VERSION "HNNBNNNYNNNNNNNNNNNNNNNNNNNNNNNNNNNNNNNNNN/4/%%%/4/'%**4NNN///"

NS_ :

BS_:

BU_: AAG BCM1 BCM2 ELV Gateway HDSG IEZS MFG MSBBR SAD SAD2 Schwerpanzer_Zusatz SitzMem_BFS SitzMem_FS SitzMem_HBFS SitzMem_HFS SitzMem_SR3 SpoilerSG TSG_BFS TSG_FS VSG VTS DK_Dummy

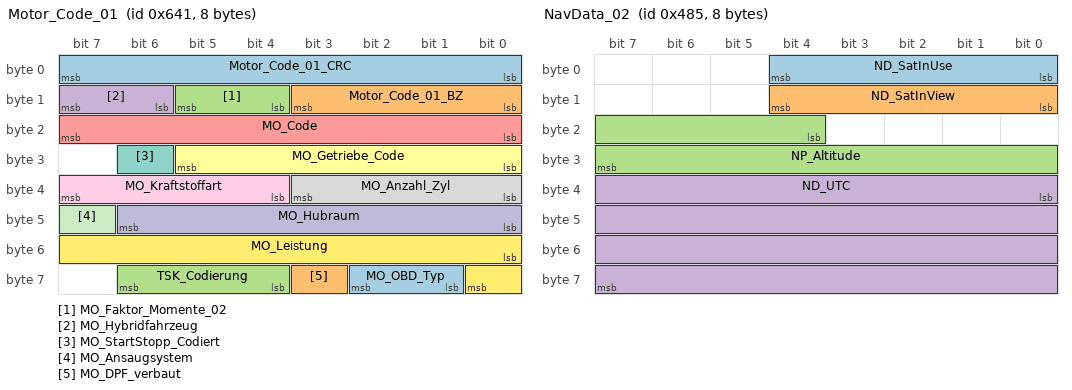
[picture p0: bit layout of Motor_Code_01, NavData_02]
BO_ 1601 Motor_Code_01: 8 Gateway
 SG_ Motor_Code_01_CRC : 0|8@1+ (1,0) [0|255] "" Vector__XXX
 SG_ Motor_Code_01_BZ : 8|4@1+ (1,0) [0|15] "" Vector__XXX
 SG_ MO_Faktor_Momente_02 : 12|2@1+ (1,0) [1|3] "Unit_NewtoMeter"  BCM1
 SG_ MO_Hybridfahrzeug : 14|2@1+ (1,0) [0|3] "" Vector__XXX
 SG_ MO_Code : 16|8@1+ (1,0) [0|255] "" Vector__XXX
 SG_ MO_Getriebe_Code : 24|6@1+ (1,0) [0|63] "" Vector__XXX
 SG_ MO_StartStopp_Codiert : 30|1@1+ (1,0) [0|1] "" Vector__XXX
 SG_ MO_Anzahl_Zyl : 32|4@1+ (1,0) [0|15] "" Vector__XXX
 SG_ MO_Kraftstoffart : 36|4@1+ (1,0) [0|15] ""  VTS
 SG_ MO_Hubraum : 40|7@1+ (0.1,0) [0|12.7] "Unit_Liter" Vector__XXX
 SG_ MO_Ansaugsystem : 47|1@1+ (1,0) [0|1] "" Vector__XXX
 SG_ MO_Leistung : 48|9@1+ (1,0) [0|511] "Unit_KiloWatt" Vector__XXX
 SG_ MO_OBD_Typ : 57|2@1+ (1,0) [0|3] "" Vector__XXX
 SG_ MO_DPF_verbaut : 59|1@1+ (1,0) [0|1] "" Vector__XXX
 SG_ TSK_Codierung : 60|3@1+ (1,0) [0|7] "" Vector__XXX

BO_ 394 Motor_Hybrid_11: 8 Gateway
 SG_ MO_Ablaufstatus : 12|4@1+ (1,0) [0|15] "" Vector__XXX
 SG_ MO_Ablaufstrg_Betriebszustand : 16|3@1+ (1,0) [0|7] "" Vector__XXX
 SG_ MO_Ablaufstrg_Zustand_VKM_Ist : 19|1@1+ (1,0) [0|1] "" Vector__XXX
 SG_ MO_Ablaufstrg_Kraftschluss_Ist : 20|1@1+ (1,0) [0|1] "" Vector__XXX
 SG_ MO_Ablaufstrg_Zustand_K0_Ist : 21|1@1+ (1,0) [0|1] "" Vector__XXX
 SG_ MO_Ablaufstrg_Kraftschluss2_Ist : 22|1@1+ (1,0) [0|1] "" Vector__XXX
 SG_ MO_Ablaufstrg_Zustand_VKM_Ziel : 24|1@1+ (1,0) [0|1] "" Vector__XXX
 SG_ MO_Ablaufstrg_Kraftschluss_Ziel : 25|1@1+ (1,0) [0|1] "" Vector__XXX
 SG_ MO_Ablaufstrg_Zustand_K0_Ziel : 26|1@1+ (1,0) [0|1] "" Vector__XXX
 SG_ MO_Ablaufstrg_Kraftschluss2_Ziel : 27|1@1+ (1,0) [0|1] "" Vector__XXX
 SG_ MO_Auth_Aufforderung_WFS : 29|1@1+ (1,0) [0|1] "" Vector__XXX
 SG_ MO_Start_Dynamik : 30|3@1+ (1,0) [0|7] "" Vector__XXX
 SG_ MO_Start_Art : 33|3@1+ (1,0) [0|7] ""  AAG,BCM1,BCM2
 SG_ MO_Abstellposition_02 : 36|8@1+ (2,0) [0|508] "Unit_DegreOfArc" Vector__XXX
 SG_ MO_Mom_Freiheit_Sekundaerachse : 44|1@1+ (1,0) [0|1] "" Vector__XXX
 SG_ MO_Nachlaufzeit_Kuehlerluefter : 45|6@1+ (15,0) [0|945] "Unit_Secon" Vector__XXX
 SG_ MO_Tankklappensteuerung : 51|2@1+ (1,0) [0|3] ""  BCM2
 SG_ MO_HYB_E_Faktor : 53|4@1+ (1,0) [0|15] "" Vector__XXX

BO_ 1157 NavData_02: 8 Gateway
 SG_ ND_SatInUse : 0|5@1+ (1,0) [0|29] "" Vector__XXX
 SG_ ND_SatInView : 8|5@1+ (1,0) [0|29] "" Vector__XXX
 SG_ NP_Altitude : 20|12@1+ (2,-500) [-500|7686] "Unit_Meter"  VTS
 SG_ ND_UTC : 32|32@1+ (1,0) [0|4294967293] "Unit_Secon" Vector__XXX

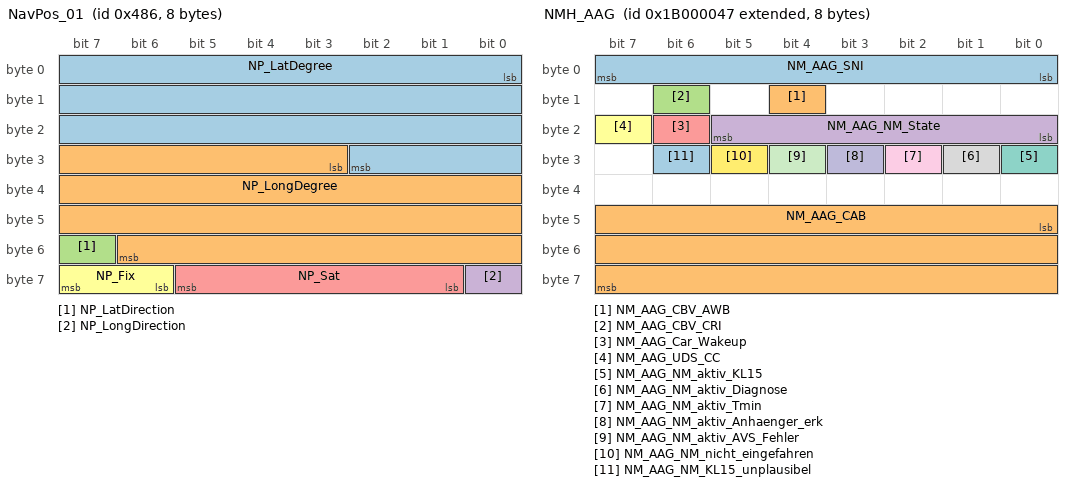
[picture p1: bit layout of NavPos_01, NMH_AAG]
BO_ 1158 NavPos_01: 8 Gateway
 SG_ NP_LatDegree : 0|27@1+ (1E-006,0) [0|90] "Unit_DegreOfArc"  VTS
 SG_ NP_LongDegree : 27|28@1+ (1E-006,0) [0|180] "Unit_DegreOfArc"  VTS
 SG_ NP_LatDirection : 55|1@1+ (1,0) [0|1] ""  VTS
 SG_ NP_LongDirection : 56|1@1+ (1,0) [0|1] ""  VTS
 SG_ NP_Sat : 57|5@1+ (1,0) [0|29] ""  VTS
 SG_ NP_Fix : 62|2@1+ (1,0) [0|3] ""  VTS

BO_ 2589283496 NavPos_02_Map_Matched: 8 Gateway
 SG_ POS_MUX M : 0|2@1+ (1,0) [0|3] ""  VTS
 SG_ POS_ODD_EVEN : 2|1@1+ (1,0) [0|1] ""  VTS
 SG_ POS_PosStati m0 : 3|4@1+ (1,0) [0|15] ""  VTS
 SG_ POS_Heading m1 : 4|12@1+ (0.1,0) [0|409.5] "Unit_DegreOfArc"  VTS
 SG_ POS_LatDirection m0 : 7|1@1+ (1,0) [0|1] ""  VTS
 SG_ POS_LatDegree m0 : 8|27@1+ (1E-006,0) [0|90] "Unit_DegreOfArc"  VTS
 SG_ POS_Last_GPS_Sync m1 : 16|14@1+ (1,0) [0|16383] "Unit_Secon"  VTS
 SG_ POS_Heading_Trust m1 : 30|2@1+ (1,0) [0|3] ""  VTS
 SG_ POS_UTC_REF m1 : 32|32@1+ (1,0) [0|4294967295] "Unit_Secon"  VTS
 SG_ POS_LongDirection m0 : 35|1@1+ (1,0) [0|1] ""  VTS
 SG_ POS_LongDegree m0 : 36|28@1+ (1E-006,0) [0|180] "Unit_DegreOfArc"  VTS

BO_ 2600468551 NMH_AAG: 8 AAG
 SG_ NM_AAG_SNI : 0|8@1+ (1,0) [0|255] ""  AAG,BCM1,BCM2,ELV,Gateway,HDSG,IEZS,MFG,MSBBR,SAD,SAD2,SitzMem_BFS,SitzMem_FS,SitzMem_HBFS,SitzMem_HFS,SitzMem_SR3,SpoilerSG,TSG_BFS,TSG_FS,VSG,VTS
 SG_ NM_AAG_CBV_AWB : 12|1@1+ (1,0) [0|1] ""  Gateway
 SG_ NM_AAG_CBV_CRI : 14|1@1+ (1,0) [0|1] ""  AAG,BCM1,BCM2,ELV,Gateway,HDSG,IEZS,MFG,MSBBR,SAD,SAD2,SitzMem_BFS,SitzMem_FS,SitzMem_HBFS,SitzMem_HFS,SitzMem_SR3,SpoilerSG,TSG_BFS,TSG_FS,VSG,VTS
 SG_ NM_AAG_NM_State : 16|6@1+ (1,0) [0|63] "" Vector__XXX
 SG_ NM_AAG_Car_Wakeup : 22|1@1+ (1,0) [0|1] ""  Gateway
 SG_ NM_AAG_UDS_CC : 23|1@1+ (1,0) [0|1] "" Vector__XXX
 SG_ NM_AAG_NM_aktiv_KL15 : 24|1@1+ (1,0) [0|1] "" Vector__XXX
 SG_ NM_AAG_NM_aktiv_Diagnose : 25|1@1+ (1,0) [0|1] "" Vector__XXX
 SG_ NM_AAG_NM_aktiv_Tmin : 26|1@1+ (1,0) [0|1] "" Vector__XXX
 SG_ NM_AAG_NM_aktiv_Anhaenger_erk : 27|1@1+ (1,0) [0|1] "" Vector__XXX
 SG_ NM_AAG_NM_aktiv_AVS_Fehler : 28|1@1+ (1,0) [0|1] "" Vector__XXX
 SG_ NM_AAG_NM_nicht_eingefahren : 29|1@1+ (1,0) [0|1] "" Vector__XXX
 SG_ NM_AAG_NM_KL15_unplausibel : 30|1@1+ (1,0) [0|1] "" Vector__XXX
 SG_ NM_AAG_CAB : 40|24@1+ (1,0) [0|16777215] ""  AAG,BCM1,BCM2,ELV,Gateway,HDSG,IEZS,MFG,MSBBR,SAD,SAD2,SitzMem_BFS,SitzMem_FS,SitzMem_HBFS,SitzMem_HFS,SitzMem_SR3,SpoilerSG,TSG_BFS,TSG_FS,VSG,VTS

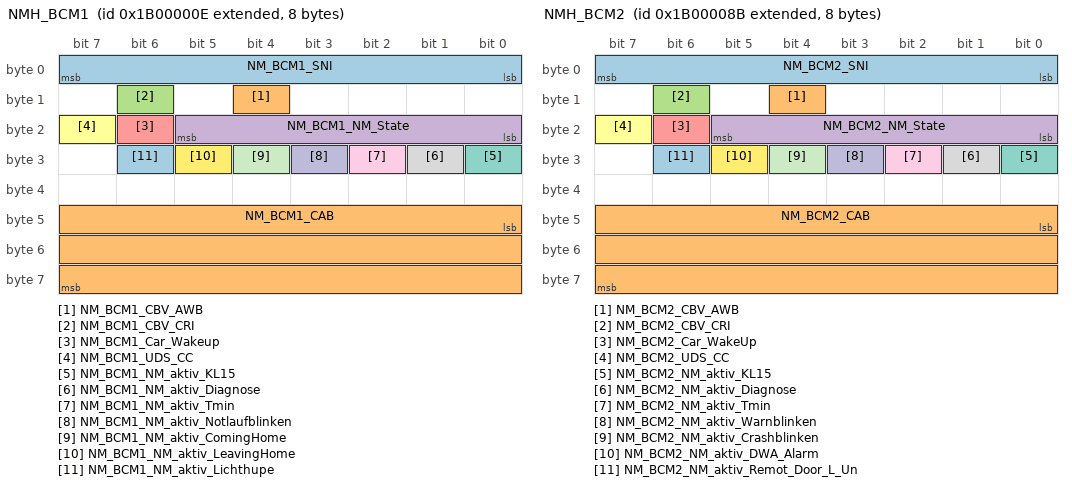
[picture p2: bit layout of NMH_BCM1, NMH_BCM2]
BO_ 2600468494 NMH_BCM1: 8 BCM1
 SG_ NM_BCM1_SNI : 0|8@1+ (1,0) [0|255] ""  AAG,BCM1,BCM2,ELV,Gateway,HDSG,IEZS,MFG,MSBBR,SAD,SAD2,SitzMem_BFS,SitzMem_FS,SitzMem_HBFS,SitzMem_HFS,SitzMem_SR3,SpoilerSG,TSG_BFS,TSG_FS,VSG,VTS
 SG_ NM_BCM1_CBV_AWB : 12|1@1+ (1,0) [0|1] ""  Gateway
 SG_ NM_BCM1_CBV_CRI : 14|1@1+ (1,0) [0|1] ""  AAG,BCM1,BCM2,ELV,Gateway,HDSG,IEZS,MFG,MSBBR,SAD,SAD2,SitzMem_BFS,SitzMem_FS,SitzMem_HBFS,SitzMem_HFS,SitzMem_SR3,SpoilerSG,TSG_BFS,TSG_FS,VSG,VTS
 SG_ NM_BCM1_NM_State : 16|6@1+ (1,0) [0|63] "" Vector__XXX
 SG_ NM_BCM1_Car_Wakeup : 22|1@1+ (1,0) [0|1] ""  Gateway
 SG_ NM_BCM1_UDS_CC : 23|1@1+ (1,0) [0|1] "" Vector__XXX
 SG_ NM_BCM1_NM_aktiv_KL15 : 24|1@1+ (1,0) [0|1] "" Vector__XXX
 SG_ NM_BCM1_NM_aktiv_Diagnose : 25|1@1+ (1,0) [0|1] "" Vector__XXX
 SG_ NM_BCM1_NM_aktiv_Tmin : 26|1@1+ (1,0) [0|1] "" Vector__XXX
 SG_ NM_BCM1_NM_aktiv_Notlaufblinken : 27|1@1+ (1,0) [0|1] "" Vector__XXX
 SG_ NM_BCM1_NM_aktiv_ComingHome : 28|1@1+ (1,0) [0|1] "" Vector__XXX
 SG_ NM_BCM1_NM_aktiv_LeavingHome : 29|1@1+ (1,0) [0|1] "" Vector__XXX
 SG_ NM_BCM1_NM_aktiv_Lichthupe : 30|1@1+ (1,0) [0|1] "" Vector__XXX
 SG_ NM_BCM1_CAB : 40|24@1+ (1,0) [0|16777215] ""  AAG,BCM1,BCM2,ELV,Gateway,HDSG,IEZS,MFG,MSBBR,SAD,SAD2,SitzMem_BFS,SitzMem_FS,SitzMem_HBFS,SitzMem_HFS,SitzMem_SR3,SpoilerSG,TSG_BFS,TSG_FS,VSG,VTS

BO_ 2600468619 NMH_BCM2: 8 BCM2
 SG_ NM_BCM2_SNI : 0|8@1+ (1,0) [0|255] ""  AAG,BCM1,BCM2,ELV,Gateway,HDSG,IEZS,MFG,MSBBR,SAD,SAD2,SitzMem_BFS,SitzMem_FS,SitzMem_HBFS,SitzMem_HFS,SitzMem_SR3,SpoilerSG,TSG_BFS,TSG_FS,VSG,VTS
 SG_ NM_BCM2_CBV_AWB : 12|1@1+ (1,0) [0|1] ""  Gateway
 SG_ NM_BCM2_CBV_CRI : 14|1@1+ (1,0) [0|1] ""  AAG,BCM1,BCM2,ELV,Gateway,HDSG,IEZS,MFG,MSBBR,SAD,SAD2,SitzMem_BFS,SitzMem_FS,SitzMem_HBFS,SitzMem_HFS,SitzMem_SR3,SpoilerSG,TSG_BFS,TSG_FS,VSG,VTS
 SG_ NM_BCM2_NM_State : 16|6@1+ (1,0) [0|63] "" Vector__XXX
 SG_ NM_BCM2_Car_WakeUp : 22|1@1+ (1,0) [0|1] ""  Gateway
 SG_ NM_BCM2_UDS_CC : 23|1@1+ (1,0) [0|1] "" Vector__XXX
 SG_ NM_BCM2_NM_aktiv_KL15 : 24|1@1+ (1,0) [0|1] "" Vector__XXX
 SG_ NM_BCM2_NM_aktiv_Diagnose : 25|1@1+ (1,0) [0|1] "" Vector__XXX
 SG_ NM_BCM2_NM_aktiv_Tmin : 26|1@1+ (1,0) [0|1] "" Vector__XXX
 SG_ NM_BCM2_NM_aktiv_Warnblinken : 27|1@1+ (1,0) [0|1] "" Vector__XXX
 SG_ NM_BCM2_NM_aktiv_Crashblinken : 28|1@1+ (1,0) [0|1] "" Vector__XXX
 SG_ NM_BCM2_NM_aktiv_DWA_Alarm : 29|1@1+ (1,0) [0|1] "" Vector__XXX
 SG_ NM_BCM2_NM_aktiv_Remot_Door_L_Un : 30|1@1+ (1,0) [0|1] "" Vector__XXX
 SG_ NM_BCM2_CAB : 40|24@1+ (1,0) [0|16777215] ""  AAG,BCM1,BCM2,ELV,Gateway,HDSG,IEZS,MFG,MSBBR,SAD,SAD2,SitzMem_BFS,SitzMem_FS,SitzMem_HBFS,SitzMem_HFS,SitzMem_SR3,SpoilerSG,TSG_BFS,TSG_FS,VSG,VTS

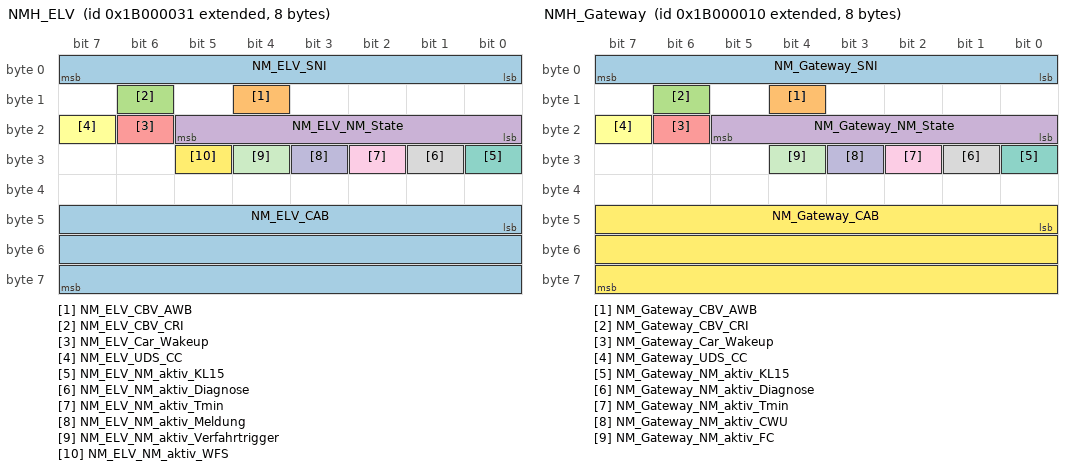
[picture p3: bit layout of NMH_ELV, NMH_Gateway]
BO_ 2600468529 NMH_ELV: 8 ELV
 SG_ NM_ELV_SNI : 0|8@1+ (1,0) [0|255] ""  AAG,BCM1,BCM2,ELV,Gateway,HDSG,IEZS,MFG,MSBBR,SAD,SAD2,SitzMem_BFS,SitzMem_FS,SitzMem_HBFS,SitzMem_HFS,SitzMem_SR3,SpoilerSG,TSG_BFS,TSG_FS,VSG,VTS
 SG_ NM_ELV_CBV_AWB : 12|1@1+ (1,0) [0|1] ""  Gateway
 SG_ NM_ELV_CBV_CRI : 14|1@1+ (1,0) [0|1] ""  AAG,BCM1,BCM2,ELV,Gateway,HDSG,IEZS,MFG,MSBBR,SAD,SAD2,SitzMem_BFS,SitzMem_FS,SitzMem_HBFS,SitzMem_HFS,SitzMem_SR3,SpoilerSG,TSG_BFS,TSG_FS,VSG,VTS
 SG_ NM_ELV_NM_State : 16|6@1+ (1,0) [0|63] "" Vector__XXX
 SG_ NM_ELV_Car_Wakeup : 22|1@1+ (1,0) [0|1] ""  Gateway
 SG_ NM_ELV_UDS_CC : 23|1@1+ (1,0) [0|1] "" Vector__XXX
 SG_ NM_ELV_NM_aktiv_KL15 : 24|1@1+ (1,0) [0|1] "" Vector__XXX
 SG_ NM_ELV_NM_aktiv_Diagnose : 25|1@1+ (1,0) [0|1] "" Vector__XXX
 SG_ NM_ELV_NM_aktiv_Tmin : 26|1@1+ (1,0) [0|1] "" Vector__XXX
 SG_ NM_ELV_NM_aktiv_Meldung : 27|1@1+ (1,0) [0|1] "" Vector__XXX
 SG_ NM_ELV_NM_aktiv_Verfahrtrigger : 28|1@1+ (1,0) [0|1] "" Vector__XXX
 SG_ NM_ELV_NM_aktiv_WFS : 29|1@1+ (1,0) [0|1] "" Vector__XXX
 SG_ NM_ELV_CAB : 40|24@1+ (1,0) [0|16777215] ""  AAG,BCM1,BCM2,ELV,Gateway,HDSG,IEZS,MFG,MSBBR,SAD,SAD2,SitzMem_BFS,SitzMem_FS,SitzMem_HBFS,SitzMem_HFS,SitzMem_SR3,SpoilerSG,TSG_BFS,TSG_FS,VSG,VTS

BO_ 2600468496 NMH_Gateway: 8 Gateway
 SG_ NM_Gateway_SNI : 0|8@1+ (1,0) [0|255] ""  AAG,BCM1,BCM2,ELV,Gateway,HDSG,IEZS,MFG,MSBBR,SAD,SAD2,SitzMem_BFS,SitzMem_FS,SitzMem_HBFS,SitzMem_HFS,SitzMem_SR3,SpoilerSG,TSG_BFS,TSG_FS,VSG,VTS
 SG_ NM_Gateway_CBV_AWB : 12|1@1+ (1,0) [0|1] "" Vector__XXX
 SG_ NM_Gateway_CBV_CRI : 14|1@1+ (1,0) [0|1] ""  AAG,BCM1,BCM2,ELV,Gateway,HDSG,IEZS,MFG,MSBBR,SAD,SAD2,SitzMem_BFS,SitzMem_FS,SitzMem_HBFS,SitzMem_HFS,SitzMem_SR3,SpoilerSG,TSG_BFS,TSG_FS,VSG,VTS
 SG_ NM_Gateway_NM_State : 16|6@1+ (1,0) [0|63] "" Vector__XXX
 SG_ NM_Gateway_Car_Wakeup : 22|1@1+ (1,0) [0|1] "" Vector__XXX
 SG_ NM_Gateway_UDS_CC : 23|1@1+ (1,0) [0|1] "" Vector__XXX
 SG_ NM_Gateway_NM_aktiv_KL15 : 24|1@1+ (1,0) [0|1] "" Vector__XXX
 SG_ NM_Gateway_NM_aktiv_Diagnose : 25|1@1+ (1,0) [0|1] "" Vector__XXX
 SG_ NM_Gateway_NM_aktiv_Tmin : 26|1@1+ (1,0) [0|1] "" Vector__XXX
 SG_ NM_Gateway_NM_aktiv_CWU : 27|1@1+ (1,0) [0|1] "" Vector__XXX
 SG_ NM_Gateway_NM_aktiv_FC : 28|1@1+ (1,0) [0|1] "" Vector__XXX
 SG_ NM_Gateway_CAB : 40|24@1+ (1,0) [0|16777215] ""  AAG,BCM1,BCM2,ELV,Gateway,HDSG,IEZS,MFG,MSBBR,SAD,SAD2,SitzMem_BFS,SitzMem_FS,SitzMem_HBFS,SitzMem_HFS,SitzMem_SR3,SpoilerSG,TSG_BFS,TSG_FS,VSG,VTS

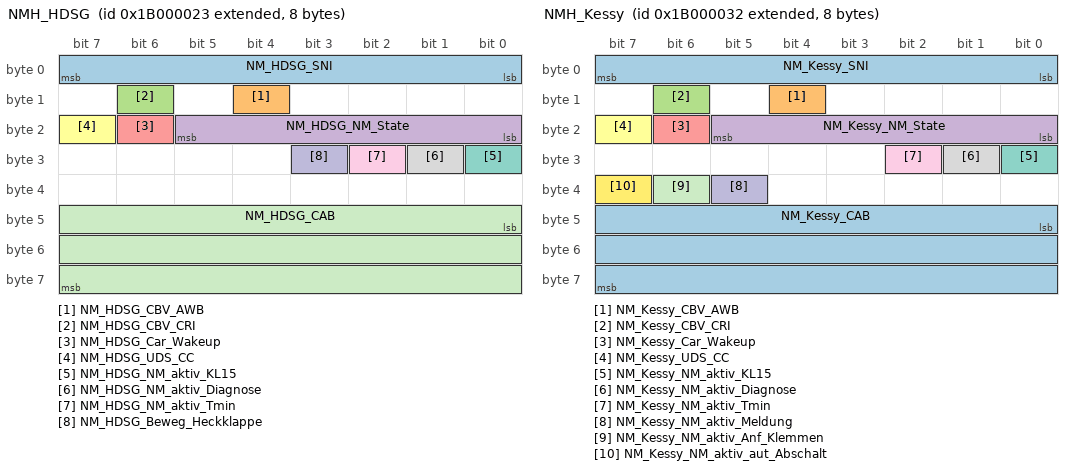
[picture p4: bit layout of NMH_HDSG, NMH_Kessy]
BO_ 2600468515 NMH_HDSG: 8 HDSG
 SG_ NM_HDSG_SNI : 0|8@1+ (1,0) [0|255] ""  AAG,BCM1,BCM2,ELV,Gateway,HDSG,IEZS,MFG,MSBBR,SAD,SAD2,SitzMem_BFS,SitzMem_FS,SitzMem_HBFS,SitzMem_HFS,SitzMem_SR3,SpoilerSG,TSG_BFS,TSG_FS,VSG,VTS
 SG_ NM_HDSG_CBV_AWB : 12|1@1+ (1,0) [0|1] ""  Gateway
 SG_ NM_HDSG_CBV_CRI : 14|1@1+ (1,0) [0|1] ""  AAG,BCM1,BCM2,ELV,Gateway,HDSG,IEZS,MFG,MSBBR,SAD,SAD2,SitzMem_BFS,SitzMem_FS,SitzMem_HBFS,SitzMem_HFS,SitzMem_SR3,SpoilerSG,TSG_BFS,TSG_FS,VSG,VTS
 SG_ NM_HDSG_NM_State : 16|6@1+ (1,0) [0|63] "" Vector__XXX
 SG_ NM_HDSG_Car_Wakeup : 22|1@1+ (1,0) [0|1] ""  Gateway
 SG_ NM_HDSG_UDS_CC : 23|1@1+ (1,0) [0|1] "" Vector__XXX
 SG_ NM_HDSG_NM_aktiv_KL15 : 24|1@1+ (1,0) [0|1] "" Vector__XXX
 SG_ NM_HDSG_NM_aktiv_Diagnose : 25|1@1+ (1,0) [0|1] "" Vector__XXX
 SG_ NM_HDSG_NM_aktiv_Tmin : 26|1@1+ (1,0) [0|1] "" Vector__XXX
 SG_ NM_HDSG_Beweg_Heckklappe : 27|1@1+ (1,0) [0|1] "" Vector__XXX
 SG_ NM_HDSG_CAB : 40|24@1+ (1,0) [0|16777215] ""  AAG,BCM1,BCM2,ELV,Gateway,HDSG,IEZS,MFG,MSBBR,SAD,SAD2,SitzMem_BFS,SitzMem_FS,SitzMem_HBFS,SitzMem_HFS,SitzMem_SR3,SpoilerSG,TSG_BFS,TSG_FS,VSG,VTS

BO_ 2600468530 NMH_Kessy: 8 IEZS
 SG_ NM_Kessy_SNI : 0|8@1+ (1,0) [0|255] ""  AAG,BCM1,BCM2,ELV,Gateway,HDSG,IEZS,MFG,MSBBR,SAD,SAD2,SitzMem_BFS,SitzMem_FS,SitzMem_HBFS,SitzMem_HFS,SitzMem_SR3,SpoilerSG,TSG_BFS,TSG_FS,VSG,VTS
 SG_ NM_Kessy_CBV_AWB : 12|1@1+ (1,0) [0|1] ""  Gateway
 SG_ NM_Kessy_CBV_CRI : 14|1@1+ (1,0) [0|1] ""  AAG,BCM1,BCM2,ELV,Gateway,HDSG,IEZS,MFG,MSBBR,SAD,SAD2,SitzMem_BFS,SitzMem_FS,SitzMem_HBFS,SitzMem_HFS,SitzMem_SR3,SpoilerSG,TSG_BFS,TSG_FS,VSG,VTS
 SG_ NM_Kessy_NM_State : 16|6@1+ (1,0) [0|63] "" Vector__XXX
 SG_ NM_Kessy_Car_Wakeup : 22|1@1+ (1,0) [0|1] ""  Gateway
 SG_ NM_Kessy_UDS_CC : 23|1@1+ (1,0) [0|1] "" Vector__XXX
 SG_ NM_Kessy_NM_aktiv_KL15 : 24|1@1+ (1,0) [0|1] "" Vector__XXX
 SG_ NM_Kessy_NM_aktiv_Diagnose : 25|1@1+ (1,0) [0|1] "" Vector__XXX
 SG_ NM_Kessy_NM_aktiv_Tmin : 26|1@1+ (1,0) [0|1] "" Vector__XXX
 SG_ NM_Kessy_NM_aktiv_Meldung : 37|1@1+ (1,0) [0|1] "" Vector__XXX
 SG_ NM_Kessy_NM_aktiv_Anf_Klemmen : 38|1@1+ (1,0) [0|1] "" Vector__XXX
 SG_ NM_Kessy_NM_aktiv_aut_Abschalt : 39|1@1+ (1,0) [0|1] "" Vector__XXX
 SG_ NM_Kessy_CAB : 40|24@1+ (1,0) [0|16777215] ""  AAG,BCM1,BCM2,ELV,Gateway,HDSG,IEZS,MFG,MSBBR,SAD,SAD2,SitzMem_BFS,SitzMem_FS,SitzMem_HBFS,SitzMem_HFS,SitzMem_SR3,SpoilerSG,TSG_BFS,TSG_FS,VSG,VTS

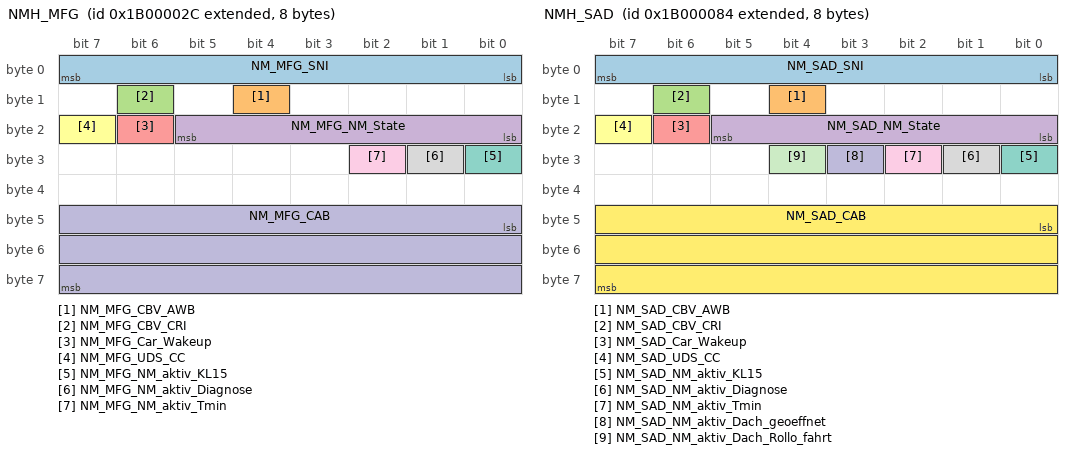
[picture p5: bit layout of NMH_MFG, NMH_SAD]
BO_ 2600468524 NMH_MFG: 8 MFG
 SG_ NM_MFG_SNI : 0|8@1+ (1,0) [0|255] ""  AAG,BCM1,BCM2,ELV,Gateway,HDSG,IEZS,MFG,MSBBR,SAD,SAD2,SitzMem_BFS,SitzMem_FS,SitzMem_HBFS,SitzMem_HFS,SitzMem_SR3,SpoilerSG,TSG_BFS,TSG_FS,VSG,VTS
 SG_ NM_MFG_CBV_AWB : 12|1@1+ (1,0) [0|1] ""  Gateway
 SG_ NM_MFG_CBV_CRI : 14|1@1+ (1,0) [0|1] ""  AAG,BCM1,BCM2,ELV,Gateway,HDSG,IEZS,MFG,MSBBR,SAD,SAD2,SitzMem_BFS,SitzMem_FS,SitzMem_HBFS,SitzMem_HFS,SitzMem_SR3,SpoilerSG,TSG_BFS,TSG_FS,VSG,VTS
 SG_ NM_MFG_NM_State : 16|6@1+ (1,0) [0|63] "" Vector__XXX
 SG_ NM_MFG_Car_Wakeup : 22|1@1+ (1,0) [0|1] ""  Gateway
 SG_ NM_MFG_UDS_CC : 23|1@1+ (1,0) [0|1] "" Vector__XXX
 SG_ NM_MFG_NM_aktiv_KL15 : 24|1@1+ (1,0) [0|1] "" Vector__XXX
 SG_ NM_MFG_NM_aktiv_Diagnose : 25|1@1+ (1,0) [0|1] "" Vector__XXX
 SG_ NM_MFG_NM_aktiv_Tmin : 26|1@1+ (1,0) [0|1] "" Vector__XXX
 SG_ NM_MFG_CAB : 40|24@1+ (1,0) [0|16777215] ""  AAG,BCM1,BCM2,ELV,Gateway,HDSG,IEZS,MFG,MSBBR,SAD,SAD2,SitzMem_BFS,SitzMem_FS,SitzMem_HBFS,SitzMem_HFS,SitzMem_SR3,SpoilerSG,TSG_BFS,TSG_FS,VSG,VTS

BO_ 2600468612 NMH_SAD: 8 SAD
 SG_ NM_SAD_SNI : 0|8@1+ (1,0) [0|255] ""  AAG,BCM1,BCM2,ELV,Gateway,HDSG,IEZS,MFG,MSBBR,SAD,SAD2,SitzMem_BFS,SitzMem_FS,SitzMem_HBFS,SitzMem_HFS,SitzMem_SR3,SpoilerSG,TSG_BFS,TSG_FS,VSG,VTS
 SG_ NM_SAD_CBV_AWB : 12|1@1+ (1,0) [0|1] ""  Gateway
 SG_ NM_SAD_CBV_CRI : 14|1@1+ (1,0) [0|1] ""  AAG,BCM1,BCM2,ELV,Gateway,HDSG,IEZS,MFG,MSBBR,SAD,SAD2,SitzMem_BFS,SitzMem_FS,SitzMem_HBFS,SitzMem_HFS,SitzMem_SR3,SpoilerSG,TSG_BFS,TSG_FS,VSG,VTS
 SG_ NM_SAD_NM_State : 16|6@1+ (1,0) [0|63] "" Vector__XXX
 SG_ NM_SAD_Car_Wakeup : 22|1@1+ (1,0) [0|1] ""  Gateway
 SG_ NM_SAD_UDS_CC : 23|1@1+ (1,0) [0|1] "" Vector__XXX
 SG_ NM_SAD_NM_aktiv_KL15 : 24|1@1+ (1,0) [0|1] "" Vector__XXX
 SG_ NM_SAD_NM_aktiv_Diagnose : 25|1@1+ (1,0) [0|1] "" Vector__XXX
 SG_ NM_SAD_NM_aktiv_Tmin : 26|1@1+ (1,0) [0|1] "" Vector__XXX
 SG_ NM_SAD_NM_aktiv_Dach_geoeffnet : 27|1@1+ (1,0) [0|1] "" Vector__XXX
 SG_ NM_SAD_NM_aktiv_Dach_Rollo_fahrt : 28|1@1+ (1,0) [0|1] "" Vector__XXX
 SG_ NM_SAD_CAB : 40|24@1+ (1,0) [0|16777215] ""  AAG,BCM1,BCM2,ELV,Gateway,HDSG,IEZS,MFG,MSBBR,SAD,SAD2,SitzMem_BFS,SitzMem_FS,SitzMem_HBFS,SitzMem_HFS,SitzMem_SR3,SpoilerSG,TSG_BFS,TSG_FS,VSG,VTS

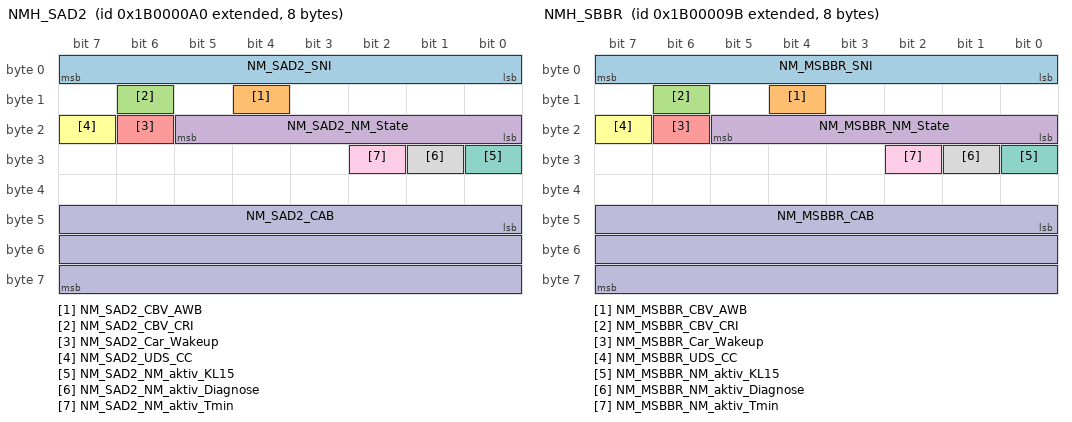
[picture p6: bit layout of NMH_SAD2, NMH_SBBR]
BO_ 2600468640 NMH_SAD2: 8 SAD2
 SG_ NM_SAD2_SNI : 0|8@1+ (1,0) [0|255] ""  AAG,BCM1,BCM2,ELV,Gateway,HDSG,IEZS,MFG,MSBBR,SAD,SAD2,SitzMem_BFS,SitzMem_FS,SitzMem_HBFS,SitzMem_HFS,SitzMem_SR3,SpoilerSG,TSG_BFS,TSG_FS,VSG,VTS
 SG_ NM_SAD2_CBV_AWB : 12|1@1+ (1,0) [0|1] "" Vector__XXX
 SG_ NM_SAD2_CBV_CRI : 14|1@1+ (1,0) [0|1] ""  AAG,BCM1,BCM2,ELV,Gateway,HDSG,IEZS,MFG,MSBBR,SAD,SAD2,SitzMem_BFS,SitzMem_FS,SitzMem_HBFS,SitzMem_HFS,SitzMem_SR3,SpoilerSG,TSG_BFS,TSG_FS,VSG,VTS
 SG_ NM_SAD2_NM_State : 16|6@1+ (1,0) [0|63] "" Vector__XXX
 SG_ NM_SAD2_Car_Wakeup : 22|1@1+ (1,0) [0|1] "" Vector__XXX
 SG_ NM_SAD2_UDS_CC : 23|1@1+ (1,0) [0|1] "" Vector__XXX
 SG_ NM_SAD2_NM_aktiv_KL15 : 24|1@1+ (1,0) [0|1] "" Vector__XXX
 SG_ NM_SAD2_NM_aktiv_Diagnose : 25|1@1+ (1,0) [0|1] "" Vector__XXX
 SG_ NM_SAD2_NM_aktiv_Tmin : 26|1@1+ (1,0) [0|1] "" Vector__XXX
 SG_ NM_SAD2_CAB : 40|24@1+ (1,0) [0|16777215] ""  AAG,BCM1,BCM2,ELV,Gateway,HDSG,IEZS,MFG,MSBBR,SAD,SAD2,SitzMem_BFS,SitzMem_FS,SitzMem_HBFS,SitzMem_HFS,SitzMem_SR3,SpoilerSG,TSG_BFS,TSG_FS,VSG,VTS

BO_ 2600468635 NMH_SBBR: 8 MSBBR
 SG_ NM_MSBBR_SNI : 0|8@1+ (1,0) [0|255] ""  AAG,BCM1,BCM2,ELV,Gateway,HDSG,IEZS,MFG,MSBBR,SAD,SAD2,SitzMem_BFS,SitzMem_FS,SitzMem_HBFS,SitzMem_HFS,SitzMem_SR3,SpoilerSG,TSG_BFS,TSG_FS,VSG,VTS
 SG_ NM_MSBBR_CBV_AWB : 12|1@1+ (1,0) [0|1] "" Vector__XXX
 SG_ NM_MSBBR_CBV_CRI : 14|1@1+ (1,0) [0|1] ""  AAG,BCM1,BCM2,ELV,Gateway,HDSG,IEZS,MFG,MSBBR,SAD,SAD2,SitzMem_BFS,SitzMem_FS,SitzMem_HBFS,SitzMem_HFS,SitzMem_SR3,SpoilerSG,TSG_BFS,TSG_FS,VSG,VTS
 SG_ NM_MSBBR_NM_State : 16|6@1+ (1,0) [0|63] "" Vector__XXX
 SG_ NM_MSBBR_Car_Wakeup : 22|1@1+ (1,0) [0|1] "" Vector__XXX
 SG_ NM_MSBBR_UDS_CC : 23|1@1+ (1,0) [0|1] "" Vector__XXX
 SG_ NM_MSBBR_NM_aktiv_KL15 : 24|1@1+ (1,0) [0|1] "" Vector__XXX
 SG_ NM_MSBBR_NM_aktiv_Diagnose : 25|1@1+ (1,0) [0|1] "" Vector__XXX
 SG_ NM_MSBBR_NM_aktiv_Tmin : 26|1@1+ (1,0) [0|1] "" Vector__XXX
 SG_ NM_MSBBR_CAB : 40|24@1+ (1,0) [0|16777215] ""  AAG,BCM1,BCM2,ELV,Gateway,HDSG,IEZS,MFG,MSBBR,SAD,SAD2,SitzMem_BFS,SitzMem_FS,SitzMem_HBFS,SitzMem_HFS,SitzMem_SR3,SpoilerSG,TSG_BFS,TSG_FS,VSG,VTS

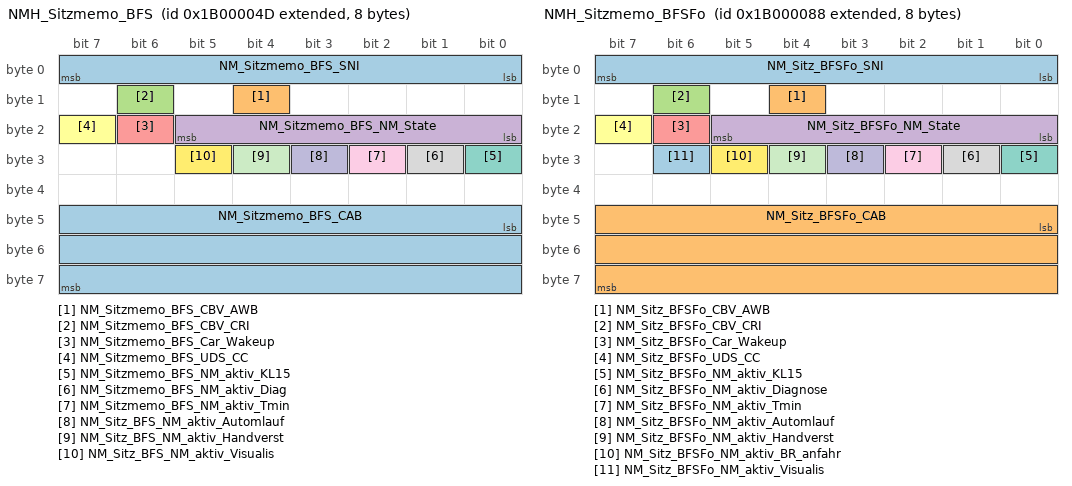
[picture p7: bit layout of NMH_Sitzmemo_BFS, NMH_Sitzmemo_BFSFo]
BO_ 2600468557 NMH_Sitzmemo_BFS: 8 SitzMem_BFS
 SG_ NM_Sitzmemo_BFS_SNI : 0|8@1+ (1,0) [0|255] ""  AAG,BCM1,BCM2,ELV,Gateway,HDSG,IEZS,MFG,MSBBR,SAD,SAD2,SitzMem_BFS,SitzMem_FS,SitzMem_HBFS,SitzMem_HFS,SitzMem_SR3,SpoilerSG,TSG_BFS,TSG_FS,VSG,VTS
 SG_ NM_Sitzmemo_BFS_CBV_AWB : 12|1@1+ (1,0) [0|1] ""  Gateway
 SG_ NM_Sitzmemo_BFS_CBV_CRI : 14|1@1+ (1,0) [0|1] ""  AAG,BCM1,BCM2,ELV,Gateway,HDSG,IEZS,MFG,MSBBR,SAD,SAD2,SitzMem_BFS,SitzMem_FS,SitzMem_HBFS,SitzMem_HFS,SitzMem_SR3,SpoilerSG,TSG_BFS,TSG_FS,VSG,VTS
 SG_ NM_Sitzmemo_BFS_NM_State : 16|6@1+ (1,0) [0|63] "" Vector__XXX
 SG_ NM_Sitzmemo_BFS_Car_Wakeup : 22|1@1+ (1,0) [0|1] ""  Gateway
 SG_ NM_Sitzmemo_BFS_UDS_CC : 23|1@1+ (1,0) [0|1] "" Vector__XXX
 SG_ NM_Sitzmemo_BFS_NM_aktiv_KL15 : 24|1@1+ (1,0) [0|1] "" Vector__XXX
 SG_ NM_Sitzmemo_BFS_NM_aktiv_Diag : 25|1@1+ (1,0) [0|1] "" Vector__XXX
 SG_ NM_Sitzmemo_BFS_NM_aktiv_Tmin : 26|1@1+ (1,0) [0|1] "" Vector__XXX
 SG_ NM_Sitz_BFS_NM_aktiv_Automlauf : 27|1@1+ (1,0) [0|1] "" Vector__XXX
 SG_ NM_Sitz_BFS_NM_aktiv_Handverst : 28|1@1+ (1,0) [0|1] "" Vector__XXX
 SG_ NM_Sitz_BFS_NM_aktiv_Visualis : 29|1@1+ (1,0) [0|1] "" Vector__XXX
 SG_ NM_Sitzmemo_BFS_CAB : 40|24@1+ (1,0) [0|16777215] ""  AAG,BCM1,BCM2,ELV,Gateway,HDSG,IEZS,MFG,MSBBR,SAD,SAD2,SitzMem_BFS,SitzMem_FS,SitzMem_HBFS,SitzMem_HFS,SitzMem_SR3,SpoilerSG,TSG_BFS,TSG_FS,VSG,VTS

BO_ 2600468616 NMH_Sitzmemo_BFSFo: 8 SitzMem_HBFS
 SG_ NM_Sitz_BFSFo_SNI : 0|8@1+ (1,0) [0|255] ""  AAG,BCM1,BCM2,ELV,Gateway,HDSG,IEZS,MFG,MSBBR,SAD,SAD2,SitzMem_BFS,SitzMem_FS,SitzMem_HBFS,SitzMem_HFS,SitzMem_SR3,SpoilerSG,TSG_BFS,TSG_FS,VSG,VTS
 SG_ NM_Sitz_BFSFo_CBV_AWB : 12|1@1+ (1,0) [0|1] ""  Gateway
 SG_ NM_Sitz_BFSFo_CBV_CRI : 14|1@1+ (1,0) [0|1] ""  AAG,BCM1,BCM2,ELV,Gateway,HDSG,IEZS,MFG,MSBBR,SAD,SAD2,SitzMem_BFS,SitzMem_FS,SitzMem_HBFS,SitzMem_HFS,SitzMem_SR3,SpoilerSG,TSG_BFS,TSG_FS,VSG,VTS
 SG_ NM_Sitz_BFSFo_NM_State : 16|6@1+ (1,0) [0|63] "" Vector__XXX
 SG_ NM_Sitz_BFSFo_Car_Wakeup : 22|1@1+ (1,0) [0|1] ""  Gateway
 SG_ NM_Sitz_BFSFo_UDS_CC : 23|1@1+ (1,0) [0|1] "" Vector__XXX
 SG_ NM_Sitz_BFSFo_NM_aktiv_KL15 : 24|1@1+ (1,0) [0|1] "" Vector__XXX
 SG_ NM_Sitz_BFSFo_NM_aktiv_Diagnose : 25|1@1+ (1,0) [0|1] "" Vector__XXX
 SG_ NM_Sitz_BFSFo_NM_aktiv_Tmin : 26|1@1+ (1,0) [0|1] "" Vector__XXX
 SG_ NM_Sitz_BFSFo_NM_aktiv_Automlauf : 27|1@1+ (1,0) [0|1] "" Vector__XXX
 SG_ NM_Sitz_BFSFo_NM_aktiv_Handverst : 28|1@1+ (1,0) [0|1] "" Vector__XXX
 SG_ NM_Sitz_BFSFo_NM_aktiv_BR_anfahr : 29|1@1+ (1,0) [0|1] "" Vector__XXX
 SG_ NM_Sitz_BFSFo_NM_aktiv_Visualis : 30|1@1+ (1,0) [0|1] "" Vector__XXX
 SG_ NM_Sitz_BFSFo_CAB : 40|24@1+ (1,0) [0|16777215] ""  AAG,BCM1,BCM2,ELV,Gateway,HDSG,IEZS,MFG,MSBBR,SAD,SAD2,SitzMem_BFS,SitzMem_FS,SitzMem_HBFS,SitzMem_HFS,SitzMem_SR3,SpoilerSG,TSG_BFS,TSG_FS,VSG,VTS

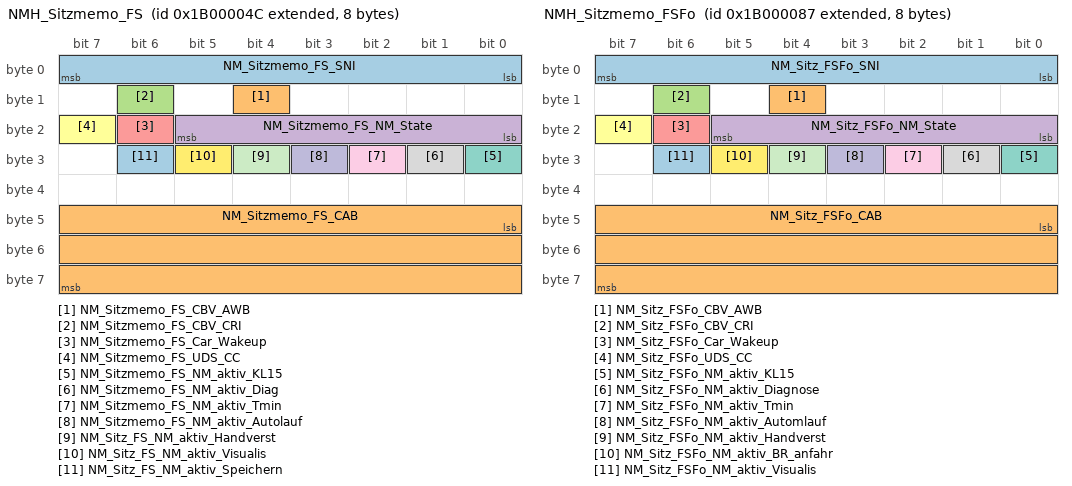
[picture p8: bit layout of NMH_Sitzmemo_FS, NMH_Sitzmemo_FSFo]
BO_ 2600468556 NMH_Sitzmemo_FS: 8 SitzMem_FS
 SG_ NM_Sitzmemo_FS_SNI : 0|8@1+ (1,0) [0|255] ""  AAG,BCM1,BCM2,ELV,Gateway,HDSG,IEZS,MFG,MSBBR,SAD,SAD2,SitzMem_BFS,SitzMem_FS,SitzMem_HBFS,SitzMem_HFS,SitzMem_SR3,SpoilerSG,TSG_BFS,TSG_FS,VSG,VTS
 SG_ NM_Sitzmemo_FS_CBV_AWB : 12|1@1+ (1,0) [0|1] ""  Gateway
 SG_ NM_Sitzmemo_FS_CBV_CRI : 14|1@1+ (1,0) [0|1] ""  AAG,BCM1,BCM2,ELV,Gateway,HDSG,IEZS,MFG,MSBBR,SAD,SAD2,SitzMem_BFS,SitzMem_FS,SitzMem_HBFS,SitzMem_HFS,SitzMem_SR3,SpoilerSG,TSG_BFS,TSG_FS,VSG,VTS
 SG_ NM_Sitzmemo_FS_NM_State : 16|6@1+ (1,0) [0|63] "" Vector__XXX
 SG_ NM_Sitzmemo_FS_Car_Wakeup : 22|1@1+ (1,0) [0|1] ""  Gateway
 SG_ NM_Sitzmemo_FS_UDS_CC : 23|1@1+ (1,0) [0|1] "" Vector__XXX
 SG_ NM_Sitzmemo_FS_NM_aktiv_KL15 : 24|1@1+ (1,0) [0|1] "" Vector__XXX
 SG_ NM_Sitzmemo_FS_NM_aktiv_Diag : 25|1@1+ (1,0) [0|1] "" Vector__XXX
 SG_ NM_Sitzmemo_FS_NM_aktiv_Tmin : 26|1@1+ (1,0) [0|1] "" Vector__XXX
 SG_ NM_Sitzmemo_FS_NM_aktiv_Autolauf : 27|1@1+ (1,0) [0|1] "" Vector__XXX
 SG_ NM_Sitz_FS_NM_aktiv_Handverst : 28|1@1+ (1,0) [0|1] "" Vector__XXX
 SG_ NM_Sitz_FS_NM_aktiv_Visualis : 29|1@1+ (1,0) [0|1] "" Vector__XXX
 SG_ NM_Sitz_FS_NM_aktiv_Speichern : 30|1@1+ (1,0) [0|1] "" Vector__XXX
 SG_ NM_Sitzmemo_FS_CAB : 40|24@1+ (1,0) [0|16777215] ""  AAG,BCM1,BCM2,ELV,Gateway,HDSG,IEZS,MFG,MSBBR,SAD,SAD2,SitzMem_BFS,SitzMem_FS,SitzMem_HBFS,SitzMem_HFS,SitzMem_SR3,SpoilerSG,TSG_BFS,TSG_FS,VSG,VTS

BO_ 2600468615 NMH_Sitzmemo_FSFo: 8 SitzMem_HFS
 SG_ NM_Sitz_FSFo_SNI : 0|8@1+ (1,0) [0|255] ""  AAG,BCM1,BCM2,ELV,Gateway,HDSG,IEZS,MFG,MSBBR,SAD,SAD2,SitzMem_BFS,SitzMem_FS,SitzMem_HBFS,SitzMem_HFS,SitzMem_SR3,SpoilerSG,TSG_BFS,TSG_FS,VSG,VTS
 SG_ NM_Sitz_FSFo_CBV_AWB : 12|1@1+ (1,0) [0|1] ""  Gateway
 SG_ NM_Sitz_FSFo_CBV_CRI : 14|1@1+ (1,0) [0|1] ""  AAG,BCM1,BCM2,ELV,Gateway,HDSG,IEZS,MFG,MSBBR,SAD,SAD2,SitzMem_BFS,SitzMem_FS,SitzMem_HBFS,SitzMem_HFS,SitzMem_SR3,SpoilerSG,TSG_BFS,TSG_FS,VSG,VTS
 SG_ NM_Sitz_FSFo_NM_State : 16|6@1+ (1,0) [0|63] "" Vector__XXX
 SG_ NM_Sitz_FSFo_Car_Wakeup : 22|1@1+ (1,0) [0|1] ""  Gateway
 SG_ NM_Sitz_FSFo_UDS_CC : 23|1@1+ (1,0) [0|1] "" Vector__XXX
 SG_ NM_Sitz_FSFo_NM_aktiv_KL15 : 24|1@1+ (1,0) [0|1] "" Vector__XXX
 SG_ NM_Sitz_FSFo_NM_aktiv_Diagnose : 25|1@1+ (1,0) [0|1] "" Vector__XXX
 SG_ NM_Sitz_FSFo_NM_aktiv_Tmin : 26|1@1+ (1,0) [0|1] "" Vector__XXX
 SG_ NM_Sitz_FSFo_NM_aktiv_Automlauf : 27|1@1+ (1,0) [0|1] "" Vector__XXX
 SG_ NM_Sitz_FSFo_NM_aktiv_Handverst : 28|1@1+ (1,0) [0|1] "" Vector__XXX
 SG_ NM_Sitz_FSFo_NM_aktiv_BR_anfahr : 29|1@1+ (1,0) [0|1] "" Vector__XXX
 SG_ NM_Sitz_FSFo_NM_aktiv_Visualis : 30|1@1+ (1,0) [0|1] "" Vector__XXX
 SG_ NM_Sitz_FSFo_CAB : 40|24@1+ (1,0) [0|16777215] ""  AAG,BCM1,BCM2,ELV,Gateway,HDSG,IEZS,MFG,MSBBR,SAD,SAD2,SitzMem_BFS,SitzMem_FS,SitzMem_HBFS,SitzMem_HFS,SitzMem_SR3,SpoilerSG,TSG_BFS,TSG_FS,VSG,VTS

CM_ BO_ 1601 "ab MQB mit CRC-8";
CM_ SG_ 1601 Motor_Code_01_CRC "Für MLB:
'Berechnung siehe Lastenheft 'Kommunikationsabsicherung für FlexRay und CAN''

Ab MQB und MLBevo:
'Berechnung siehe Lastenheft 'End-to-End Kommunikationsabsicherung''

Endwerte siehe Begleitdokument 'S-PDU Kennungsfolgen'";
CM_ SG_ 1601 MO_Faktor_Momente_02 "Dieses Signal schaltet den Wertebereich aller Momente vom Motor, Getriebe, TSK, Bremse ... um! Die Momente besitzen somit einen variablen Wertebereich, weil sich durch den Faktor die Momente sowohl in Auflösung als auch Maximalwerten ändert.

0x0 nicht ";
CM_ SG_ 1601 MO_Hybridfahrzeug "Anhand dieses Signals plausibilisiert die Lenkhilfe das Bit Fahrbereitschaft.

Im Projekt Cayenne PHEV (und ggf. auch VW526 PHEV) ist aus Gründen der Abwärtskompatibilität der Wert '2' zu senden.";
CM_ SG_ 1601 MO_Code "Motorcodierinformation für Getriebe. Überwachung auf Falschverbau.";
CM_ SG_ 1601 MO_Getriebe_Code "Getriebecodierung des Motors";
CM_ SG_ 1601 MO_StartStopp_Codiert "Funktion StartStopp im aktuellen Klemmenzyklus verbaut";
CM_ SG_ 1601 MO_Anzahl_Zyl "Zylinderzahl des Verbrennungsmotors";
CM_ SG_ 1601 MO_Kraftstoffart "Primärkraftstoff zum Antrieb des Fahrzeugs";
CM_ SG_ 1601 MO_Hubraum "Hubraum des Verbrennungsmotors";
CM_ SG_ 1601 MO_Ansaugsystem "Art des Ansaugsystems des Verbrennungsmotors";
CM_ SG_ 1601 MO_Leistung "Nennleistung des Verbrennungsmotors";
CM_ SG_ 1601 MO_OBD_Typ "Abgastyp OBD
";
CM_ SG_ 1601 MO_DPF_verbaut "Verbauinformation Diesel-Partikel-Filter
";
CM_ SG_ 1601 TSK_Codierung "Information über den plausibilisierten Codierungszustand des Triebstrangskoordinators auf ACC oder GRA.";
CM_ SG_ 394 MO_Ablaufstatus "aktueller Status bezüglich der Ausführung des Sollzustand

detaillierte Beschreibung der einzelnen Übergänge ist in der aktuellsten Version des Lastenhefts 'Funktionslastenheft Betriebsartenkoordination bei elektrifizierten Fahrzeugen_Vxx' zu entnehmen";
CM_ SG_ 394 MO_Ablaufstrg_Betriebszustand "Istzustand Betriebsbereitschaft

1 = Betriebsbereitschaft bedeutet: Alle Komponenten sind betriebsbereit. Fahrzeug kann kein Vortriebsmoment erzeugen.

2 = Fahrbetrieb bedeutet: Fahrzeug kann Vortriebsmoment erzeugen.";
CM_ SG_ 394 MO_Ablaufstrg_Zustand_VKM_Ist "Istzustand VKM
Dieses Signal entspricht nicht einem physikalischen Zustand, sondern den Istzustand der Ablaufsteuerung.

Das Signal darf nur ausgewertet werden, wenn 'MO_Ablaufstrg_Betriebszustand' eine Betriebsbereitschaft signalisiert.";
CM_ SG_ 394 MO_Ablaufstrg_Kraftschluss_Ist "Istzustand des Kraftschlusses in der Hybridablaufsteuerung.
Dieses Signal entspricht nicht einem physikalischen Zustand, sondern den Istzustand der Ablaufsteuerung.

Das Signal darf nur ausgwertet werden, wenn 'MO_Ablaufstrg_Betriebszustand' eine Betri";
CM_ SG_ 394 MO_Ablaufstrg_Zustand_K0_Ist "Iststatus der K0 Kupplung in der Hybridablaufsteuerung.
Dieses Signal entspricht nicht einem physikalischen Zustand, sondern den Istzustand der Ablaufsteuerung.

Das Signal darf nur ausgwertet werden, wenn 'MO_Ablaufstrg_Betriebszustand' eine Betriebsb";
CM_ SG_ 394 MO_Ablaufstrg_Kraftschluss2_Ist "Istzustand des Kraftschlusses der Sekundärachse in der Hybridablaufsteuerung (z.B. el. Hinterachse im B9 eQuattro).
Dieses Signal entspricht nicht einem physikalischen Zustand, sondern den Istzustand der Ablaufsteuerung.

Das Signal darf nur ausgwertet";
CM_ SG_ 394 MO_Ablaufstrg_Zustand_VKM_Ziel "Zielzustand VKM
Dieses Signal entspricht nicht einem physikalischen Zustand, sondern den Zielzustand der Ablaufsteuerung.

Das Signal darf nur ausgewertet werden, wenn 'MO_Ablaufstrg_Betriebszustand' eine Betriebsbereitschaft signalisiert.";
CM_ SG_ 394 MO_Ablaufstrg_Kraftschluss_Ziel "Zielstatus des Kraftschlusses in der Hybridablaufsteuerung.
Mit dem Bit soll das Getriebe Kraftschluss herstellen oder den Kraftschluss unterbrechen.

Das Signal darf nur ausgwertet werden, wenn 'MO_Ablaufstrg_Betriebszustand' eine Betriebsbereitschaft";
CM_ SG_ 394 MO_Ablaufstrg_Zustand_K0_Ziel "Zielstatus der K0 Kupplung in der Hybridablaufsteuerung
K0 Steuerung im Motorsteuergerät:
- Infobit an das Getriebe, dass K0 jetzt geschlossen wird
K0 Steuerung durch anderes Steuergerät:
- Bit um dem anderen SG mitzuteilen, dass dieses die K0 schlies";
CM_ SG_ 394 MO_Ablaufstrg_Kraftschluss2_Ziel "Zielstatus des Kraftschlusses der Sekundärachse in der Hybridablaufsteuerung (z.B. el. Hinterachse im B9 eQuattro).
Mit dem Bit soll das Getriebe Kraftschluss herstellen oder den Kraftschluss unterbrechen.

Das Signal darf nur ausgwertet werden, wenn '";
CM_ SG_ 394 MO_Auth_Aufforderung_WFS "WFS-Anforderung für Hybridumfänge";
CM_ SG_ 394 MO_Start_Dynamik "Beschreibt Dynamik des Zustandsüberganges näher ";
CM_ SG_ 394 MO_Start_Art "Beschreibt Art des Starts näher 

Schlupfstart kann entweder Momentenvorhalt oder Impulsstart sein oder eine Kombination aus beidem.";
CM_ SG_ 394 MO_Abstellposition_02 "Winkelabstand (in °KW) des sog. Zielzylinders von seinem ZOT (bspw. nötig um Startmoment bei Schleppstart zu berechnen)

255 = Abstellposition kann nicht genau bestimmt werden (bspw. Rückdrehen des Motors)";
CM_ SG_ 394 MO_Mom_Freiheit_Sekundaerachse "Signalisiert die Momentenfreiheit der Sekundärachse und ist damit Voraussetzung für das Abkoppeln.";
CM_ SG_ 394 MO_Nachlaufzeit_Kuehlerluefter "Nachlaufzeit Kühlerlüfter MSG für Verwendung im TME SG";
CM_ SG_ 394 MO_Tankklappensteuerung "Ansteuerungsanforderung der Tankklappe";
CM_ SG_ 394 MO_HYB_E_Faktor "Signed Nibble, verwendet vom GSG zur Interpolation zwischen VMKennfeld und dem Rekuperations-Grenzkennfeld (negative Werte des E-Faktors) bzw. dem Boost-Grenzkennfeld (positive Werte des E-Faktors).
0000 = VM-Kennfeld (keine Interpolation)
0001..0111 = ";
CM_ SG_ 1157 ND_SatInUse "Anzahl der zur Berechnung verwendeten Satelliten";
CM_ SG_ 1157 ND_SatInView "Anzahl der sichtbaren Satelliten";
CM_ SG_ 1157 NP_Altitude "Hoehe ueber NN
0xFFF = Fehler bei der Berechnung der Höhe über NN";
CM_ SG_ 1157 ND_UTC "UTC-Zeit, verstrichene Sekunden seit 01.01.1970 00:00
0xFFFFFFFE = Init
0xFFFFFFFF = Fehler bei Berechnung der UTC-Time";
CM_ SG_ 1158 NP_LatDegree "Latitude (Nord-Süd Wert)";
CM_ SG_ 1158 NP_LongDegree "Longitude (Ost-West Wert)";
CM_ SG_ 1158 NP_LatDirection "Hemisphäre Nord/Süd";
CM_ SG_ 1158 NP_LongDirection "Hemisphäre Ost/West";
CM_ SG_ 1158 NP_Sat "Nummer der verwendeten Sateliten beim letzten Fix";
CM_ SG_ 2589283496 POS_MUX "Multiplex-Signal zum schalten des Signals der Positionen von der Navigation.
MUX(0/1)";
CM_ SG_ 2589283496 POS_ODD_EVEN "Synchronisation der MUX Pos Signale
MUX(0/1)";
CM_ SG_ 2589283496 POS_PosStati "Aktueller Status der Navgation:
MUX(0)
0   init
1   no nav available (ready_4_nav)
2   no map available (sd_removed, not_enabled)
3   nav booting
4   nav error
5   nav calibrating
6   nav no gps resync since 1h
7   nav offroad  parkgarage ramp of";
CM_ SG_ 2589283496 POS_Heading "Heading of current position
MUX(1)";
CM_ SG_ 2589283496 POS_LatDirection "latitude direction nav position
MUX(0)";
CM_ SG_ 2589283496 POS_LatDegree "latitude - position data of navigation
MUX(0)";
CM_ SG_ 2589283496 POS_Last_GPS_Sync "Letztes bekannte GPS Sync in [s]
MUX(1)";
CM_ SG_ 2589283496 POS_Heading_Trust "Vertrauenswert Heading 
MUX(1) ";
CM_ SG_ 2589283496 POS_UTC_REF "Zeitstempel der Nav
MUX(1)

UTC-Zeit, verstrichene Sekunden seit 01.01.1970 00:00
0xFFFFFFFE = Init
0xFFFFFFFF = Fehler bei Berechnung der UTC-Time";
CM_ SG_ 2589283496 POS_LongDirection "longitude direction nav position
MUX(0)";
CM_ SG_ 2589283496 POS_LongDegree "long - position data of navigation
MUX(0)";
CM_ SG_ 2600468551 NM_AAG_SNI "Source Node-Identifier (SNI) identifiziert den Sender der NM-Botschaft (Knotenadresse) eindeutig im Fahrzeug";
CM_ SG_ 2600468551 NM_AAG_CBV_AWB "Das Signal ist zu setzen, wenn das SG aktiv den Bus geweckt hat";
CM_ SG_ 2600468551 NM_AAG_CBV_CRI "Das Signal ist dauerhaft gesetzt, wenn das NM-Layout dem neuen NM-Layout für Teilnetzbetrieb entspricht";
CM_ SG_ 2600468551 NM_AAG_NM_State "1 = Zustand Repeat Message (<-- Bus-Sleep Mode)
2 = Zustand Repeat Message (<-- Prepare Bus-Sleep Mode)
4 = Zustand Normal Operation (<-- Repeat Message)
8 = Zustand Normal Operation (<-- Ready Sleep)";
CM_ SG_ 2600468551 NM_AAG_Car_Wakeup "Car Wakeup (Gateway wertet aus)

MLBevo:
- Anstecken Anhänger";
CM_ SG_ 2600468551 NM_AAG_UDS_CC "Funktionseinschränkung aufgrund aktivem UDS-Communication Control; siehe VW80124";
CM_ SG_ 2600468551 NM_AAG_NM_aktiv_KL15 "Steuergerät hat KL15-EIN erkannt";
CM_ SG_ 2600468551 NM_AAG_NM_aktiv_Diagnose "Diagnose befindet sich nach VW80124 in einer NonDefaultDiagnostic-Session, z.B. ExtendedDiagnostic-Session";
CM_ SG_ 2600468551 NM_AAG_NM_aktiv_Tmin "Mindestaktivzeit ist noch nicht abgelaufen (bei jedem Weckereignis wird die Mindestaktivzeit neu gestartet)";
CM_ SG_ 2600468551 NM_AAG_NM_aktiv_Anhaenger_erk "Anhänger wurde durch das AAG erkannt. Nur für teilnetzfähiges Steuergerät relevant.";
CM_ SG_ 2600468551 NM_AAG_NM_aktiv_AVS_Fehler "Die Anhaengerkupplung befindet sich bei KL15 EIN in einer Zwischenstellung und ist in keiner Endlage eingerastet. (gilt für mechanische Kupplung). Nur für teilnetzfaehiges Steuergeraet.";
CM_ SG_ 2600468551 NM_AAG_NM_nicht_eingefahren "Die befindet sich nicht in der eingefahrenen Endlage (nur elektrische Kupplungen). Nur relevant fuer teilnetzfaehige Steuergeraete.";
CM_ SG_ 2600468551 NM_AAG_NM_KL15_unplausibel "KL15HW und KL15SW sind unplausibel. Nur relevant fuer teilnetzfaehige Steuergeraete.";
CM_ SG_ 2600468551 NM_AAG_CAB "CAB = Clusteraktivbits";
CM_ SG_ 2600468494 NM_BCM1_SNI "Source Node-Identifier (SNI) identifiziert den Sender der NM-Botschaft (Knotenadresse) eindeutig im Fahrzeug";
CM_ SG_ 2600468494 NM_BCM1_CBV_AWB "Das Signal ist zu setzen, wenn das SG aktiv den Bus geweckt hat";
CM_ SG_ 2600468494 NM_BCM1_CBV_CRI "Das Signal ist dauerhaft gesetzt, wenn das NM-Layout dem neuen NM-Layout für Teilnetzbetrieb entspricht";
CM_ SG_ 2600468494 NM_BCM1_NM_State "1 = Zustand Repeat Message (<-- Bus-Sleep Mode)
2 = Zustand Repeat Message (<-- Prepare Bus-Sleep Mode)
4 = Zustand Normal Operation (<-- Repeat Message)
8 = Zustand Normal Operation (<-- Ready Sleep)";
CM_ SG_ 2600468494 NM_BCM1_Car_Wakeup "Car Wakeup (Gateway wertet aus)
MQB: Kl.58xd, Kl.58xs, Kl.58xt eingeschaltet oder ausgeschaltet oder Dimmungssignal wurde vom Kunden geändert (nicht vom Fototransistor); S-Kontakt wurde ein- oder ausgeschaltet; Remotestartbetrieb; Tankklappe wurde geschl";
CM_ SG_ 2600468494 NM_BCM1_UDS_CC "Funktionseinschränkung aufgrund aktivem UDS-Communication Control; siehe VW80124";
CM_ SG_ 2600468494 NM_BCM1_NM_aktiv_KL15 "Steuergerät hat KL15-EIN erkannt";
CM_ SG_ 2600468494 NM_BCM1_NM_aktiv_Diagnose "Diagnose befindet sich nach VW80124 in einer NonDefaultDiagnostic-Session, z.B. ExtendedDiagnostic-Session";
CM_ SG_ 2600468494 NM_BCM1_NM_aktiv_Tmin "Mindestaktivzeit ist noch nicht abgelaufen (bei jedem Weckereignis wird die Mindestaktivzeit neu gestartet)";
CM_ SG_ 2600468494 NM_BCM1_NM_aktiv_Notlaufblinken "Notlaufblinken bei Ausfall BCM2";
CM_ SG_ 2600468494 NM_BCM1_NM_aktiv_ComingHome "ComingHome aktiv, max. 120s";
CM_ SG_ 2600468494 NM_BCM1_NM_aktiv_LeavingHome "LeavingHome aktiv, max. 60s
Annaeherungslicht";
CM_ SG_ 2600468494 NM_BCM1_NM_aktiv_Lichthupe "Lichthupe aktiv";
CM_ SG_ 2600468494 NM_BCM1_CAB "CAB = Clusteraktivbits";
CM_ BO_ 2600468619 "CAN_NM_PDU MLBevo";
CM_ SG_ 2600468619 NM_BCM2_SNI "Source Node-Identifier (SNI) identifiziert den Sender der NM-Botschaft (Knotenadresse) eindeutig im Fahrzeug";
CM_ SG_ 2600468619 NM_BCM2_CBV_AWB "Das Signal ist zu setzen, wenn das SG aktiv den Bus geweckt hat";
CM_ SG_ 2600468619 NM_BCM2_CBV_CRI "Das Signal ist dauerhaft gesetzt, wenn das NM-Layout dem neuen NM-Layout für Teilnetzbetrieb entspricht";
CM_ SG_ 2600468619 NM_BCM2_NM_State "1 = Zustand Repeat Message (<-- Bus-Sleep Mode)
2 = Zustand Repeat Message (<-- Prepare Bus-Sleep Mode)
4 = Zustand Normal Operation (<-- Repeat Message)
8 = Zustand Normal Operation (<-- Ready Sleep)
16 = Zustand Repeat Message (<-- Ready Sleep)
32 ";
CM_ SG_ 2600468619 NM_BCM2_Car_WakeUp "Car WakeUp optional
S-Kontakt
Schließen mit Funkschlüssel (Abfrage ob Automat in Stellung P)

MLBevo:
- KL15 HW
- Statusaenderung KL_S
- Stellung P bei Automat
- Remote Motorstart
- Bedienschalter Trunkentrapment
- Remote Door Lock Unlock";
CM_ SG_ 2600468619 NM_BCM2_UDS_CC "Funktionseinschränkung aufgrund aktivem UDS-Communication Control; siehe VW80124";
CM_ SG_ 2600468619 NM_BCM2_NM_aktiv_KL15 "Steuergerät hat KL15-EIN erkannt";
CM_ SG_ 2600468619 NM_BCM2_NM_aktiv_Diagnose "Diagnose befindet sich nach VW80124 in einer NonDefaultDiagnostic-Session, z.B. ExtendedDiagnostic-Session";
CM_ SG_ 2600468619 NM_BCM2_NM_aktiv_Tmin "Mindestaktivzeit ist noch nicht abgelaufen (bei jedem Weckereignis wird die Mindestaktivzeit neu gestartet)";
CM_ SG_ 2600468619 NM_BCM2_NM_aktiv_Warnblinken "Warnblinken ist aktiv";
CM_ SG_ 2600468619 NM_BCM2_NM_aktiv_Crashblinken "Crashblinken aktiv";
CM_ SG_ 2600468619 NM_BCM2_NM_aktiv_DWA_Alarm "DWA Alarm ist aktiv";
CM_ SG_ 2600468619 NM_BCM2_NM_aktiv_Remot_Door_L_Un "Remote Door Lock oder Unlock wird ausgefuehrt";
CM_ SG_ 2600468619 NM_BCM2_CAB "CAB = Clusteraktivbits";
CM_ SG_ 2600468529 NM_ELV_SNI "Source Node-Identifier (SNI) identifiziert den Sender der NM-Botschaft (Knotenadresse) eindeutig im Fahrzeug";
CM_ SG_ 2600468529 NM_ELV_CBV_AWB "Das Signal ist zu setzen, wenn das SG aktiv den Bus geweckt hat";
CM_ SG_ 2600468529 NM_ELV_CBV_CRI "Das Signal ist dauerhaft gesetzt, wenn das NM-Layout dem neuen NM-Layout für Teilnetzbetrieb entspricht";
CM_ SG_ 2600468529 NM_ELV_NM_State "1 = Zustand Repeat Message (<-- Bus-Sleep Mode)
2 = Zustand Repeat Message (<-- Prepare Bus-Sleep Mode)
4 = Zustand Normal Operation (<-- Repeat Message)
8 = Zustand Normal Operation (<-- Ready Sleep)";
CM_ SG_ 2600468529 NM_ELV_Car_Wakeup "Car Wakeup (Gateway wertet aus)
MQB: V-Signal bereitstellen, damit die Verriegelungsbedingung geprüft werden kann; Signal wird für 6 Sekunden gesetzt (in Ausnahmefällen 30 Sekunden)

MLBevo:
- Verriegelungsbedingungen prüfen
- Meldung bei verspannter";
CM_ SG_ 2600468529 NM_ELV_UDS_CC "Funktionseinschränkung aufgrund aktivem UDS-Communication Control; siehe VW80124";
CM_ SG_ 2600468529 NM_ELV_NM_aktiv_KL15 "Steuergerät hat KL15-EIN erkannt";
CM_ SG_ 2600468529 NM_ELV_NM_aktiv_Diagnose "Diagnose befindet sich nach VW80124 in einer NonDefaultDiagnostic-Session, z.B. ExtendedDiagnostic-Session";
CM_ SG_ 2600468529 NM_ELV_NM_aktiv_Tmin "Mindestaktivzeit ist noch nicht abgelaufen (bei jedem Weckereignis wird die Mindestaktivzeit neu gestartet)";
CM_ SG_ 2600468529 NM_ELV_NM_aktiv_Meldung "Fahrerinformation aktiv";
CM_ SG_ 2600468529 NM_ELV_NM_aktiv_Verfahrtrigger "Aktiver Trigger zum Verfahren der ELV ";
CM_ SG_ 2600468529 NM_ELV_NM_aktiv_WFS "WFS-Kommunikation aktiv";
CM_ SG_ 2600468529 NM_ELV_CAB "CAB = Clusteraktivbits";
CM_ SG_ 2600468496 NM_Gateway_SNI "Source Node-Identifier (SNI) identifiziert den Sender der NM-Botschaft (Knotenadresse) eindeutig im Fahrzeug";
CM_ SG_ 2600468496 NM_Gateway_CBV_AWB "Das Signal ist zu setzen, wenn das SG aktiv den Bus geweckt hat";
CM_ SG_ 2600468496 NM_Gateway_CBV_CRI "Das Signal ist dauerhaft gesetzt, wenn das NM-Layout dem neuen NM-Layout für Teilnetzbetrieb entspricht";
CM_ SG_ 2600468496 NM_Gateway_NM_State "1 = Zustand Repeat Message (<-- Bus-Sleep Mode)
2 = Zustand Repeat Message (<-- Prepare Bus-Sleep Mode)
4 = Zustand Normal Operation (<-- Repeat Message)
8 = Zustand Normal Operation (<-- Ready Sleep)
16 = Zustand Repeat Message (<-- Ready Sleep)
32 ";
CM_ SG_ 2600468496 NM_Gateway_Car_Wakeup "Car Wakeup (Subbusmaster wertet aus)
MQB: Diagnose- oder Komponentenschutzmaster-Funktion weckt den schlafenden Subbus (z.B. MOST)";
CM_ SG_ 2600468496 NM_Gateway_UDS_CC "Funktionseinschränkung aufgrund aktivem UDS-Communication Control; siehe VW80124";
CM_ SG_ 2600468496 NM_Gateway_NM_aktiv_KL15 "Steuergerät hat KL15-EIN erkannt";
CM_ SG_ 2600468496 NM_Gateway_NM_aktiv_Diagnose "Diagnose befindet sich nach VW80124 in einer NonDefaultDiagnostic-Session, z.B. ExtendedDiagnostic-Session";
CM_ SG_ 2600468496 NM_Gateway_NM_aktiv_Tmin "Mindestaktivzeit ist noch nicht abgelaufen (bei jedem Weckereignis wird die Mindestaktivzeit neu gestartet)";
CM_ SG_ 2600468496 NM_Gateway_NM_aktiv_CWU "Nachlauf aufgrund CWU Anforderung";
CM_ SG_ 2600468496 NM_Gateway_NM_aktiv_FC "Nachlauf aufgrund Funktionscluster Anforderung";
CM_ SG_ 2600468496 NM_Gateway_CAB "CAB = Clusteraktivbits";
CM_ SG_ 2600468515 NM_HDSG_SNI "Source Node-Identifier (SNI) identifiziert den Sender der NM-Botschaft (Knotenadresse) eindeutig im Fahrzeug";
CM_ SG_ 2600468515 NM_HDSG_CBV_AWB "Das Signal ist zu setzen, wenn das SG aktiv den Bus geweckt hat";
CM_ SG_ 2600468515 NM_HDSG_CBV_CRI "Das Signal ist dauerhaft gesetzt, wenn das NM-Layout dem neuen NM-Layout für Teilnetzbetrieb entspricht";
CM_ SG_ 2600468515 NM_HDSG_NM_State "1 = Zustand Repeat Message (<-- Bus-Sleep Mode)
2 = Zustand Repeat Message (<-- Prepare Bus-Sleep Mode)
4 = Zustand Normal Operation (<-- Repeat Message)
8 = Zustand Normal Operation (<-- Ready Sleep)";
CM_ SG_ 2600468515 NM_HDSG_Car_Wakeup "Car Wakeup (Gateway wertet aus)";
CM_ SG_ 2600468515 NM_HDSG_UDS_CC "Funktionseinschränkung aufgrund aktivem UDS-Communication Control; siehe VW80124";
CM_ SG_ 2600468515 NM_HDSG_NM_aktiv_KL15 "Steuergerät hat KL15-EIN erkannt";
CM_ SG_ 2600468515 NM_HDSG_NM_aktiv_Diagnose "Diagnose befindet sich nach VW80124 in einer NonDefaultDiagnostic-Session, z.B. ExtendedDiagnostic-Session";
CM_ SG_ 2600468515 NM_HDSG_NM_aktiv_Tmin "Mindestaktivzeit ist noch nicht abgelaufen (bei jedem Weckereignis wird die Mindestaktivzeit neu gestartet)";
CM_ SG_ 2600468515 NM_HDSG_Beweg_Heckklappe "Heckklappe in Bewegung bis Endposition erreicht ist";
CM_ SG_ 2600468515 NM_HDSG_CAB "CAB = Clusteraktivbits";
CM_ SG_ 2600468530 NM_Kessy_SNI "Source Node-Identifier (SNI) identifiziert den Sender der NM-Botschaft (Knotenadresse) eindeutig im Fahrzeug";
CM_ SG_ 2600468530 NM_Kessy_CBV_AWB "Das Signal ist zu setzen, wenn das SG aktiv den Bus geweckt hat";
CM_ SG_ 2600468530 NM_Kessy_CBV_CRI "Das Signal ist dauerhaft gesetzt, wenn das NM-Layout dem neuen NM-Layout für Teilnetzbetrieb entspricht";
CM_ SG_ 2600468530 NM_Kessy_NM_State "1 = Zustand Repeat Message (<-- Bus-Sleep Mode)
2 = Zustand Repeat Message (<-- Prepare Bus-Sleep Mode)
4 = Zustand Normal Operation (<-- Repeat Message)
8 = Zustand Normal Operation (<-- Ready Sleep)";
CM_ SG_ 2600468530 NM_Kessy_Car_Wakeup "Car Wakeup (Gateway wertet aus)
";
CM_ SG_ 2600468530 NM_Kessy_UDS_CC "Funktionseinschränkung aufgrund aktivem UDS-Communication Control; siehe VW80124";
CM_ SG_ 2600468530 NM_Kessy_NM_aktiv_KL15 "Steuergerät hat KL15-EIN erkannt";
CM_ SG_ 2600468530 NM_Kessy_NM_aktiv_Diagnose "Diagnose befindet sich nach VW80124 in einer NonDefaultDiagnostic-Session, z.B. ExtendedDiagnostic-Session";
CM_ SG_ 2600468530 NM_Kessy_NM_aktiv_Tmin "Mindestaktivzeit ist noch nicht abgelaufen (bei jedem Weckereignis wird die Mindestaktivzeit neu gestartet)";
CM_ SG_ 2600468530 NM_Kessy_NM_aktiv_Meldung "Fahrerinformation aktiv";
CM_ SG_ 2600468530 NM_Kessy_NM_aktiv_Anf_Klemmen "Kommunikation mit ELV und WFS bei Anforderung Klemmenfreigabe";
CM_ SG_ 2600468530 NM_Kessy_NM_aktiv_aut_Abschalt "Kommunikation aktiv nach automatischer Abschaltung der Klemmen (Verlassenskonzept).";
CM_ SG_ 2600468530 NM_Kessy_CAB "CAB = Clusteraktivbits";
CM_ SG_ 2600468524 NM_MFG_SNI "Source Node-Identifier (SNI) identifiziert den Sender der NM-Botschaft (Knotenadresse) eindeutig im Fahrzeug";
CM_ SG_ 2600468524 NM_MFG_CBV_AWB "Das Signal ist zu setzen, wenn das SG aktiv den Bus geweckt hat";
CM_ SG_ 2600468524 NM_MFG_CBV_CRI "Das Signal ist dauerhaft gesetzt, wenn das NM-Layout dem neuen NM-Layout für Teilnetzbetrieb entspricht";
CM_ SG_ 2600468524 NM_MFG_NM_State "1 = Zustand Repeat Message (<-- Bus-Sleep Mode)
2 = Zustand Repeat Message (<-- Prepare Bus-Sleep Mode)
4 = Zustand Normal Operation (<-- Repeat Message)
8 = Zustand Normal Operation (<-- Ready Sleep)";
CM_ SG_ 2600468524 NM_MFG_Car_Wakeup "Car Wakeup (Gateway wertet aus)";
CM_ SG_ 2600468524 NM_MFG_UDS_CC "Funktionseinschränkung aufgrund aktivem UDS-Communication Control; siehe VW80124";
CM_ SG_ 2600468524 NM_MFG_NM_aktiv_KL15 "Steuergerät hat KL15-EIN erkannt";
CM_ SG_ 2600468524 NM_MFG_NM_aktiv_Diagnose "Diagnose befindet sich nach VW80124 in einer NonDefaultDiagnostic-Session, z.B. ExtendedDiagnostic-Session";
CM_ SG_ 2600468524 NM_MFG_NM_aktiv_Tmin "Mindestaktivzeit ist noch nicht abgelaufen (bei jedem Weckereignis wird die Mindestaktivzeit neu gestartet)";
CM_ SG_ 2600468524 NM_MFG_CAB "CAB = Clusteraktivbits";
CM_ BO_ 2600468612 "CAN_NM_PDU MLBevo";
CM_ SG_ 2600468612 NM_SAD_SNI "Source Node-Identifier (SNI) identifiziert den Sender der NM-Botschaft (Knotenadresse) eindeutig im Fahrzeug";
CM_ SG_ 2600468612 NM_SAD_CBV_AWB "Das Signal ist zu setzen, wenn das SG aktiv den Bus geweckt hat";
CM_ SG_ 2600468612 NM_SAD_CBV_CRI "Das Signal ist dauerhaft gesetzt, wenn das NM-Layout dem neuen NM-Layout für Teilnetzbetrieb entspricht";
CM_ SG_ 2600468612 NM_SAD_NM_State "1 = Zustand Repeat Message (<-- Bus-Sleep Mode)
2 = Zustand Repeat Message (<-- Prepare Bus-Sleep Mode)
4 = Zustand Normal Operation (<-- Repeat Message)
8 = Zustand Normal Operation (<-- Ready Sleep)
16 = Zustand Repeat Message (<-- Ready Sleep)
32 ";
CM_ SG_ 2600468612 NM_SAD_Car_Wakeup "Car Wakeup (Gateway wertet aus)";
CM_ SG_ 2600468612 NM_SAD_UDS_CC "Funktionseinschränkung aufgrund aktivem UDS-Communication Control; siehe VW80124";
CM_ SG_ 2600468612 NM_SAD_NM_aktiv_KL15 "Steuergerät hat KL15-EIN erkannt";
CM_ SG_ 2600468612 NM_SAD_NM_aktiv_Diagnose "Diagnose befindet sich nach VW80124 in einer NonDefaultDiagnostic-Session, z.B. ExtendedDiagnostic-Session";
CM_ SG_ 2600468612 NM_SAD_NM_aktiv_Tmin "Mindestaktivzeit ist noch nicht abgelaufen (bei jedem Weckereignis wird die Mindestaktivzeit neu gestartet)";
CM_ SG_ 2600468612 NM_SAD_NM_aktiv_Dach_geoeffnet "Rollo oder Schiebedach verfährt";
CM_ SG_ 2600468612 NM_SAD_NM_aktiv_Dach_Rollo_fahrt "Rollo oder Schiebedach verfährt";
CM_ SG_ 2600468612 NM_SAD_CAB "CAB = Clusteraktivbits";
CM_ BO_ 2600468640 "CAN_NM_PDU MLBevo";
CM_ SG_ 2600468640 NM_SAD2_SNI "Source Node-Identifier (SNI) identifiziert den Sender der NM-Botschaft (Knotenadresse) eindeutig im Fahrzeug";
CM_ SG_ 2600468640 NM_SAD2_CBV_AWB "Das Signal ist zu setzen, wenn das SG aktiv den Bus geweckt hat";
CM_ SG_ 2600468640 NM_SAD2_CBV_CRI "Das Signal ist dauerhaft gesetzt, wenn das NM-Layout dem neuen NM-Layout für Teilnetzbetrieb entspricht";
CM_ SG_ 2600468640 NM_SAD2_NM_State "1 = Zustand Repeat Message (<-- Bus-Sleep Mode)
2 = Zustand Repeat Message (<-- Prepare Bus-Sleep Mode)
4 = Zustand Normal Operation (<-- Repeat Message)
8 = Zustand Normal Operation (<-- Ready Sleep)";
CM_ SG_ 2600468640 NM_SAD2_Car_Wakeup "Car Wakeup (Gateway wertet aus)";
CM_ SG_ 2600468640 NM_SAD2_UDS_CC "Funktionseinschränkung aufgrund aktivem UDS-Communication Control; siehe VW80124";
CM_ SG_ 2600468640 NM_SAD2_NM_aktiv_KL15 "Steuergerät hat KL15-EIN erkannt";
CM_ SG_ 2600468640 NM_SAD2_NM_aktiv_Diagnose "Diagnose befindet sich nach VW80124 in einer NonDefaultDiagnostic-Session, z.B. ExtendedDiagnostic-Session";
CM_ SG_ 2600468640 NM_SAD2_NM_aktiv_Tmin "Mindestaktivzeit ist noch nicht abgelaufen (bei jedem Weckereignis wird die Mindestaktivzeit neu gestartet)";
CM_ SG_ 2600468640 NM_SAD2_CAB "CAB = Clusteraktivbits";
CM_ BO_ 2600468635 "CAN_NM_PDU MLBevo";
CM_ SG_ 2600468635 NM_MSBBR_SNI "Source Node-Identifier (SNI) identifiziert den Sender der NM-Botschaft (Knotenadresse) eindeutig im Fahrzeug";
CM_ SG_ 2600468635 NM_MSBBR_CBV_AWB "Das Signal ist zu setzen, wenn das SG aktiv den Bus geweckt hat";
CM_ SG_ 2600468635 NM_MSBBR_CBV_CRI "Das Signal ist dauerhaft gesetzt, wenn das NM-Layout dem neuen NM-Layout für Teilnetzbetrieb entspricht";
CM_ SG_ 2600468635 NM_MSBBR_NM_State "1 = Zustand Repeat Message (<-- Bus-Sleep Mode)
2 = Zustand Repeat Message (<-- Prepare Bus-Sleep Mode)
4 = Zustand Normal Operation (<-- Repeat Message)
8 = Zustand Normal Operation (<-- Ready Sleep)";
CM_ SG_ 2600468635 NM_MSBBR_Car_Wakeup "Car Wakeup (Gateway wertet aus)";
CM_ SG_ 2600468635 NM_MSBBR_UDS_CC "Funktionseinschränkung aufgrund aktivem UDS-Communication Control; siehe VW80124";
CM_ SG_ 2600468635 NM_MSBBR_NM_aktiv_KL15 "Steuergerät hat KL15-EIN erkannt";
CM_ SG_ 2600468635 NM_MSBBR_NM_aktiv_Diagnose "Diagnose befindet sich nach VW80124 in einer NonDefaultDiagnostic-Session, z.B. ExtendedDiagnostic-Session";
CM_ SG_ 2600468635 NM_MSBBR_NM_aktiv_Tmin "Mindestaktivzeit ist noch nicht abgelaufen (bei jedem Weckereignis wird die Mindestaktivzeit neu gestartet)";
CM_ SG_ 2600468635 NM_MSBBR_CAB "CAB = Clusteraktivbits";
CM_ SG_ 2600468557 NM_Sitzmemo_BFS_SNI "Source Node-Identifier (SNI) identifiziert den Sender der NM-Botschaft (Knotenadresse) eindeutig im Fahrzeug";
CM_ SG_ 2600468557 NM_Sitzmemo_BFS_CBV_AWB "Das Signal ist zu setzen, wenn das SG aktiv den Bus geweckt hat";
CM_ SG_ 2600468557 NM_Sitzmemo_BFS_CBV_CRI "Das Signal ist dauerhaft gesetzt, wenn das NM-Layout dem neuen NM-Layout für Teilnetzbetrieb entspricht";
CM_ SG_ 2600468557 NM_Sitzmemo_BFS_NM_State "1 = Zustand Repeat Message (<-- Bus-Sleep Mode)
2 = Zustand Repeat Message (<-- Prepare Bus-Sleep Mode)
4 = Zustand Normal Operation (<-- Repeat Message)
8 = Zustand Normal Operation (<-- Ready Sleep)";
CM_ SG_ 2600468557 NM_Sitzmemo_BFS_Car_Wakeup "Car Wakeup (Gateway wertet aus)
";
CM_ SG_ 2600468557 NM_Sitzmemo_BFS_UDS_CC "Funktionseinschränkung aufgrund aktivem UDS-Communication Control; siehe VW80124";
CM_ SG_ 2600468557 NM_Sitzmemo_BFS_NM_aktiv_KL15 "Steuergerät hat KL15-EIN erkannt";
CM_ SG_ 2600468557 NM_Sitzmemo_BFS_NM_aktiv_Diag "Diagnose befindet sich nach VW80124 in einer NonDefaultDiagnostic-Session, z.B. ExtendedDiagnostic-Session";
CM_ SG_ 2600468557 NM_Sitzmemo_BFS_NM_aktiv_Tmin "Mindestaktivzeit ist noch nicht abgelaufen (bei jedem Weckereignis wird die Mindestaktivzeit neu gestartet)";
CM_ SG_ 2600468557 NM_Sitz_BFS_NM_aktiv_Automlauf "Automatiklauf Sitze";
CM_ SG_ 2600468557 NM_Sitz_BFS_NM_aktiv_Handverst "Aktiv aufgrund Handverstellung";
CM_ SG_ 2600468557 NM_Sitz_BFS_NM_aktiv_Visualis "Aktiv aufgrund Handverstellung";
CM_ SG_ 2600468557 NM_Sitzmemo_BFS_CAB "CAB = Clusteraktivbits";
CM_ SG_ 2600468616 NM_Sitz_BFSFo_SNI "Source Node-Identifier (SNI) identifiziert den Sender der NM-Botschaft (Knotenadresse) eindeutig im Fahrzeug";
CM_ SG_ 2600468616 NM_Sitz_BFSFo_CBV_AWB "Das Signal ist zu setzen, wenn das SG aktiv den Bus geweckt hat";
CM_ SG_ 2600468616 NM_Sitz_BFSFo_CBV_CRI "Das Signal ist dauerhaft gesetzt, wenn das NM-Layout dem neuen NM-Layout für Teilnetzbetrieb entspricht";
CM_ SG_ 2600468616 NM_Sitz_BFSFo_NM_State "1 = Zustand Repeat Message (<-- Bus-Sleep Mode)
2 = Zustand Repeat Message (<-- Prepare Bus-Sleep Mode)
4 = Zustand Normal Operation (<-- Repeat Message)
8 = Zustand Normal Operation (<-- Ready Sleep)
16 = Zustand Repeat Message (<-- Ready Sleep)
32 ";
CM_ SG_ 2600468616 NM_Sitz_BFSFo_Car_Wakeup "Car Wakeup (Gateway wertet aus)";
CM_ SG_ 2600468616 NM_Sitz_BFSFo_UDS_CC "Funktionseinschränkung aufgrund aktivem UDS-Communication Control; siehe VW80124";
CM_ SG_ 2600468616 NM_Sitz_BFSFo_NM_aktiv_KL15 "Steuergerät hat KL15-EIN erkannt";
CM_ SG_ 2600468616 NM_Sitz_BFSFo_NM_aktiv_Diagnose "Diagnose befindet sich nach VW80124 in einer NonDefaultDiagnostic-Session, z.B. ExtendedDiagnostic-Session";
CM_ SG_ 2600468616 NM_Sitz_BFSFo_NM_aktiv_Tmin "Mindestaktivzeit ist noch nicht abgelaufen (bei jedem Weckereignis wird die Mindestaktivzeit neu gestartet)";
CM_ SG_ 2600468616 NM_Sitz_BFSFo_NM_aktiv_Automlauf "Automatiklauf Sitze";
CM_ SG_ 2600468616 NM_Sitz_BFSFo_NM_aktiv_Handverst "Aktiv aufgrund Handverstellung";
CM_ SG_ 2600468616 NM_Sitz_BFSFo_NM_aktiv_BR_anfahr "Business oder Relax anfahren";
CM_ SG_ 2600468616 NM_Sitz_BFSFo_NM_aktiv_Visualis "Aktiv aufgrund Handverstellung";
CM_ SG_ 2600468616 NM_Sitz_BFSFo_CAB "CAB = Clusteraktivbits";
CM_ SG_ 2600468556 NM_Sitzmemo_FS_SNI "Source Node-Identifier (SNI) identifiziert den Sender der NM-Botschaft (Knotenadresse) eindeutig im Fahrzeug";
CM_ SG_ 2600468556 NM_Sitzmemo_FS_CBV_AWB "Das Signal ist zu setzen, wenn das SG aktiv den Bus geweckt hat";
CM_ SG_ 2600468556 NM_Sitzmemo_FS_CBV_CRI "Das Signal ist dauerhaft gesetzt, wenn das NM-Layout dem neuen NM-Layout für Teilnetzbetrieb entspricht";
CM_ SG_ 2600468556 NM_Sitzmemo_FS_NM_State "1 = Zustand Repeat Message (<-- Bus-Sleep Mode)
2 = Zustand Repeat Message (<-- Prepare Bus-Sleep Mode)
4 = Zustand Normal Operation (<-- Repeat Message)
8 = Zustand Normal Operation (<-- Ready Sleep)";
CM_ SG_ 2600468556 NM_Sitzmemo_FS_Car_Wakeup "Car Wakeup (Gateway wertet aus)
";
CM_ SG_ 2600468556 NM_Sitzmemo_FS_UDS_CC "Funktionseinschränkung aufgrund aktivem UDS-Communication Control; siehe VW80124";
CM_ SG_ 2600468556 NM_Sitzmemo_FS_NM_aktiv_KL15 "Steuergerät hat KL15-EIN erkannt";
CM_ SG_ 2600468556 NM_Sitzmemo_FS_NM_aktiv_Diag "Diagnose befindet sich nach VW80124 in einer NonDefaultDiagnostic-Session, z.B. ExtendedDiagnostic-Session";
CM_ SG_ 2600468556 NM_Sitzmemo_FS_NM_aktiv_Tmin "Mindestaktivzeit ist noch nicht abgelaufen (bei jedem Weckereignis wird die Mindestaktivzeit neu gestartet)";
CM_ SG_ 2600468556 NM_Sitzmemo_FS_NM_aktiv_Autolauf "Automatiklauf Sitze";
CM_ SG_ 2600468556 NM_Sitz_FS_NM_aktiv_Handverst "Aktiv aufgrund Handverstellung";
CM_ SG_ 2600468556 NM_Sitz_FS_NM_aktiv_Visualis "Aktiv aufgrund Handverstellung";
CM_ SG_ 2600468556 NM_Sitz_FS_NM_aktiv_Speichern "Aktiv aufgrund Handverstellung";
CM_ SG_ 2600468556 NM_Sitzmemo_FS_CAB "CAB = Clusteraktivbits";
CM_ SG_ 2600468615 NM_Sitz_FSFo_SNI "Source Node-Identifier (SNI) identifiziert den Sender der NM-Botschaft (Knotenadresse) eindeutig im Fahrzeug";
CM_ SG_ 2600468615 NM_Sitz_FSFo_CBV_AWB "Das Signal ist zu setzen, wenn das SG aktiv den Bus geweckt hat";
CM_ SG_ 2600468615 NM_Sitz_FSFo_CBV_CRI "Das Signal ist dauerhaft gesetzt, wenn das NM-Layout dem neuen NM-Layout für Teilnetzbetrieb entspricht";
CM_ SG_ 2600468615 NM_Sitz_FSFo_NM_State "1 = Zustand Repeat Message (<-- Bus-Sleep Mode)
2 = Zustand Repeat Message (<-- Prepare Bus-Sleep Mode)
4 = Zustand Normal Operation (<-- Repeat Message)
8 = Zustand Normal Operation (<-- Ready Sleep)
16 = Zustand Repeat Message (<-- Ready Sleep)
32 ";
CM_ SG_ 2600468615 NM_Sitz_FSFo_Car_Wakeup "Car Wakeup (Gateway wertet aus)";
CM_ SG_ 2600468615 NM_Sitz_FSFo_UDS_CC "Funktionseinschränkung aufgrund aktivem UDS-Communication Control; siehe VW80124";
CM_ SG_ 2600468615 NM_Sitz_FSFo_NM_aktiv_KL15 "Steuergerät hat KL15-EIN erkannt";
CM_ SG_ 2600468615 NM_Sitz_FSFo_NM_aktiv_Diagnose "Diagnose befindet sich nach VW80124 in einer NonDefaultDiagnostic-Session, z.B. ExtendedDiagnostic-Session";
CM_ SG_ 2600468615 NM_Sitz_FSFo_NM_aktiv_Tmin "Mindestaktivzeit ist noch nicht abgelaufen (bei jedem Weckereignis wird die Mindestaktivzeit neu gestartet)";
CM_ SG_ 2600468615 NM_Sitz_FSFo_NM_aktiv_Automlauf "Automatiklauf Sitze";
CM_ SG_ 2600468615 NM_Sitz_FSFo_NM_aktiv_Handverst "Aktiv aufgrund Handverstellung";
CM_ SG_ 2600468615 NM_Sitz_FSFo_NM_aktiv_BR_anfahr "Business oder Relax anfahren";
CM_ SG_ 2600468615 NM_Sitz_FSFo_NM_aktiv_Visualis "Aktiv aufgrund Handverstellung";
CM_ SG_ 2600468615 NM_Sitz_FSFo_CAB "CAB = Clusteraktivbits";
BA_DEF_ BO_  "DiagRequest" ENUM  "No","Yes";
BA_DEF_ BO_  "DiagResponse" ENUM  "No","Yes";
BA_DEF_ BO_  "DiagState" ENUM  "No","Yes";
BA_DEF_ BO_  "GenMsgChkConstant" HEX 0 4095;
BA_DEF_ BO_  "GenMsgCycleTime" INT 0 65535;
BA_DEF_ BO_  "GenMsgCycleTimeFast" INT 0 65535;
BA_DEF_ BO_  "GenMsgDelayTime" INT 0 100000;
BA_DEF_ BO_  "GenMsgILSupport" ENUM  "No","Yes";
BA_DEF_ BO_  "GenMsgNrOfRepetition" INT 0 100;
BA_DEF_ BO_  "GenMsgPDUConstants" STRING ;
BA_DEF_ BO_  "GenMsgSendType" ENUM  "Cyclic","not_used","not_used","not_used","not_used","not_used","not_used","IfActive","NoMsgSendType";
BA_DEF_ BO_  "GenMsgStartDelayTime" INT 0 100000;
BA_DEF_ BO_  "NmMessage" ENUM  "No","Yes";
BA_DEF_ BO_  "NmhMessage" ENUM  "No","Yes";
BA_DEF_ BO_  "MsgType" ENUM  "Application","NM ","NMH","TP2.0","ISO-TP ","BAP","EID";
BA_DEF_ BO_  "VAGTP20_API" HEX 0 255;
BA_DEF_ BO_  "VAGTP20_DynConnection" ENUM  "No","Yes";
BA_DEF_ BO_  "VAGTP20_DynSetup" ENUM  "No","Yes";
BA_DEF_ BO_  "VAGTP20_StatConnection" ENUM  "No","Yes";
BA_DEF_ SG_  "GenSigActiveRepetitions" INT -2147483648 2147483647;
BA_DEF_ SG_  "GenSigInactiveValue" INT -2147483648 2147483647;
BA_DEF_ SG_  "GenSigSendType" ENUM  "Cyclic","OnWrite","OnWriteWithRepetition","OnChange","OnChangeWithRepetition","IfActive","IfActiveWithRepetition","NoSigSendType","OnChangeAndIfActive","OnChangeAndIfActiveWithRepetition";
BA_DEF_ SG_  "GenSigStartValue" INT -2147483648 2147483647;
BA_DEF_ SG_  "NWM-WakeupAllowed" ENUM  "No","Yes";
BA_DEF_ SG_  "GenSigFuncType" ENUM  "NoFunction","MsgCounter","CRC-8","XOR","XOR-2","DatedBit","SW-Kl15","CHK","Constant","Protocol","CRC-8-SAE_J1850";
BA_DEF_ SG_  "GenSigSwitchedByIgnition" ENUM  "No","Yes";
BA_DEF_ SG_  "Fehlerwert" HEX 0 2147483647;
BA_DEF_ SG_  "GenSigMissingSourceValue" HEX 0 2147483647;
BA_DEF_REL_ BU_SG_REL_  "GenSigTimeoutTime" INT 0 65535;
BA_DEF_DEF_  "DiagRequest" "No";
BA_DEF_DEF_  "DiagResponse" "No";
BA_DEF_DEF_  "DiagState" "No";
BA_DEF_DEF_  "GenMsgChkConstant" 0;
BA_DEF_DEF_  "GenMsgCycleTime" 0;
BA_DEF_DEF_  "GenMsgCycleTimeFast" 0;
BA_DEF_DEF_  "GenMsgDelayTime" 0;
BA_DEF_DEF_  "GenMsgILSupport" "No";
BA_DEF_DEF_  "GenMsgNrOfRepetition" 0;
BA_DEF_DEF_  "GenMsgPDUConstants" "";
BA_DEF_DEF_  "GenMsgSendType" "NoMsgSendType";
BA_DEF_DEF_  "GenMsgStartDelayTime" 0;
BA_DEF_DEF_  "NmMessage" "No";
BA_DEF_DEF_  "NmhMessage" "No";
BA_DEF_DEF_  "MsgType" "Application";
BA_DEF_DEF_  "VAGTP20_API" 0;
BA_DEF_DEF_  "VAGTP20_DynConnection" "No";
BA_DEF_DEF_  "VAGTP20_DynSetup" "No";
BA_DEF_DEF_  "VAGTP20_StatConnection" "No";
BA_DEF_DEF_  "GenSigActiveRepetitions" 0;
BA_DEF_DEF_  "GenSigInactiveValue" 0;
BA_DEF_DEF_  "GenSigSendType" "NoSigSendType";
BA_DEF_DEF_  "GenSigStartValue" 0;
BA_DEF_DEF_  "NWM-WakeupAllowed" "No";
BA_DEF_DEF_  "GenSigFuncType" "NoFunction";
BA_DEF_DEF_  "GenSigSwitchedByIgnition" "Yes";
BA_DEF_DEF_  "Fehlerwert" 0;
BA_DEF_DEF_  "GenSigMissingSourceValue" 0;
BA_DEF_DEF_REL_ "GenSigTimeoutTime" 0;
BA_ "GenMsgSendType" BO_ 1601 0;
BA_ "GenMsgPDUConstants" BO_ 1601 "0x47,0x47,0x47,0x47,0x47,0x47,0x47,0x47,0x47,0x47,0x47,0x47,0x47,0x47,0x47,0x47";
BA_ "GenMsgILSupport" BO_ 1601 1;
BA_ "GenMsgCycleTime" BO_ 1601 960;
BA_ "GenMsgChkConstant" BO_ 1601 71;
BA_ "GenMsgSendType" BO_ 394 0;
BA_ "GenMsgPDUConstants" BO_ 394 "0x88,0xe3,0xde,0xe8,0xcc,0xc4,0x09,0x7f,0x7b,0xf1,0x23,0x95,0x9d,0xd8,0x25,0xb0";
BA_ "GenMsgILSupport" BO_ 394 1;
BA_ "GenMsgDelayTime" BO_ 394 10;
BA_ "GenMsgCycleTime" BO_ 394 200;
BA_ "GenMsgSendType" BO_ 1157 0;
BA_ "GenMsgILSupport" BO_ 1157 1;
BA_ "GenMsgCycleTime" BO_ 1157 1000;
BA_ "GenMsgSendType" BO_ 1158 0;
BA_ "GenMsgILSupport" BO_ 1158 1;
BA_ "GenMsgCycleTime" BO_ 1158 1000;
BA_ "GenMsgSendType" BO_ 2589283496 0;
BA_ "GenMsgILSupport" BO_ 2589283496 1;
BA_ "GenMsgCycleTime" BO_ 2589283496 500;
BA_ "MsgType" BO_ 2600468551 2;
BA_ "NmhMessage" BO_ 2600468551 1;
BA_ "GenMsgSendType" BO_ 2600468551 7;
BA_ "GenMsgNrOfRepetition" BO_ 2600468551 3;
BA_ "GenMsgCycleTimeFast" BO_ 2600468551 10;
BA_ "GenMsgCycleTime" BO_ 2600468551 200;
BA_ "MsgType" BO_ 2600468494 2;
BA_ "NmhMessage" BO_ 2600468494 1;
BA_ "GenMsgSendType" BO_ 2600468494 7;
BA_ "GenMsgNrOfRepetition" BO_ 2600468494 3;
BA_ "GenMsgCycleTimeFast" BO_ 2600468494 10;
BA_ "GenMsgCycleTime" BO_ 2600468494 200;
BA_ "MsgType" BO_ 2600468619 2;
BA_ "NmhMessage" BO_ 2600468619 1;
BA_ "GenMsgSendType" BO_ 2600468619 7;
BA_ "GenMsgNrOfRepetition" BO_ 2600468619 3;
BA_ "GenMsgCycleTimeFast" BO_ 2600468619 10;
BA_ "GenMsgCycleTime" BO_ 2600468619 200;
BA_ "MsgType" BO_ 2600468529 2;
BA_ "NmhMessage" BO_ 2600468529 1;
BA_ "GenMsgSendType" BO_ 2600468529 7;
BA_ "GenMsgNrOfRepetition" BO_ 2600468529 3;
BA_ "GenMsgCycleTimeFast" BO_ 2600468529 10;
BA_ "GenMsgCycleTime" BO_ 2600468529 200;
BA_ "MsgType" BO_ 2600468496 2;
BA_ "NmhMessage" BO_ 2600468496 1;
BA_ "GenMsgSendType" BO_ 2600468496 7;
BA_ "GenMsgNrOfRepetition" BO_ 2600468496 3;
BA_ "GenMsgCycleTimeFast" BO_ 2600468496 10;
BA_ "GenMsgCycleTime" BO_ 2600468496 200;
BA_ "MsgType" BO_ 2600468515 2;
BA_ "NmhMessage" BO_ 2600468515 1;
BA_ "GenMsgSendType" BO_ 2600468515 7;
BA_ "GenMsgNrOfRepetition" BO_ 2600468515 3;
BA_ "GenMsgCycleTimeFast" BO_ 2600468515 10;
BA_ "GenMsgCycleTime" BO_ 2600468515 200;
BA_ "MsgType" BO_ 2600468530 2;
BA_ "NmhMessage" BO_ 2600468530 1;
BA_ "GenMsgSendType" BO_ 2600468530 7;
BA_ "GenMsgNrOfRepetition" BO_ 2600468530 3;
BA_ "GenMsgCycleTimeFast" BO_ 2600468530 10;
BA_ "GenMsgCycleTime" BO_ 2600468530 200;
BA_ "MsgType" BO_ 2600468524 2;
BA_ "NmhMessage" BO_ 2600468524 1;
BA_ "GenMsgSendType" BO_ 2600468524 7;
BA_ "GenMsgNrOfRepetition" BO_ 2600468524 3;
BA_ "GenMsgCycleTimeFast" BO_ 2600468524 10;
BA_ "GenMsgCycleTime" BO_ 2600468524 200;
BA_ "MsgType" BO_ 2600468612 2;
BA_ "NmhMessage" BO_ 2600468612 1;
BA_ "GenMsgSendType" BO_ 2600468612 7;
BA_ "GenMsgNrOfRepetition" BO_ 2600468612 3;
BA_ "GenMsgCycleTimeFast" BO_ 2600468612 10;
BA_ "GenMsgCycleTime" BO_ 2600468612 200;
BA_ "MsgType" BO_ 2600468640 2;
BA_ "NmhMessage" BO_ 2600468640 1;
BA_ "GenMsgSendType" BO_ 2600468640 7;
BA_ "GenMsgNrOfRepetition" BO_ 2600468640 3;
BA_ "GenMsgCycleTimeFast" BO_ 2600468640 10;
BA_ "GenMsgCycleTime" BO_ 2600468640 200;
BA_ "MsgType" BO_ 2600468635 2;
BA_ "NmhMessage" BO_ 2600468635 1;
BA_ "GenMsgSendType" BO_ 2600468635 7;
BA_ "GenMsgNrOfRepetition" BO_ 2600468635 3;
BA_ "GenMsgCycleTimeFast" BO_ 2600468635 10;
BA_ "GenMsgCycleTime" BO_ 2600468635 200;
BA_ "MsgType" BO_ 2600468557 2;
BA_ "NmhMessage" BO_ 2600468557 1;
BA_ "GenMsgSendType" BO_ 2600468557 7;
BA_ "GenMsgNrOfRepetition" BO_ 2600468557 3;
BA_ "GenMsgCycleTimeFast" BO_ 2600468557 10;
BA_ "GenMsgCycleTime" BO_ 2600468557 200;
BA_ "MsgType" BO_ 2600468616 2;
BA_ "NmhMessage" BO_ 2600468616 1;
BA_ "GenMsgSendType" BO_ 2600468616 7;
BA_ "GenMsgNrOfRepetition" BO_ 2600468616 3;
BA_ "GenMsgCycleTimeFast" BO_ 2600468616 10;
BA_ "GenMsgCycleTime" BO_ 2600468616 200;
BA_ "MsgType" BO_ 2600468556 2;
BA_ "NmhMessage" BO_ 2600468556 1;
BA_ "GenMsgSendType" BO_ 2600468556 7;
BA_ "GenMsgNrOfRepetition" BO_ 2600468556 3;
BA_ "GenMsgCycleTimeFast" BO_ 2600468556 10;
BA_ "GenMsgCycleTime" BO_ 2600468556 200;
BA_ "MsgType" BO_ 2600468615 2;
BA_ "NmhMessage" BO_ 2600468615 1;
BA_ "GenMsgSendType" BO_ 2600468615 7;
BA_ "GenMsgNrOfRepetition" BO_ 2600468615 3;
BA_ "GenMsgCycleTimeFast" BO_ 2600468615 10;
BA_ "GenMsgCycleTime" BO_ 2600468615 200;
BA_ "GenSigSwitchedByIgnition" SG_ 1601 Motor_Code_01_CRC 0;
BA_ "GenSigFuncType" SG_ 1601 Motor_Code_01_CRC 2;
BA_ "GenSigSendType" SG_ 1601 Motor_Code_01_CRC 0;
BA_ "GenSigSwitchedByIgnition" SG_ 1601 Motor_Code_01_BZ 0;
BA_ "GenSigFuncType" SG_ 1601 Motor_Code_01_BZ 1;
BA_ "GenSigSendType" SG_ 1601 Motor_Code_01_BZ 0;
BA_ "GenSigSwitchedByIgnition" SG_ 1601 MO_Faktor_Momente_02 0;
BA_ "GenSigFuncType" SG_ 1601 MO_Faktor_Momente_02 8;
BA_ "GenSigSendType" SG_ 1601 MO_Faktor_Momente_02 0;
BA_ "GenSigSwitchedByIgnition" SG_ 1601 MO_Hybridfahrzeug 0;
BA_ "GenSigFuncType" SG_ 1601 MO_Hybridfahrzeug 8;
BA_ "GenSigSendType" SG_ 1601 MO_Hybridfahrzeug 0;
BA_ "GenSigSwitchedByIgnition" SG_ 1601 MO_Code 0;
BA_ "GenSigFuncType" SG_ 1601 MO_Code 8;
BA_ "GenSigSendType" SG_ 1601 MO_Code 0;
BA_ "GenSigSwitchedByIgnition" SG_ 1601 MO_Getriebe_Code 0;
BA_ "GenSigFuncType" SG_ 1601 MO_Getriebe_Code 8;
BA_ "GenSigSendType" SG_ 1601 MO_Getriebe_Code 0;
BA_ "GenSigSwitchedByIgnition" SG_ 1601 MO_StartStopp_Codiert 0;
BA_ "GenSigFuncType" SG_ 1601 MO_StartStopp_Codiert 8;
BA_ "GenSigSendType" SG_ 1601 MO_StartStopp_Codiert 0;
BA_ "GenSigSwitchedByIgnition" SG_ 1601 MO_Anzahl_Zyl 0;
BA_ "GenSigFuncType" SG_ 1601 MO_Anzahl_Zyl 8;
BA_ "GenSigSendType" SG_ 1601 MO_Anzahl_Zyl 0;
BA_ "GenSigSwitchedByIgnition" SG_ 1601 MO_Kraftstoffart 0;
BA_ "GenSigFuncType" SG_ 1601 MO_Kraftstoffart 8;
BA_ "GenSigSendType" SG_ 1601 MO_Kraftstoffart 0;
BA_ "GenSigSwitchedByIgnition" SG_ 1601 MO_Hubraum 0;
BA_ "GenSigFuncType" SG_ 1601 MO_Hubraum 8;
BA_ "GenSigSendType" SG_ 1601 MO_Hubraum 0;
BA_ "GenSigSwitchedByIgnition" SG_ 1601 MO_Ansaugsystem 0;
BA_ "GenSigFuncType" SG_ 1601 MO_Ansaugsystem 8;
BA_ "GenSigSendType" SG_ 1601 MO_Ansaugsystem 0;
BA_ "GenSigSwitchedByIgnition" SG_ 1601 MO_Leistung 0;
BA_ "GenSigFuncType" SG_ 1601 MO_Leistung 8;
BA_ "GenSigSendType" SG_ 1601 MO_Leistung 0;
BA_ "GenSigSwitchedByIgnition" SG_ 1601 MO_OBD_Typ 0;
BA_ "GenSigFuncType" SG_ 1601 MO_OBD_Typ 8;
BA_ "GenSigSendType" SG_ 1601 MO_OBD_Typ 0;
BA_ "GenSigSwitchedByIgnition" SG_ 1601 MO_DPF_verbaut 0;
BA_ "GenSigFuncType" SG_ 1601 MO_DPF_verbaut 8;
BA_ "GenSigSendType" SG_ 1601 MO_DPF_verbaut 0;
BA_ "GenSigSwitchedByIgnition" SG_ 1601 TSK_Codierung 0;
BA_ "GenSigStartValue" SG_ 1601 TSK_Codierung 7;
BA_ "GenSigSendType" SG_ 1601 TSK_Codierung 0;
BA_ "Fehlerwert" SG_ 394 MO_Ablaufstatus 15;
BA_ "GenSigSwitchedByIgnition" SG_ 394 MO_Ablaufstatus 0;
BA_ "GenSigSendType" SG_ 394 MO_Ablaufstatus 0;
BA_ "Fehlerwert" SG_ 394 MO_Ablaufstrg_Betriebszustand 7;
BA_ "GenSigSwitchedByIgnition" SG_ 394 MO_Ablaufstrg_Betriebszustand 0;
BA_ "GenSigSendType" SG_ 394 MO_Ablaufstrg_Betriebszustand 0;
BA_ "GenSigSwitchedByIgnition" SG_ 394 MO_Ablaufstrg_Zustand_VKM_Ist 0;
BA_ "GenSigSendType" SG_ 394 MO_Ablaufstrg_Zustand_VKM_Ist 0;
BA_ "GenSigSwitchedByIgnition" SG_ 394 MO_Ablaufstrg_Kraftschluss_Ist 0;
BA_ "GenSigSendType" SG_ 394 MO_Ablaufstrg_Kraftschluss_Ist 0;
BA_ "GenSigSwitchedByIgnition" SG_ 394 MO_Ablaufstrg_Zustand_K0_Ist 0;
BA_ "GenSigSendType" SG_ 394 MO_Ablaufstrg_Zustand_K0_Ist 0;
BA_ "GenSigSwitchedByIgnition" SG_ 394 MO_Ablaufstrg_Kraftschluss2_Ist 0;
BA_ "GenSigSendType" SG_ 394 MO_Ablaufstrg_Kraftschluss2_Ist 0;
BA_ "GenSigSwitchedByIgnition" SG_ 394 MO_Ablaufstrg_Zustand_VKM_Ziel 0;
BA_ "GenSigSendType" SG_ 394 MO_Ablaufstrg_Zustand_VKM_Ziel 0;
BA_ "GenSigSwitchedByIgnition" SG_ 394 MO_Ablaufstrg_Kraftschluss_Ziel 0;
BA_ "GenSigSendType" SG_ 394 MO_Ablaufstrg_Kraftschluss_Ziel 0;
BA_ "GenSigSwitchedByIgnition" SG_ 394 MO_Ablaufstrg_Zustand_K0_Ziel 0;
BA_ "GenSigSendType" SG_ 394 MO_Ablaufstrg_Zustand_K0_Ziel 0;
BA_ "GenSigSwitchedByIgnition" SG_ 394 MO_Ablaufstrg_Kraftschluss2_Ziel 0;
BA_ "GenSigSendType" SG_ 394 MO_Ablaufstrg_Kraftschluss2_Ziel 0;
BA_ "GenSigSwitchedByIgnition" SG_ 394 MO_Auth_Aufforderung_WFS 0;
BA_ "GenSigSendType" SG_ 394 MO_Auth_Aufforderung_WFS 0;
BA_ "GenSigSwitchedByIgnition" SG_ 394 MO_Start_Dynamik 0;
BA_ "GenSigSendType" SG_ 394 MO_Start_Dynamik 0;
BA_ "GenSigSwitchedByIgnition" SG_ 394 MO_Start_Art 0;
BA_ "GenSigSendType" SG_ 394 MO_Start_Art 3;
BA_ "GenSigSwitchedByIgnition" SG_ 394 MO_Abstellposition_02 0;
BA_ "GenSigStartValue" SG_ 394 MO_Abstellposition_02 255;
BA_ "GenSigSendType" SG_ 394 MO_Abstellposition_02 0;
BA_ "GenSigSwitchedByIgnition" SG_ 394 MO_Mom_Freiheit_Sekundaerachse 0;
BA_ "GenSigSendType" SG_ 394 MO_Mom_Freiheit_Sekundaerachse 0;
BA_ "GenSigSwitchedByIgnition" SG_ 394 MO_Nachlaufzeit_Kuehlerluefter 0;
BA_ "GenSigSendType" SG_ 394 MO_Nachlaufzeit_Kuehlerluefter 0;
BA_ "GenSigSwitchedByIgnition" SG_ 394 MO_Tankklappensteuerung 0;
BA_ "GenSigSendType" SG_ 394 MO_Tankklappensteuerung 3;
BA_ "GenSigSwitchedByIgnition" SG_ 394 MO_HYB_E_Faktor 0;
BA_ "GenSigSendType" SG_ 394 MO_HYB_E_Faktor 0;
BA_ "Fehlerwert" SG_ 1157 ND_SatInUse 31;
BA_ "GenSigSwitchedByIgnition" SG_ 1157 ND_SatInUse 0;
BA_ "GenSigStartValue" SG_ 1157 ND_SatInUse 30;
BA_ "GenSigSendType" SG_ 1157 ND_SatInUse 0;
BA_ "Fehlerwert" SG_ 1157 ND_SatInView 31;
BA_ "GenSigSwitchedByIgnition" SG_ 1157 ND_SatInView 0;
BA_ "GenSigStartValue" SG_ 1157 ND_SatInView 30;
BA_ "GenSigSendType" SG_ 1157 ND_SatInView 0;
BA_ "Fehlerwert" SG_ 1157 NP_Altitude 4095;
BA_ "GenSigSwitchedByIgnition" SG_ 1157 NP_Altitude 0;
BA_ "GenSigStartValue" SG_ 1157 NP_Altitude 4094;
BA_ "GenSigSendType" SG_ 1157 NP_Altitude 0;
BA_ "GenSigSwitchedByIgnition" SG_ 1157 ND_UTC 0;
BA_ "GenSigSendType" SG_ 1157 ND_UTC 0;
BA_ "Fehlerwert" SG_ 1158 NP_LatDegree 134217727;
BA_ "GenSigSwitchedByIgnition" SG_ 1158 NP_LatDegree 0;
BA_ "GenSigStartValue" SG_ 1158 NP_LatDegree 134217726;
BA_ "GenSigSendType" SG_ 1158 NP_LatDegree 0;
BA_ "Fehlerwert" SG_ 1158 NP_LongDegree 268435455;
BA_ "GenSigSwitchedByIgnition" SG_ 1158 NP_LongDegree 0;
BA_ "GenSigStartValue" SG_ 1158 NP_LongDegree 268435454;
BA_ "GenSigSendType" SG_ 1158 NP_LongDegree 0;
BA_ "GenSigSwitchedByIgnition" SG_ 1158 NP_LatDirection 0;
BA_ "GenSigStartValue" SG_ 1158 NP_LatDirection 1;
BA_ "GenSigSendType" SG_ 1158 NP_LatDirection 0;
BA_ "GenSigSwitchedByIgnition" SG_ 1158 NP_LongDirection 0;
BA_ "GenSigStartValue" SG_ 1158 NP_LongDirection 1;
BA_ "GenSigSendType" SG_ 1158 NP_LongDirection 0;
BA_ "Fehlerwert" SG_ 1158 NP_Sat 31;
BA_ "GenSigSwitchedByIgnition" SG_ 1158 NP_Sat 0;
BA_ "GenSigStartValue" SG_ 1158 NP_Sat 30;
BA_ "GenSigSendType" SG_ 1158 NP_Sat 0;
BA_ "GenSigSwitchedByIgnition" SG_ 1158 NP_Fix 0;
BA_ "GenSigSendType" SG_ 1158 NP_Fix 0;
BA_ "GenSigSwitchedByIgnition" SG_ 2589283496 POS_MUX 0;
BA_ "GenSigStartValue" SG_ 2589283496 POS_MUX 3;
BA_ "GenSigSendType" SG_ 2589283496 POS_MUX 0;
BA_ "GenSigSwitchedByIgnition" SG_ 2589283496 POS_ODD_EVEN 0;
BA_ "GenSigSendType" SG_ 2589283496 POS_ODD_EVEN 0;
BA_ "GenSigSwitchedByIgnition" SG_ 2589283496 POS_PosStati 0;
BA_ "GenSigSwitchedByIgnition" SG_ 2589283496 POS_Heading 0;
BA_ "GenSigSwitchedByIgnition" SG_ 2589283496 POS_LatDirection 0;
BA_ "Fehlerwert" SG_ 2589283496 POS_LatDegree 134217727;
BA_ "GenSigSwitchedByIgnition" SG_ 2589283496 POS_LatDegree 0;
BA_ "GenSigStartValue" SG_ 2589283496 POS_LatDegree 134217726;
BA_ "GenSigSwitchedByIgnition" SG_ 2589283496 POS_Last_GPS_Sync 0;
BA_ "Fehlerwert" SG_ 2589283496 POS_Heading_Trust 3;
BA_ "GenSigSwitchedByIgnition" SG_ 2589283496 POS_Heading_Trust 0;
BA_ "GenSigSwitchedByIgnition" SG_ 2589283496 POS_UTC_REF 0;
BA_ "GenSigSwitchedByIgnition" SG_ 2589283496 POS_LongDirection 0;
BA_ "Fehlerwert" SG_ 2589283496 POS_LongDegree 268435455;
BA_ "GenSigSwitchedByIgnition" SG_ 2589283496 POS_LongDegree 0;
BA_ "GenSigStartValue" SG_ 2589283496 POS_LongDegree 268435454;
BA_ "GenSigSwitchedByIgnition" SG_ 2600468551 NM_AAG_SNI 0;
BA_ "GenSigStartValue" SG_ 2600468551 NM_AAG_SNI 71;
BA_ "GenSigSwitchedByIgnition" SG_ 2600468551 NM_AAG_CBV_AWB 0;
BA_ "GenSigSwitchedByIgnition" SG_ 2600468551 NM_AAG_CBV_CRI 0;
BA_ "GenSigFuncType" SG_ 2600468551 NM_AAG_CBV_CRI 8;
BA_ "GenSigSwitchedByIgnition" SG_ 2600468551 NM_AAG_NM_State 0;
BA_ "GenSigSwitchedByIgnition" SG_ 2600468551 NM_AAG_Car_Wakeup 0;
BA_ "GenSigSendType" SG_ 2600468551 NM_AAG_Car_Wakeup 3;
BA_ "GenSigSwitchedByIgnition" SG_ 2600468551 NM_AAG_UDS_CC 0;
BA_ "GenSigSwitchedByIgnition" SG_ 2600468551 NM_AAG_NM_aktiv_KL15 0;
BA_ "GenSigSwitchedByIgnition" SG_ 2600468551 NM_AAG_NM_aktiv_Diagnose 0;
BA_ "GenSigSwitchedByIgnition" SG_ 2600468551 NM_AAG_NM_aktiv_Tmin 0;
BA_ "GenSigSwitchedByIgnition" SG_ 2600468551 NM_AAG_NM_aktiv_Anhaenger_erk 0;
BA_ "GenSigSwitchedByIgnition" SG_ 2600468551 NM_AAG_NM_aktiv_AVS_Fehler 0;
BA_ "GenSigSwitchedByIgnition" SG_ 2600468551 NM_AAG_NM_nicht_eingefahren 0;
BA_ "GenSigSwitchedByIgnition" SG_ 2600468551 NM_AAG_NM_KL15_unplausibel 0;
BA_ "GenSigSwitchedByIgnition" SG_ 2600468551 NM_AAG_CAB 0;
BA_ "GenSigSendType" SG_ 2600468551 NM_AAG_CAB 4;
BA_ "GenSigActiveRepetitions" SG_ 2600468551 NM_AAG_CAB 3;
BA_ "GenSigSwitchedByIgnition" SG_ 2600468494 NM_BCM1_SNI 0;
BA_ "GenSigStartValue" SG_ 2600468494 NM_BCM1_SNI 14;
BA_ "GenSigSwitchedByIgnition" SG_ 2600468494 NM_BCM1_CBV_AWB 0;
BA_ "GenSigSwitchedByIgnition" SG_ 2600468494 NM_BCM1_CBV_CRI 0;
BA_ "GenSigFuncType" SG_ 2600468494 NM_BCM1_CBV_CRI 8;
BA_ "GenSigSwitchedByIgnition" SG_ 2600468494 NM_BCM1_NM_State 0;
BA_ "GenSigSwitchedByIgnition" SG_ 2600468494 NM_BCM1_Car_Wakeup 0;
BA_ "GenSigSendType" SG_ 2600468494 NM_BCM1_Car_Wakeup 3;
BA_ "GenSigSwitchedByIgnition" SG_ 2600468494 NM_BCM1_UDS_CC 0;
BA_ "GenSigSwitchedByIgnition" SG_ 2600468494 NM_BCM1_NM_aktiv_KL15 0;
BA_ "GenSigSwitchedByIgnition" SG_ 2600468494 NM_BCM1_NM_aktiv_Diagnose 0;
BA_ "GenSigSwitchedByIgnition" SG_ 2600468494 NM_BCM1_NM_aktiv_Tmin 0;
BA_ "GenSigSwitchedByIgnition" SG_ 2600468494 NM_BCM1_NM_aktiv_Notlaufblinken 0;
BA_ "GenSigSwitchedByIgnition" SG_ 2600468494 NM_BCM1_NM_aktiv_ComingHome 0;
BA_ "GenSigSwitchedByIgnition" SG_ 2600468494 NM_BCM1_NM_aktiv_LeavingHome 0;
BA_ "GenSigSwitchedByIgnition" SG_ 2600468494 NM_BCM1_NM_aktiv_Lichthupe 0;
BA_ "GenSigSwitchedByIgnition" SG_ 2600468494 NM_BCM1_CAB 0;
BA_ "GenSigSendType" SG_ 2600468494 NM_BCM1_CAB 4;
BA_ "GenSigActiveRepetitions" SG_ 2600468494 NM_BCM1_CAB 3;
BA_ "GenSigSwitchedByIgnition" SG_ 2600468619 NM_BCM2_SNI 0;
BA_ "GenSigStartValue" SG_ 2600468619 NM_BCM2_SNI 139;
BA_ "GenSigSwitchedByIgnition" SG_ 2600468619 NM_BCM2_CBV_AWB 0;
BA_ "GenSigSwitchedByIgnition" SG_ 2600468619 NM_BCM2_CBV_CRI 0;
BA_ "GenSigFuncType" SG_ 2600468619 NM_BCM2_CBV_CRI 8;
BA_ "GenSigSwitchedByIgnition" SG_ 2600468619 NM_BCM2_NM_State 0;
BA_ "GenSigSwitchedByIgnition" SG_ 2600468619 NM_BCM2_Car_WakeUp 0;
BA_ "NWM-WakeupAllowed" SG_ 2600468619 NM_BCM2_Car_WakeUp 1;
BA_ "GenSigSendType" SG_ 2600468619 NM_BCM2_Car_WakeUp 3;
BA_ "GenSigSwitchedByIgnition" SG_ 2600468619 NM_BCM2_UDS_CC 0;
BA_ "GenSigSwitchedByIgnition" SG_ 2600468619 NM_BCM2_NM_aktiv_KL15 0;
BA_ "GenSigSwitchedByIgnition" SG_ 2600468619 NM_BCM2_NM_aktiv_Diagnose 0;
BA_ "GenSigSwitchedByIgnition" SG_ 2600468619 NM_BCM2_NM_aktiv_Tmin 0;
BA_ "GenSigSwitchedByIgnition" SG_ 2600468619 NM_BCM2_NM_aktiv_Warnblinken 0;
BA_ "GenSigSwitchedByIgnition" SG_ 2600468619 NM_BCM2_NM_aktiv_Crashblinken 0;
BA_ "GenSigSwitchedByIgnition" SG_ 2600468619 NM_BCM2_NM_aktiv_DWA_Alarm 0;
BA_ "GenSigSwitchedByIgnition" SG_ 2600468619 NM_BCM2_NM_aktiv_Remot_Door_L_Un 0;
BA_ "GenSigSwitchedByIgnition" SG_ 2600468619 NM_BCM2_CAB 0;
BA_ "GenSigSendType" SG_ 2600468619 NM_BCM2_CAB 4;
BA_ "GenSigActiveRepetitions" SG_ 2600468619 NM_BCM2_CAB 3;
BA_ "GenSigSwitchedByIgnition" SG_ 2600468529 NM_ELV_SNI 0;
BA_ "GenSigStartValue" SG_ 2600468529 NM_ELV_SNI 49;
BA_ "GenSigSwitchedByIgnition" SG_ 2600468529 NM_ELV_CBV_AWB 0;
BA_ "GenSigSwitchedByIgnition" SG_ 2600468529 NM_ELV_CBV_CRI 0;
BA_ "GenSigFuncType" SG_ 2600468529 NM_ELV_CBV_CRI 8;
BA_ "GenSigSwitchedByIgnition" SG_ 2600468529 NM_ELV_NM_State 0;
BA_ "GenSigSwitchedByIgnition" SG_ 2600468529 NM_ELV_Car_Wakeup 0;
BA_ "GenSigSendType" SG_ 2600468529 NM_ELV_Car_Wakeup 3;
BA_ "GenSigSwitchedByIgnition" SG_ 2600468529 NM_ELV_UDS_CC 0;
BA_ "GenSigSwitchedByIgnition" SG_ 2600468529 NM_ELV_NM_aktiv_KL15 0;
BA_ "GenSigSwitchedByIgnition" SG_ 2600468529 NM_ELV_NM_aktiv_Diagnose 0;
BA_ "GenSigSwitchedByIgnition" SG_ 2600468529 NM_ELV_NM_aktiv_Tmin 0;
BA_ "GenSigSwitchedByIgnition" SG_ 2600468529 NM_ELV_NM_aktiv_Meldung 0;
BA_ "GenSigSwitchedByIgnition" SG_ 2600468529 NM_ELV_NM_aktiv_Verfahrtrigger 0;
BA_ "GenSigSwitchedByIgnition" SG_ 2600468529 NM_ELV_NM_aktiv_WFS 0;
BA_ "GenSigSwitchedByIgnition" SG_ 2600468529 NM_ELV_CAB 0;
BA_ "GenSigSendType" SG_ 2600468529 NM_ELV_CAB 4;
BA_ "GenSigActiveRepetitions" SG_ 2600468529 NM_ELV_CAB 3;
BA_ "GenSigSwitchedByIgnition" SG_ 2600468496 NM_Gateway_SNI 0;
BA_ "GenSigStartValue" SG_ 2600468496 NM_Gateway_SNI 16;
BA_ "GenSigSwitchedByIgnition" SG_ 2600468496 NM_Gateway_CBV_AWB 0;
BA_ "GenSigSwitchedByIgnition" SG_ 2600468496 NM_Gateway_CBV_CRI 0;
BA_ "GenSigFuncType" SG_ 2600468496 NM_Gateway_CBV_CRI 8;
BA_ "GenSigSwitchedByIgnition" SG_ 2600468496 NM_Gateway_NM_State 0;
BA_ "GenSigSwitchedByIgnition" SG_ 2600468496 NM_Gateway_Car_Wakeup 0;
BA_ "GenSigSendType" SG_ 2600468496 NM_Gateway_Car_Wakeup 3;
BA_ "GenSigSwitchedByIgnition" SG_ 2600468496 NM_Gateway_UDS_CC 0;
BA_ "GenSigSwitchedByIgnition" SG_ 2600468496 NM_Gateway_NM_aktiv_KL15 0;
BA_ "GenSigSwitchedByIgnition" SG_ 2600468496 NM_Gateway_NM_aktiv_Diagnose 0;
BA_ "GenSigSwitchedByIgnition" SG_ 2600468496 NM_Gateway_NM_aktiv_Tmin 0;
BA_ "GenSigSwitchedByIgnition" SG_ 2600468496 NM_Gateway_NM_aktiv_CWU 0;
BA_ "GenSigSwitchedByIgnition" SG_ 2600468496 NM_Gateway_NM_aktiv_FC 0;
BA_ "GenSigSwitchedByIgnition" SG_ 2600468496 NM_Gateway_CAB 0;
BA_ "GenSigSendType" SG_ 2600468496 NM_Gateway_CAB 4;
BA_ "GenSigActiveRepetitions" SG_ 2600468496 NM_Gateway_CAB 3;
BA_ "GenSigSwitchedByIgnition" SG_ 2600468515 NM_HDSG_SNI 0;
BA_ "GenSigStartValue" SG_ 2600468515 NM_HDSG_SNI 35;
BA_ "GenSigSwitchedByIgnition" SG_ 2600468515 NM_HDSG_CBV_AWB 0;
BA_ "GenSigSwitchedByIgnition" SG_ 2600468515 NM_HDSG_CBV_CRI 0;
BA_ "GenSigFuncType" SG_ 2600468515 NM_HDSG_CBV_CRI 8;
BA_ "GenSigSwitchedByIgnition" SG_ 2600468515 NM_HDSG_NM_State 0;
BA_ "GenSigSwitchedByIgnition" SG_ 2600468515 NM_HDSG_Car_Wakeup 0;
BA_ "GenSigSendType" SG_ 2600468515 NM_HDSG_Car_Wakeup 3;
BA_ "GenSigSwitchedByIgnition" SG_ 2600468515 NM_HDSG_UDS_CC 0;
BA_ "GenSigSwitchedByIgnition" SG_ 2600468515 NM_HDSG_NM_aktiv_KL15 0;
BA_ "GenSigSwitchedByIgnition" SG_ 2600468515 NM_HDSG_NM_aktiv_Diagnose 0;
BA_ "GenSigSwitchedByIgnition" SG_ 2600468515 NM_HDSG_NM_aktiv_Tmin 0;
BA_ "GenSigSwitchedByIgnition" SG_ 2600468515 NM_HDSG_Beweg_Heckklappe 0;
BA_ "GenSigSwitchedByIgnition" SG_ 2600468515 NM_HDSG_CAB 0;
BA_ "GenSigSendType" SG_ 2600468515 NM_HDSG_CAB 4;
BA_ "GenSigActiveRepetitions" SG_ 2600468515 NM_HDSG_CAB 3;
BA_ "GenSigSwitchedByIgnition" SG_ 2600468530 NM_Kessy_SNI 0;
BA_ "GenSigStartValue" SG_ 2600468530 NM_Kessy_SNI 50;
BA_ "GenSigSwitchedByIgnition" SG_ 2600468530 NM_Kessy_CBV_AWB 0;
BA_ "GenSigSwitchedByIgnition" SG_ 2600468530 NM_Kessy_CBV_CRI 0;
BA_ "GenSigFuncType" SG_ 2600468530 NM_Kessy_CBV_CRI 8;
BA_ "GenSigSwitchedByIgnition" SG_ 2600468530 NM_Kessy_NM_State 0;
BA_ "GenSigSwitchedByIgnition" SG_ 2600468530 NM_Kessy_Car_Wakeup 0;
BA_ "GenSigSendType" SG_ 2600468530 NM_Kessy_Car_Wakeup 3;
BA_ "GenSigSwitchedByIgnition" SG_ 2600468530 NM_Kessy_UDS_CC 0;
BA_ "GenSigSwitchedByIgnition" SG_ 2600468530 NM_Kessy_NM_aktiv_KL15 0;
BA_ "GenSigSwitchedByIgnition" SG_ 2600468530 NM_Kessy_NM_aktiv_Diagnose 0;
BA_ "GenSigSwitchedByIgnition" SG_ 2600468530 NM_Kessy_NM_aktiv_Tmin 0;
BA_ "GenSigSwitchedByIgnition" SG_ 2600468530 NM_Kessy_NM_aktiv_Meldung 0;
BA_ "GenSigSwitchedByIgnition" SG_ 2600468530 NM_Kessy_NM_aktiv_Anf_Klemmen 0;
BA_ "GenSigSwitchedByIgnition" SG_ 2600468530 NM_Kessy_NM_aktiv_aut_Abschalt 0;
BA_ "GenSigSwitchedByIgnition" SG_ 2600468530 NM_Kessy_CAB 0;
BA_ "GenSigSendType" SG_ 2600468530 NM_Kessy_CAB 4;
BA_ "GenSigActiveRepetitions" SG_ 2600468530 NM_Kessy_CAB 3;
BA_ "GenSigSwitchedByIgnition" SG_ 2600468524 NM_MFG_SNI 0;
BA_ "GenSigStartValue" SG_ 2600468524 NM_MFG_SNI 44;
BA_ "GenSigSwitchedByIgnition" SG_ 2600468524 NM_MFG_CBV_AWB 0;
BA_ "GenSigSwitchedByIgnition" SG_ 2600468524 NM_MFG_CBV_CRI 0;
BA_ "GenSigFuncType" SG_ 2600468524 NM_MFG_CBV_CRI 8;
BA_ "GenSigSwitchedByIgnition" SG_ 2600468524 NM_MFG_NM_State 0;
BA_ "GenSigSwitchedByIgnition" SG_ 2600468524 NM_MFG_Car_Wakeup 0;
BA_ "GenSigSendType" SG_ 2600468524 NM_MFG_Car_Wakeup 3;
BA_ "GenSigSwitchedByIgnition" SG_ 2600468524 NM_MFG_UDS_CC 0;
BA_ "GenSigSwitchedByIgnition" SG_ 2600468524 NM_MFG_NM_aktiv_KL15 0;
BA_ "GenSigSwitchedByIgnition" SG_ 2600468524 NM_MFG_NM_aktiv_Diagnose 0;
BA_ "GenSigSwitchedByIgnition" SG_ 2600468524 NM_MFG_NM_aktiv_Tmin 0;
BA_ "GenSigSwitchedByIgnition" SG_ 2600468524 NM_MFG_CAB 0;
BA_ "GenSigSendType" SG_ 2600468524 NM_MFG_CAB 4;
BA_ "GenSigActiveRepetitions" SG_ 2600468524 NM_MFG_CAB 3;
BA_ "GenSigSwitchedByIgnition" SG_ 2600468612 NM_SAD_SNI 0;
BA_ "GenSigStartValue" SG_ 2600468612 NM_SAD_SNI 132;
BA_ "GenSigSwitchedByIgnition" SG_ 2600468612 NM_SAD_CBV_AWB 0;
BA_ "GenSigSwitchedByIgnition" SG_ 2600468612 NM_SAD_CBV_CRI 0;
BA_ "GenSigFuncType" SG_ 2600468612 NM_SAD_CBV_CRI 8;
BA_ "GenSigSwitchedByIgnition" SG_ 2600468612 NM_SAD_NM_State 0;
BA_ "GenSigSwitchedByIgnition" SG_ 2600468612 NM_SAD_Car_Wakeup 0;
BA_ "GenSigSendType" SG_ 2600468612 NM_SAD_Car_Wakeup 3;
BA_ "GenSigSwitchedByIgnition" SG_ 2600468612 NM_SAD_UDS_CC 0;
BA_ "GenSigSwitchedByIgnition" SG_ 2600468612 NM_SAD_NM_aktiv_KL15 0;
BA_ "GenSigSwitchedByIgnition" SG_ 2600468612 NM_SAD_NM_aktiv_Diagnose 0;
BA_ "GenSigSwitchedByIgnition" SG_ 2600468612 NM_SAD_NM_aktiv_Tmin 0;
BA_ "GenSigSwitchedByIgnition" SG_ 2600468612 NM_SAD_NM_aktiv_Dach_geoeffnet 0;
BA_ "GenSigSwitchedByIgnition" SG_ 2600468612 NM_SAD_NM_aktiv_Dach_Rollo_fahrt 0;
BA_ "GenSigSwitchedByIgnition" SG_ 2600468612 NM_SAD_CAB 0;
BA_ "GenSigSendType" SG_ 2600468612 NM_SAD_CAB 4;
BA_ "GenSigActiveRepetitions" SG_ 2600468612 NM_SAD_CAB 3;
BA_ "GenSigSwitchedByIgnition" SG_ 2600468640 NM_SAD2_SNI 0;
BA_ "GenSigStartValue" SG_ 2600468640 NM_SAD2_SNI 160;
BA_ "GenSigSwitchedByIgnition" SG_ 2600468640 NM_SAD2_CBV_AWB 0;
BA_ "GenSigSwitchedByIgnition" SG_ 2600468640 NM_SAD2_CBV_CRI 0;
BA_ "GenSigFuncType" SG_ 2600468640 NM_SAD2_CBV_CRI 8;
BA_ "GenSigSwitchedByIgnition" SG_ 2600468640 NM_SAD2_NM_State 0;
BA_ "GenSigSwitchedByIgnition" SG_ 2600468640 NM_SAD2_Car_Wakeup 0;
BA_ "GenSigSendType" SG_ 2600468640 NM_SAD2_Car_Wakeup 3;
BA_ "GenSigSwitchedByIgnition" SG_ 2600468640 NM_SAD2_UDS_CC 0;
BA_ "GenSigSwitchedByIgnition" SG_ 2600468640 NM_SAD2_NM_aktiv_KL15 0;
BA_ "GenSigSwitchedByIgnition" SG_ 2600468640 NM_SAD2_NM_aktiv_Diagnose 0;
BA_ "GenSigSwitchedByIgnition" SG_ 2600468640 NM_SAD2_NM_aktiv_Tmin 0;
BA_ "GenSigSwitchedByIgnition" SG_ 2600468640 NM_SAD2_CAB 0;
BA_ "GenSigSendType" SG_ 2600468640 NM_SAD2_CAB 4;
BA_ "GenSigActiveRepetitions" SG_ 2600468640 NM_SAD2_CAB 3;
BA_ "GenSigSwitchedByIgnition" SG_ 2600468635 NM_MSBBR_SNI 0;
BA_ "GenSigStartValue" SG_ 2600468635 NM_MSBBR_SNI 155;
BA_ "GenSigSwitchedByIgnition" SG_ 2600468635 NM_MSBBR_CBV_AWB 0;
BA_ "GenSigSwitchedByIgnition" SG_ 2600468635 NM_MSBBR_CBV_CRI 0;
BA_ "GenSigFuncType" SG_ 2600468635 NM_MSBBR_CBV_CRI 8;
BA_ "GenSigSwitchedByIgnition" SG_ 2600468635 NM_MSBBR_NM_State 0;
BA_ "GenSigSwitchedByIgnition" SG_ 2600468635 NM_MSBBR_Car_Wakeup 0;
BA_ "GenSigSendType" SG_ 2600468635 NM_MSBBR_Car_Wakeup 3;
BA_ "GenSigSwitchedByIgnition" SG_ 2600468635 NM_MSBBR_UDS_CC 0;
BA_ "GenSigSwitchedByIgnition" SG_ 2600468635 NM_MSBBR_NM_aktiv_KL15 0;
BA_ "GenSigSwitchedByIgnition" SG_ 2600468635 NM_MSBBR_NM_aktiv_Diagnose 0;
BA_ "GenSigSwitchedByIgnition" SG_ 2600468635 NM_MSBBR_NM_aktiv_Tmin 0;
BA_ "GenSigSwitchedByIgnition" SG_ 2600468635 NM_MSBBR_CAB 0;
BA_ "GenSigSendType" SG_ 2600468635 NM_MSBBR_CAB 4;
BA_ "GenSigActiveRepetitions" SG_ 2600468635 NM_MSBBR_CAB 3;
BA_ "GenSigSwitchedByIgnition" SG_ 2600468557 NM_Sitzmemo_BFS_SNI 0;
BA_ "GenSigStartValue" SG_ 2600468557 NM_Sitzmemo_BFS_SNI 77;
BA_ "GenSigSwitchedByIgnition" SG_ 2600468557 NM_Sitzmemo_BFS_CBV_AWB 0;
BA_ "GenSigSwitchedByIgnition" SG_ 2600468557 NM_Sitzmemo_BFS_CBV_CRI 0;
BA_ "GenSigFuncType" SG_ 2600468557 NM_Sitzmemo_BFS_CBV_CRI 8;
BA_ "GenSigSwitchedByIgnition" SG_ 2600468557 NM_Sitzmemo_BFS_NM_State 0;
BA_ "GenSigSwitchedByIgnition" SG_ 2600468557 NM_Sitzmemo_BFS_Car_Wakeup 0;
BA_ "GenSigSendType" SG_ 2600468557 NM_Sitzmemo_BFS_Car_Wakeup 3;
BA_ "GenSigSwitchedByIgnition" SG_ 2600468557 NM_Sitzmemo_BFS_UDS_CC 0;
BA_ "GenSigSwitchedByIgnition" SG_ 2600468557 NM_Sitzmemo_BFS_NM_aktiv_KL15 0;
BA_ "GenSigSwitchedByIgnition" SG_ 2600468557 NM_Sitzmemo_BFS_NM_aktiv_Diag 0;
BA_ "GenSigSwitchedByIgnition" SG_ 2600468557 NM_Sitzmemo_BFS_NM_aktiv_Tmin 0;
BA_ "GenSigSwitchedByIgnition" SG_ 2600468557 NM_Sitz_BFS_NM_aktiv_Automlauf 0;
BA_ "GenSigSwitchedByIgnition" SG_ 2600468557 NM_Sitz_BFS_NM_aktiv_Handverst 0;
BA_ "GenSigSwitchedByIgnition" SG_ 2600468557 NM_Sitz_BFS_NM_aktiv_Visualis 0;
BA_ "GenSigSwitchedByIgnition" SG_ 2600468557 NM_Sitzmemo_BFS_CAB 0;
BA_ "GenSigSendType" SG_ 2600468557 NM_Sitzmemo_BFS_CAB 4;
BA_ "GenSigActiveRepetitions" SG_ 2600468557 NM_Sitzmemo_BFS_CAB 3;
BA_ "GenSigSwitchedByIgnition" SG_ 2600468616 NM_Sitz_BFSFo_SNI 0;
BA_ "GenSigStartValue" SG_ 2600468616 NM_Sitz_BFSFo_SNI 136;
BA_ "GenSigSwitchedByIgnition" SG_ 2600468616 NM_Sitz_BFSFo_CBV_AWB 0;
BA_ "GenSigSwitchedByIgnition" SG_ 2600468616 NM_Sitz_BFSFo_CBV_CRI 0;
BA_ "GenSigFuncType" SG_ 2600468616 NM_Sitz_BFSFo_CBV_CRI 8;
BA_ "GenSigSwitchedByIgnition" SG_ 2600468616 NM_Sitz_BFSFo_NM_State 0;
BA_ "GenSigSwitchedByIgnition" SG_ 2600468616 NM_Sitz_BFSFo_Car_Wakeup 0;
BA_ "GenSigSendType" SG_ 2600468616 NM_Sitz_BFSFo_Car_Wakeup 3;
BA_ "GenSigSwitchedByIgnition" SG_ 2600468616 NM_Sitz_BFSFo_UDS_CC 0;
BA_ "GenSigSwitchedByIgnition" SG_ 2600468616 NM_Sitz_BFSFo_NM_aktiv_KL15 0;
BA_ "GenSigSwitchedByIgnition" SG_ 2600468616 NM_Sitz_BFSFo_NM_aktiv_Diagnose 0;
BA_ "GenSigSwitchedByIgnition" SG_ 2600468616 NM_Sitz_BFSFo_NM_aktiv_Tmin 0;
BA_ "GenSigSwitchedByIgnition" SG_ 2600468616 NM_Sitz_BFSFo_NM_aktiv_Automlauf 0;
BA_ "GenSigSwitchedByIgnition" SG_ 2600468616 NM_Sitz_BFSFo_NM_aktiv_Handverst 0;
BA_ "GenSigSwitchedByIgnition" SG_ 2600468616 NM_Sitz_BFSFo_NM_aktiv_BR_anfahr 0;
BA_ "GenSigSwitchedByIgnition" SG_ 2600468616 NM_Sitz_BFSFo_NM_aktiv_Visualis 0;
BA_ "GenSigSwitchedByIgnition" SG_ 2600468616 NM_Sitz_BFSFo_CAB 0;
BA_ "GenSigSendType" SG_ 2600468616 NM_Sitz_BFSFo_CAB 4;
BA_ "GenSigActiveRepetitions" SG_ 2600468616 NM_Sitz_BFSFo_CAB 3;
BA_ "GenSigSwitchedByIgnition" SG_ 2600468556 NM_Sitzmemo_FS_SNI 0;
BA_ "GenSigStartValue" SG_ 2600468556 NM_Sitzmemo_FS_SNI 76;
BA_ "GenSigSwitchedByIgnition" SG_ 2600468556 NM_Sitzmemo_FS_CBV_AWB 0;
BA_ "GenSigSwitchedByIgnition" SG_ 2600468556 NM_Sitzmemo_FS_CBV_CRI 0;
BA_ "GenSigFuncType" SG_ 2600468556 NM_Sitzmemo_FS_CBV_CRI 8;
BA_ "GenSigSwitchedByIgnition" SG_ 2600468556 NM_Sitzmemo_FS_NM_State 0;
BA_ "GenSigSwitchedByIgnition" SG_ 2600468556 NM_Sitzmemo_FS_Car_Wakeup 0;
BA_ "GenSigSendType" SG_ 2600468556 NM_Sitzmemo_FS_Car_Wakeup 3;
BA_ "GenSigSwitchedByIgnition" SG_ 2600468556 NM_Sitzmemo_FS_UDS_CC 0;
BA_ "GenSigSwitchedByIgnition" SG_ 2600468556 NM_Sitzmemo_FS_NM_aktiv_KL15 0;
BA_ "GenSigSwitchedByIgnition" SG_ 2600468556 NM_Sitzmemo_FS_NM_aktiv_Diag 0;
BA_ "GenSigSwitchedByIgnition" SG_ 2600468556 NM_Sitzmemo_FS_NM_aktiv_Tmin 0;
BA_ "GenSigSwitchedByIgnition" SG_ 2600468556 NM_Sitzmemo_FS_NM_aktiv_Autolauf 0;
BA_ "GenSigSwitchedByIgnition" SG_ 2600468556 NM_Sitz_FS_NM_aktiv_Handverst 0;
BA_ "GenSigSwitchedByIgnition" SG_ 2600468556 NM_Sitz_FS_NM_aktiv_Visualis 0;
BA_ "GenSigSwitchedByIgnition" SG_ 2600468556 NM_Sitz_FS_NM_aktiv_Speichern 0;
BA_ "GenSigSwitchedByIgnition" SG_ 2600468556 NM_Sitzmemo_FS_CAB 0;
BA_ "GenSigSendType" SG_ 2600468556 NM_Sitzmemo_FS_CAB 4;
BA_ "GenSigActiveRepetitions" SG_ 2600468556 NM_Sitzmemo_FS_CAB 3;
BA_ "GenSigSwitchedByIgnition" SG_ 2600468615 NM_Sitz_FSFo_SNI 0;
BA_ "GenSigStartValue" SG_ 2600468615 NM_Sitz_FSFo_SNI 135;
BA_ "GenSigSwitchedByIgnition" SG_ 2600468615 NM_Sitz_FSFo_CBV_AWB 0;
BA_ "GenSigSwitchedByIgnition" SG_ 2600468615 NM_Sitz_FSFo_CBV_CRI 0;
BA_ "GenSigFuncType" SG_ 2600468615 NM_Sitz_FSFo_CBV_CRI 8;
BA_ "GenSigSwitchedByIgnition" SG_ 2600468615 NM_Sitz_FSFo_NM_State 0;
BA_ "GenSigSwitchedByIgnition" SG_ 2600468615 NM_Sitz_FSFo_Car_Wakeup 0;
BA_ "GenSigSendType" SG_ 2600468615 NM_Sitz_FSFo_Car_Wakeup 3;
BA_ "GenSigSwitchedByIgnition" SG_ 2600468615 NM_Sitz_FSFo_UDS_CC 0;
BA_ "GenSigSwitchedByIgnition" SG_ 2600468615 NM_Sitz_FSFo_NM_aktiv_KL15 0;
BA_ "GenSigSwitchedByIgnition" SG_ 2600468615 NM_Sitz_FSFo_NM_aktiv_Diagnose 0;
BA_ "GenSigSwitchedByIgnition" SG_ 2600468615 NM_Sitz_FSFo_NM_aktiv_Tmin 0;
BA_ "GenSigSwitchedByIgnition" SG_ 2600468615 NM_Sitz_FSFo_NM_aktiv_Automlauf 0;
BA_ "GenSigSwitchedByIgnition" SG_ 2600468615 NM_Sitz_FSFo_NM_aktiv_Handverst 0;
BA_ "GenSigSwitchedByIgnition" SG_ 2600468615 NM_Sitz_FSFo_NM_aktiv_BR_anfahr 0;
BA_ "GenSigSwitchedByIgnition" SG_ 2600468615 NM_Sitz_FSFo_NM_aktiv_Visualis 0;
BA_ "GenSigSwitchedByIgnition" SG_ 2600468615 NM_Sitz_FSFo_CAB 0;
BA_ "GenSigSendType" SG_ 2600468615 NM_Sitz_FSFo_CAB 4;
BA_ "GenSigActiveRepetitions" SG_ 2600468615 NM_Sitz_FSFo_CAB 3;
BA_REL_ "GenSigTimeoutTime" BU_SG_REL_ BCM1 SG_ 1601 MO_Faktor_Momente_02 5000;
BA_REL_ "GenSigTimeoutTime" BU_SG_REL_ VTS SG_ 1601 MO_Kraftstoffart 5000;
BA_REL_ "GenSigTimeoutTime" BU_SG_REL_ AAG SG_ 394 MO_Start_Art 2000;
BA_REL_ "GenSigTimeoutTime" BU_SG_REL_ BCM1 SG_ 394 MO_Start_Art 2000;
BA_REL_ "GenSigTimeoutTime" BU_SG_REL_ BCM2 SG_ 394 MO_Start_Art 2000;
BA_REL_ "GenSigTimeoutTime" BU_SG_REL_ BCM2 SG_ 394 MO_Tankklappensteuerung 2000;
BA_REL_ "GenSigTimeoutTime" BU_SG_REL_ VTS SG_ 1157 NP_Altitude 5000;
BA_REL_ "GenSigTimeoutTime" BU_SG_REL_ VTS SG_ 1158 NP_LatDegree 5000;
BA_REL_ "GenSigTimeoutTime" BU_SG_REL_ VTS SG_ 1158 NP_LongDegree 5000;
BA_REL_ "GenSigTimeoutTime" BU_SG_REL_ VTS SG_ 1158 NP_LatDirection 5000;
BA_REL_ "GenSigTimeoutTime" BU_SG_REL_ VTS SG_ 1158 NP_LongDirection 5000;
BA_REL_ "GenSigTimeoutTime" BU_SG_REL_ VTS SG_ 1158 NP_Sat 5000;
BA_REL_ "GenSigTimeoutTime" BU_SG_REL_ VTS SG_ 1158 NP_Fix 5000;
BA_REL_ "GenSigTimeoutTime" BU_SG_REL_ VTS SG_ 2589283496 POS_MUX 5000;
BA_REL_ "GenSigTimeoutTime" BU_SG_REL_ VTS SG_ 2589283496 POS_ODD_EVEN 5000;
BA_REL_ "GenSigTimeoutTime" BU_SG_REL_ VTS SG_ 2589283496 POS_PosStati 5000;
BA_REL_ "GenSigTimeoutTime" BU_SG_REL_ VTS SG_ 2589283496 POS_Heading 5000;
BA_REL_ "GenSigTimeoutTime" BU_SG_REL_ VTS SG_ 2589283496 POS_LatDirection 5000;
BA_REL_ "GenSigTimeoutTime" BU_SG_REL_ VTS SG_ 2589283496 POS_LatDegree 5000;
BA_REL_ "GenSigTimeoutTime" BU_SG_REL_ VTS SG_ 2589283496 POS_Last_GPS_Sync 5000;
BA_REL_ "GenSigTimeoutTime" BU_SG_REL_ VTS SG_ 2589283496 POS_Heading_Trust 5000;
BA_REL_ "GenSigTimeoutTime" BU_SG_REL_ VTS SG_ 2589283496 POS_UTC_REF 5000;
BA_REL_ "GenSigTimeoutTime" BU_SG_REL_ VTS SG_ 2589283496 POS_LongDirection 5000;
BA_REL_ "GenSigTimeoutTime" BU_SG_REL_ VTS SG_ 2589283496 POS_LongDegree 5000;
BA_REL_ "GenSigTimeoutTime" BU_SG_REL_ AAG SG_ 2600468551 NM_AAG_SNI 2000;
BA_REL_ "GenSigTimeoutTime" BU_SG_REL_ BCM1 SG_ 2600468551 NM_AAG_SNI 2000;
BA_REL_ "GenSigTimeoutTime" BU_SG_REL_ BCM2 SG_ 2600468551 NM_AAG_SNI 2000;
BA_REL_ "GenSigTimeoutTime" BU_SG_REL_ ELV SG_ 2600468551 NM_AAG_SNI 2000;
BA_REL_ "GenSigTimeoutTime" BU_SG_REL_ Gateway SG_ 2600468551 NM_AAG_SNI 2000;
BA_REL_ "GenSigTimeoutTime" BU_SG_REL_ HDSG SG_ 2600468551 NM_AAG_SNI 2000;
BA_REL_ "GenSigTimeoutTime" BU_SG_REL_ IEZS SG_ 2600468551 NM_AAG_SNI 2000;
BA_REL_ "GenSigTimeoutTime" BU_SG_REL_ MFG SG_ 2600468551 NM_AAG_SNI 2000;
BA_REL_ "GenSigTimeoutTime" BU_SG_REL_ MSBBR SG_ 2600468551 NM_AAG_SNI 2000;
BA_REL_ "GenSigTimeoutTime" BU_SG_REL_ SAD SG_ 2600468551 NM_AAG_SNI 2000;
BA_REL_ "GenSigTimeoutTime" BU_SG_REL_ SAD2 SG_ 2600468551 NM_AAG_SNI 2000;
BA_REL_ "GenSigTimeoutTime" BU_SG_REL_ SitzMem_BFS SG_ 2600468551 NM_AAG_SNI 2000;
BA_REL_ "GenSigTimeoutTime" BU_SG_REL_ SitzMem_FS SG_ 2600468551 NM_AAG_SNI 2000;
BA_REL_ "GenSigTimeoutTime" BU_SG_REL_ SitzMem_HBFS SG_ 2600468551 NM_AAG_SNI 2000;
BA_REL_ "GenSigTimeoutTime" BU_SG_REL_ SitzMem_HFS SG_ 2600468551 NM_AAG_SNI 2000;
BA_REL_ "GenSigTimeoutTime" BU_SG_REL_ SitzMem_SR3 SG_ 2600468551 NM_AAG_SNI 2000;
BA_REL_ "GenSigTimeoutTime" BU_SG_REL_ SpoilerSG SG_ 2600468551 NM_AAG_SNI 2000;
BA_REL_ "GenSigTimeoutTime" BU_SG_REL_ TSG_BFS SG_ 2600468551 NM_AAG_SNI 2000;
BA_REL_ "GenSigTimeoutTime" BU_SG_REL_ TSG_FS SG_ 2600468551 NM_AAG_SNI 2000;
BA_REL_ "GenSigTimeoutTime" BU_SG_REL_ VSG SG_ 2600468551 NM_AAG_SNI 2000;
BA_REL_ "GenSigTimeoutTime" BU_SG_REL_ VTS SG_ 2600468551 NM_AAG_SNI 2000;
BA_REL_ "GenSigTimeoutTime" BU_SG_REL_ Gateway SG_ 2600468551 NM_AAG_CBV_AWB 2000;
BA_REL_ "GenSigTimeoutTime" BU_SG_REL_ AAG SG_ 2600468551 NM_AAG_CBV_CRI 2000;
BA_REL_ "GenSigTimeoutTime" BU_SG_REL_ BCM1 SG_ 2600468551 NM_AAG_CBV_CRI 2000;
BA_REL_ "GenSigTimeoutTime" BU_SG_REL_ BCM2 SG_ 2600468551 NM_AAG_CBV_CRI 2000;
BA_REL_ "GenSigTimeoutTime" BU_SG_REL_ ELV SG_ 2600468551 NM_AAG_CBV_CRI 2000;
BA_REL_ "GenSigTimeoutTime" BU_SG_REL_ Gateway SG_ 2600468551 NM_AAG_CBV_CRI 2000;
BA_REL_ "GenSigTimeoutTime" BU_SG_REL_ HDSG SG_ 2600468551 NM_AAG_CBV_CRI 2000;
BA_REL_ "GenSigTimeoutTime" BU_SG_REL_ IEZS SG_ 2600468551 NM_AAG_CBV_CRI 2000;
BA_REL_ "GenSigTimeoutTime" BU_SG_REL_ MFG SG_ 2600468551 NM_AAG_CBV_CRI 2000;
BA_REL_ "GenSigTimeoutTime" BU_SG_REL_ MSBBR SG_ 2600468551 NM_AAG_CBV_CRI 2000;
BA_REL_ "GenSigTimeoutTime" BU_SG_REL_ SAD SG_ 2600468551 NM_AAG_CBV_CRI 2000;
BA_REL_ "GenSigTimeoutTime" BU_SG_REL_ SAD2 SG_ 2600468551 NM_AAG_CBV_CRI 2000;
BA_REL_ "GenSigTimeoutTime" BU_SG_REL_ SitzMem_BFS SG_ 2600468551 NM_AAG_CBV_CRI 2000;
BA_REL_ "GenSigTimeoutTime" BU_SG_REL_ SitzMem_FS SG_ 2600468551 NM_AAG_CBV_CRI 2000;
BA_REL_ "GenSigTimeoutTime" BU_SG_REL_ SitzMem_HBFS SG_ 2600468551 NM_AAG_CBV_CRI 2000;
BA_REL_ "GenSigTimeoutTime" BU_SG_REL_ SitzMem_HFS SG_ 2600468551 NM_AAG_CBV_CRI 2000;
BA_REL_ "GenSigTimeoutTime" BU_SG_REL_ SitzMem_SR3 SG_ 2600468551 NM_AAG_CBV_CRI 2000;
BA_REL_ "GenSigTimeoutTime" BU_SG_REL_ SpoilerSG SG_ 2600468551 NM_AAG_CBV_CRI 2000;
BA_REL_ "GenSigTimeoutTime" BU_SG_REL_ TSG_BFS SG_ 2600468551 NM_AAG_CBV_CRI 2000;
BA_REL_ "GenSigTimeoutTime" BU_SG_REL_ TSG_FS SG_ 2600468551 NM_AAG_CBV_CRI 2000;
BA_REL_ "GenSigTimeoutTime" BU_SG_REL_ VSG SG_ 2600468551 NM_AAG_CBV_CRI 2000;
BA_REL_ "GenSigTimeoutTime" BU_SG_REL_ VTS SG_ 2600468551 NM_AAG_CBV_CRI 2000;
BA_REL_ "GenSigTimeoutTime" BU_SG_REL_ Gateway SG_ 2600468551 NM_AAG_Car_Wakeup 2000;
BA_REL_ "GenSigTimeoutTime" BU_SG_REL_ AAG SG_ 2600468551 NM_AAG_CAB 2000;
BA_REL_ "GenSigTimeoutTime" BU_SG_REL_ BCM1 SG_ 2600468551 NM_AAG_CAB 2000;
BA_REL_ "GenSigTimeoutTime" BU_SG_REL_ BCM2 SG_ 2600468551 NM_AAG_CAB 2000;
BA_REL_ "GenSigTimeoutTime" BU_SG_REL_ ELV SG_ 2600468551 NM_AAG_CAB 2000;
BA_REL_ "GenSigTimeoutTime" BU_SG_REL_ Gateway SG_ 2600468551 NM_AAG_CAB 2000;
BA_REL_ "GenSigTimeoutTime" BU_SG_REL_ HDSG SG_ 2600468551 NM_AAG_CAB 2000;
BA_REL_ "GenSigTimeoutTime" BU_SG_REL_ IEZS SG_ 2600468551 NM_AAG_CAB 2000;
BA_REL_ "GenSigTimeoutTime" BU_SG_REL_ MFG SG_ 2600468551 NM_AAG_CAB 2000;
BA_REL_ "GenSigTimeoutTime" BU_SG_REL_ MSBBR SG_ 2600468551 NM_AAG_CAB 2000;
BA_REL_ "GenSigTimeoutTime" BU_SG_REL_ SAD SG_ 2600468551 NM_AAG_CAB 2000;
BA_REL_ "GenSigTimeoutTime" BU_SG_REL_ SAD2 SG_ 2600468551 NM_AAG_CAB 2000;
BA_REL_ "GenSigTimeoutTime" BU_SG_REL_ SitzMem_BFS SG_ 2600468551 NM_AAG_CAB 2000;
BA_REL_ "GenSigTimeoutTime" BU_SG_REL_ SitzMem_FS SG_ 2600468551 NM_AAG_CAB 2000;
BA_REL_ "GenSigTimeoutTime" BU_SG_REL_ SitzMem_HBFS SG_ 2600468551 NM_AAG_CAB 2000;
BA_REL_ "GenSigTimeoutTime" BU_SG_REL_ SitzMem_HFS SG_ 2600468551 NM_AAG_CAB 2000;
BA_REL_ "GenSigTimeoutTime" BU_SG_REL_ SitzMem_SR3 SG_ 2600468551 NM_AAG_CAB 2000;
BA_REL_ "GenSigTimeoutTime" BU_SG_REL_ SpoilerSG SG_ 2600468551 NM_AAG_CAB 2000;
BA_REL_ "GenSigTimeoutTime" BU_SG_REL_ TSG_BFS SG_ 2600468551 NM_AAG_CAB 2000;
BA_REL_ "GenSigTimeoutTime" BU_SG_REL_ TSG_FS SG_ 2600468551 NM_AAG_CAB 2000;
BA_REL_ "GenSigTimeoutTime" BU_SG_REL_ VSG SG_ 2600468551 NM_AAG_CAB 2000;
BA_REL_ "GenSigTimeoutTime" BU_SG_REL_ VTS SG_ 2600468551 NM_AAG_CAB 2000;
BA_REL_ "GenSigTimeoutTime" BU_SG_REL_ AAG SG_ 2600468494 NM_BCM1_SNI 2000;
BA_REL_ "GenSigTimeoutTime" BU_SG_REL_ BCM1 SG_ 2600468494 NM_BCM1_SNI 2000;
BA_REL_ "GenSigTimeoutTime" BU_SG_REL_ BCM2 SG_ 2600468494 NM_BCM1_SNI 2000;
BA_REL_ "GenSigTimeoutTime" BU_SG_REL_ ELV SG_ 2600468494 NM_BCM1_SNI 2000;
BA_REL_ "GenSigTimeoutTime" BU_SG_REL_ Gateway SG_ 2600468494 NM_BCM1_SNI 2000;
BA_REL_ "GenSigTimeoutTime" BU_SG_REL_ HDSG SG_ 2600468494 NM_BCM1_SNI 2000;
BA_REL_ "GenSigTimeoutTime" BU_SG_REL_ IEZS SG_ 2600468494 NM_BCM1_SNI 2000;
BA_REL_ "GenSigTimeoutTime" BU_SG_REL_ MFG SG_ 2600468494 NM_BCM1_SNI 2000;
BA_REL_ "GenSigTimeoutTime" BU_SG_REL_ MSBBR SG_ 2600468494 NM_BCM1_SNI 2000;
BA_REL_ "GenSigTimeoutTime" BU_SG_REL_ SAD SG_ 2600468494 NM_BCM1_SNI 2000;
BA_REL_ "GenSigTimeoutTime" BU_SG_REL_ SAD2 SG_ 2600468494 NM_BCM1_SNI 2000;
BA_REL_ "GenSigTimeoutTime" BU_SG_REL_ SitzMem_BFS SG_ 2600468494 NM_BCM1_SNI 2000;
BA_REL_ "GenSigTimeoutTime" BU_SG_REL_ SitzMem_FS SG_ 2600468494 NM_BCM1_SNI 2000;
BA_REL_ "GenSigTimeoutTime" BU_SG_REL_ SitzMem_HBFS SG_ 2600468494 NM_BCM1_SNI 2000;
BA_REL_ "GenSigTimeoutTime" BU_SG_REL_ SitzMem_HFS SG_ 2600468494 NM_BCM1_SNI 2000;
BA_REL_ "GenSigTimeoutTime" BU_SG_REL_ SitzMem_SR3 SG_ 2600468494 NM_BCM1_SNI 2000;
BA_REL_ "GenSigTimeoutTime" BU_SG_REL_ SpoilerSG SG_ 2600468494 NM_BCM1_SNI 2000;
BA_REL_ "GenSigTimeoutTime" BU_SG_REL_ TSG_BFS SG_ 2600468494 NM_BCM1_SNI 2000;
BA_REL_ "GenSigTimeoutTime" BU_SG_REL_ TSG_FS SG_ 2600468494 NM_BCM1_SNI 2000;
BA_REL_ "GenSigTimeoutTime" BU_SG_REL_ VSG SG_ 2600468494 NM_BCM1_SNI 2000;
BA_REL_ "GenSigTimeoutTime" BU_SG_REL_ VTS SG_ 2600468494 NM_BCM1_SNI 2000;
BA_REL_ "GenSigTimeoutTime" BU_SG_REL_ Gateway SG_ 2600468494 NM_BCM1_CBV_AWB 2000;
BA_REL_ "GenSigTimeoutTime" BU_SG_REL_ AAG SG_ 2600468494 NM_BCM1_CBV_CRI 2000;
BA_REL_ "GenSigTimeoutTime" BU_SG_REL_ BCM1 SG_ 2600468494 NM_BCM1_CBV_CRI 2000;
BA_REL_ "GenSigTimeoutTime" BU_SG_REL_ BCM2 SG_ 2600468494 NM_BCM1_CBV_CRI 2000;
BA_REL_ "GenSigTimeoutTime" BU_SG_REL_ ELV SG_ 2600468494 NM_BCM1_CBV_CRI 2000;
BA_REL_ "GenSigTimeoutTime" BU_SG_REL_ Gateway SG_ 2600468494 NM_BCM1_CBV_CRI 2000;
BA_REL_ "GenSigTimeoutTime" BU_SG_REL_ HDSG SG_ 2600468494 NM_BCM1_CBV_CRI 2000;
BA_REL_ "GenSigTimeoutTime" BU_SG_REL_ IEZS SG_ 2600468494 NM_BCM1_CBV_CRI 2000;
BA_REL_ "GenSigTimeoutTime" BU_SG_REL_ MFG SG_ 2600468494 NM_BCM1_CBV_CRI 2000;
BA_REL_ "GenSigTimeoutTime" BU_SG_REL_ MSBBR SG_ 2600468494 NM_BCM1_CBV_CRI 2000;
BA_REL_ "GenSigTimeoutTime" BU_SG_REL_ SAD SG_ 2600468494 NM_BCM1_CBV_CRI 2000;
BA_REL_ "GenSigTimeoutTime" BU_SG_REL_ SAD2 SG_ 2600468494 NM_BCM1_CBV_CRI 2000;
BA_REL_ "GenSigTimeoutTime" BU_SG_REL_ SitzMem_BFS SG_ 2600468494 NM_BCM1_CBV_CRI 2000;
BA_REL_ "GenSigTimeoutTime" BU_SG_REL_ SitzMem_FS SG_ 2600468494 NM_BCM1_CBV_CRI 2000;
BA_REL_ "GenSigTimeoutTime" BU_SG_REL_ SitzMem_HBFS SG_ 2600468494 NM_BCM1_CBV_CRI 2000;
BA_REL_ "GenSigTimeoutTime" BU_SG_REL_ SitzMem_HFS SG_ 2600468494 NM_BCM1_CBV_CRI 2000;
BA_REL_ "GenSigTimeoutTime" BU_SG_REL_ SitzMem_SR3 SG_ 2600468494 NM_BCM1_CBV_CRI 2000;
BA_REL_ "GenSigTimeoutTime" BU_SG_REL_ SpoilerSG SG_ 2600468494 NM_BCM1_CBV_CRI 2000;
BA_REL_ "GenSigTimeoutTime" BU_SG_REL_ TSG_BFS SG_ 2600468494 NM_BCM1_CBV_CRI 2000;
BA_REL_ "GenSigTimeoutTime" BU_SG_REL_ TSG_FS SG_ 2600468494 NM_BCM1_CBV_CRI 2000;
BA_REL_ "GenSigTimeoutTime" BU_SG_REL_ VSG SG_ 2600468494 NM_BCM1_CBV_CRI 2000;
BA_REL_ "GenSigTimeoutTime" BU_SG_REL_ VTS SG_ 2600468494 NM_BCM1_CBV_CRI 2000;
BA_REL_ "GenSigTimeoutTime" BU_SG_REL_ Gateway SG_ 2600468494 NM_BCM1_Car_Wakeup 2000;
BA_REL_ "GenSigTimeoutTime" BU_SG_REL_ AAG SG_ 2600468494 NM_BCM1_CAB 2000;
BA_REL_ "GenSigTimeoutTime" BU_SG_REL_ BCM1 SG_ 2600468494 NM_BCM1_CAB 2000;
BA_REL_ "GenSigTimeoutTime" BU_SG_REL_ BCM2 SG_ 2600468494 NM_BCM1_CAB 2000;
BA_REL_ "GenSigTimeoutTime" BU_SG_REL_ ELV SG_ 2600468494 NM_BCM1_CAB 2000;
BA_REL_ "GenSigTimeoutTime" BU_SG_REL_ Gateway SG_ 2600468494 NM_BCM1_CAB 2000;
BA_REL_ "GenSigTimeoutTime" BU_SG_REL_ HDSG SG_ 2600468494 NM_BCM1_CAB 2000;
BA_REL_ "GenSigTimeoutTime" BU_SG_REL_ IEZS SG_ 2600468494 NM_BCM1_CAB 2000;
BA_REL_ "GenSigTimeoutTime" BU_SG_REL_ MFG SG_ 2600468494 NM_BCM1_CAB 2000;
BA_REL_ "GenSigTimeoutTime" BU_SG_REL_ MSBBR SG_ 2600468494 NM_BCM1_CAB 2000;
BA_REL_ "GenSigTimeoutTime" BU_SG_REL_ SAD SG_ 2600468494 NM_BCM1_CAB 2000;
BA_REL_ "GenSigTimeoutTime" BU_SG_REL_ SAD2 SG_ 2600468494 NM_BCM1_CAB 2000;
BA_REL_ "GenSigTimeoutTime" BU_SG_REL_ SitzMem_BFS SG_ 2600468494 NM_BCM1_CAB 2000;
BA_REL_ "GenSigTimeoutTime" BU_SG_REL_ SitzMem_FS SG_ 2600468494 NM_BCM1_CAB 2000;
BA_REL_ "GenSigTimeoutTime" BU_SG_REL_ SitzMem_HBFS SG_ 2600468494 NM_BCM1_CAB 2000;
BA_REL_ "GenSigTimeoutTime" BU_SG_REL_ SitzMem_HFS SG_ 2600468494 NM_BCM1_CAB 2000;
BA_REL_ "GenSigTimeoutTime" BU_SG_REL_ SitzMem_SR3 SG_ 2600468494 NM_BCM1_CAB 2000;
BA_REL_ "GenSigTimeoutTime" BU_SG_REL_ SpoilerSG SG_ 2600468494 NM_BCM1_CAB 2000;
BA_REL_ "GenSigTimeoutTime" BU_SG_REL_ TSG_BFS SG_ 2600468494 NM_BCM1_CAB 2000;
BA_REL_ "GenSigTimeoutTime" BU_SG_REL_ TSG_FS SG_ 2600468494 NM_BCM1_CAB 2000;
BA_REL_ "GenSigTimeoutTime" BU_SG_REL_ VSG SG_ 2600468494 NM_BCM1_CAB 2000;
BA_REL_ "GenSigTimeoutTime" BU_SG_REL_ VTS SG_ 2600468494 NM_BCM1_CAB 2000;
BA_REL_ "GenSigTimeoutTime" BU_SG_REL_ AAG SG_ 2600468619 NM_BCM2_SNI 2000;
BA_REL_ "GenSigTimeoutTime" BU_SG_REL_ BCM1 SG_ 2600468619 NM_BCM2_SNI 2000;
BA_REL_ "GenSigTimeoutTime" BU_SG_REL_ BCM2 SG_ 2600468619 NM_BCM2_SNI 2000;
BA_REL_ "GenSigTimeoutTime" BU_SG_REL_ ELV SG_ 2600468619 NM_BCM2_SNI 2000;
BA_REL_ "GenSigTimeoutTime" BU_SG_REL_ Gateway SG_ 2600468619 NM_BCM2_SNI 2000;
BA_REL_ "GenSigTimeoutTime" BU_SG_REL_ HDSG SG_ 2600468619 NM_BCM2_SNI 2000;
BA_REL_ "GenSigTimeoutTime" BU_SG_REL_ IEZS SG_ 2600468619 NM_BCM2_SNI 2000;
BA_REL_ "GenSigTimeoutTime" BU_SG_REL_ MFG SG_ 2600468619 NM_BCM2_SNI 2000;
BA_REL_ "GenSigTimeoutTime" BU_SG_REL_ MSBBR SG_ 2600468619 NM_BCM2_SNI 2000;
BA_REL_ "GenSigTimeoutTime" BU_SG_REL_ SAD SG_ 2600468619 NM_BCM2_SNI 2000;
BA_REL_ "GenSigTimeoutTime" BU_SG_REL_ SAD2 SG_ 2600468619 NM_BCM2_SNI 2000;
BA_REL_ "GenSigTimeoutTime" BU_SG_REL_ SitzMem_BFS SG_ 2600468619 NM_BCM2_SNI 2000;
BA_REL_ "GenSigTimeoutTime" BU_SG_REL_ SitzMem_FS SG_ 2600468619 NM_BCM2_SNI 2000;
BA_REL_ "GenSigTimeoutTime" BU_SG_REL_ SitzMem_HBFS SG_ 2600468619 NM_BCM2_SNI 2000;
BA_REL_ "GenSigTimeoutTime" BU_SG_REL_ SitzMem_HFS SG_ 2600468619 NM_BCM2_SNI 2000;
BA_REL_ "GenSigTimeoutTime" BU_SG_REL_ SitzMem_SR3 SG_ 2600468619 NM_BCM2_SNI 2000;
BA_REL_ "GenSigTimeoutTime" BU_SG_REL_ SpoilerSG SG_ 2600468619 NM_BCM2_SNI 2000;
BA_REL_ "GenSigTimeoutTime" BU_SG_REL_ TSG_BFS SG_ 2600468619 NM_BCM2_SNI 2000;
BA_REL_ "GenSigTimeoutTime" BU_SG_REL_ TSG_FS SG_ 2600468619 NM_BCM2_SNI 2000;
BA_REL_ "GenSigTimeoutTime" BU_SG_REL_ VSG SG_ 2600468619 NM_BCM2_SNI 2000;
BA_REL_ "GenSigTimeoutTime" BU_SG_REL_ VTS SG_ 2600468619 NM_BCM2_SNI 2000;
BA_REL_ "GenSigTimeoutTime" BU_SG_REL_ Gateway SG_ 2600468619 NM_BCM2_CBV_AWB 2000;
BA_REL_ "GenSigTimeoutTime" BU_SG_REL_ AAG SG_ 2600468619 NM_BCM2_CBV_CRI 2000;
BA_REL_ "GenSigTimeoutTime" BU_SG_REL_ BCM1 SG_ 2600468619 NM_BCM2_CBV_CRI 2000;
BA_REL_ "GenSigTimeoutTime" BU_SG_REL_ BCM2 SG_ 2600468619 NM_BCM2_CBV_CRI 2000;
BA_REL_ "GenSigTimeoutTime" BU_SG_REL_ ELV SG_ 2600468619 NM_BCM2_CBV_CRI 2000;
BA_REL_ "GenSigTimeoutTime" BU_SG_REL_ Gateway SG_ 2600468619 NM_BCM2_CBV_CRI 2000;
BA_REL_ "GenSigTimeoutTime" BU_SG_REL_ HDSG SG_ 2600468619 NM_BCM2_CBV_CRI 2000;
BA_REL_ "GenSigTimeoutTime" BU_SG_REL_ IEZS SG_ 2600468619 NM_BCM2_CBV_CRI 2000;
BA_REL_ "GenSigTimeoutTime" BU_SG_REL_ MFG SG_ 2600468619 NM_BCM2_CBV_CRI 2000;
BA_REL_ "GenSigTimeoutTime" BU_SG_REL_ MSBBR SG_ 2600468619 NM_BCM2_CBV_CRI 2000;
BA_REL_ "GenSigTimeoutTime" BU_SG_REL_ SAD SG_ 2600468619 NM_BCM2_CBV_CRI 2000;
BA_REL_ "GenSigTimeoutTime" BU_SG_REL_ SAD2 SG_ 2600468619 NM_BCM2_CBV_CRI 2000;
BA_REL_ "GenSigTimeoutTime" BU_SG_REL_ SitzMem_BFS SG_ 2600468619 NM_BCM2_CBV_CRI 2000;
BA_REL_ "GenSigTimeoutTime" BU_SG_REL_ SitzMem_FS SG_ 2600468619 NM_BCM2_CBV_CRI 2000;
BA_REL_ "GenSigTimeoutTime" BU_SG_REL_ SitzMem_HBFS SG_ 2600468619 NM_BCM2_CBV_CRI 2000;
BA_REL_ "GenSigTimeoutTime" BU_SG_REL_ SitzMem_HFS SG_ 2600468619 NM_BCM2_CBV_CRI 2000;
BA_REL_ "GenSigTimeoutTime" BU_SG_REL_ SitzMem_SR3 SG_ 2600468619 NM_BCM2_CBV_CRI 2000;
BA_REL_ "GenSigTimeoutTime" BU_SG_REL_ SpoilerSG SG_ 2600468619 NM_BCM2_CBV_CRI 2000;
BA_REL_ "GenSigTimeoutTime" BU_SG_REL_ TSG_BFS SG_ 2600468619 NM_BCM2_CBV_CRI 2000;
BA_REL_ "GenSigTimeoutTime" BU_SG_REL_ TSG_FS SG_ 2600468619 NM_BCM2_CBV_CRI 2000;
BA_REL_ "GenSigTimeoutTime" BU_SG_REL_ VSG SG_ 2600468619 NM_BCM2_CBV_CRI 2000;
BA_REL_ "GenSigTimeoutTime" BU_SG_REL_ VTS SG_ 2600468619 NM_BCM2_CBV_CRI 2000;
BA_REL_ "GenSigTimeoutTime" BU_SG_REL_ Gateway SG_ 2600468619 NM_BCM2_Car_WakeUp 2000;
BA_REL_ "GenSigTimeoutTime" BU_SG_REL_ AAG SG_ 2600468619 NM_BCM2_CAB 2000;
BA_REL_ "GenSigTimeoutTime" BU_SG_REL_ BCM1 SG_ 2600468619 NM_BCM2_CAB 2000;
BA_REL_ "GenSigTimeoutTime" BU_SG_REL_ BCM2 SG_ 2600468619 NM_BCM2_CAB 2000;
BA_REL_ "GenSigTimeoutTime" BU_SG_REL_ ELV SG_ 2600468619 NM_BCM2_CAB 2000;
BA_REL_ "GenSigTimeoutTime" BU_SG_REL_ Gateway SG_ 2600468619 NM_BCM2_CAB 2000;
BA_REL_ "GenSigTimeoutTime" BU_SG_REL_ HDSG SG_ 2600468619 NM_BCM2_CAB 2000;
BA_REL_ "GenSigTimeoutTime" BU_SG_REL_ IEZS SG_ 2600468619 NM_BCM2_CAB 2000;
BA_REL_ "GenSigTimeoutTime" BU_SG_REL_ MFG SG_ 2600468619 NM_BCM2_CAB 2000;
BA_REL_ "GenSigTimeoutTime" BU_SG_REL_ MSBBR SG_ 2600468619 NM_BCM2_CAB 2000;
BA_REL_ "GenSigTimeoutTime" BU_SG_REL_ SAD SG_ 2600468619 NM_BCM2_CAB 2000;
BA_REL_ "GenSigTimeoutTime" BU_SG_REL_ SAD2 SG_ 2600468619 NM_BCM2_CAB 2000;
BA_REL_ "GenSigTimeoutTime" BU_SG_REL_ SitzMem_BFS SG_ 2600468619 NM_BCM2_CAB 2000;
BA_REL_ "GenSigTimeoutTime" BU_SG_REL_ SitzMem_FS SG_ 2600468619 NM_BCM2_CAB 2000;
BA_REL_ "GenSigTimeoutTime" BU_SG_REL_ SitzMem_HBFS SG_ 2600468619 NM_BCM2_CAB 2000;
BA_REL_ "GenSigTimeoutTime" BU_SG_REL_ SitzMem_HFS SG_ 2600468619 NM_BCM2_CAB 2000;
BA_REL_ "GenSigTimeoutTime" BU_SG_REL_ SitzMem_SR3 SG_ 2600468619 NM_BCM2_CAB 2000;
BA_REL_ "GenSigTimeoutTime" BU_SG_REL_ SpoilerSG SG_ 2600468619 NM_BCM2_CAB 2000;
BA_REL_ "GenSigTimeoutTime" BU_SG_REL_ TSG_BFS SG_ 2600468619 NM_BCM2_CAB 2000;
BA_REL_ "GenSigTimeoutTime" BU_SG_REL_ TSG_FS SG_ 2600468619 NM_BCM2_CAB 2000;
BA_REL_ "GenSigTimeoutTime" BU_SG_REL_ VSG SG_ 2600468619 NM_BCM2_CAB 2000;
BA_REL_ "GenSigTimeoutTime" BU_SG_REL_ VTS SG_ 2600468619 NM_BCM2_CAB 2000;
BA_REL_ "GenSigTimeoutTime" BU_SG_REL_ AAG SG_ 2600468529 NM_ELV_SNI 2000;
BA_REL_ "GenSigTimeoutTime" BU_SG_REL_ BCM1 SG_ 2600468529 NM_ELV_SNI 2000;
BA_REL_ "GenSigTimeoutTime" BU_SG_REL_ BCM2 SG_ 2600468529 NM_ELV_SNI 2000;
BA_REL_ "GenSigTimeoutTime" BU_SG_REL_ ELV SG_ 2600468529 NM_ELV_SNI 2000;
BA_REL_ "GenSigTimeoutTime" BU_SG_REL_ Gateway SG_ 2600468529 NM_ELV_SNI 2000;
BA_REL_ "GenSigTimeoutTime" BU_SG_REL_ HDSG SG_ 2600468529 NM_ELV_SNI 2000;
BA_REL_ "GenSigTimeoutTime" BU_SG_REL_ IEZS SG_ 2600468529 NM_ELV_SNI 2000;
BA_REL_ "GenSigTimeoutTime" BU_SG_REL_ MFG SG_ 2600468529 NM_ELV_SNI 2000;
BA_REL_ "GenSigTimeoutTime" BU_SG_REL_ MSBBR SG_ 2600468529 NM_ELV_SNI 2000;
BA_REL_ "GenSigTimeoutTime" BU_SG_REL_ SAD SG_ 2600468529 NM_ELV_SNI 2000;
BA_REL_ "GenSigTimeoutTime" BU_SG_REL_ SAD2 SG_ 2600468529 NM_ELV_SNI 2000;
BA_REL_ "GenSigTimeoutTime" BU_SG_REL_ SitzMem_BFS SG_ 2600468529 NM_ELV_SNI 2000;
BA_REL_ "GenSigTimeoutTime" BU_SG_REL_ SitzMem_FS SG_ 2600468529 NM_ELV_SNI 2000;
BA_REL_ "GenSigTimeoutTime" BU_SG_REL_ SitzMem_HBFS SG_ 2600468529 NM_ELV_SNI 2000;
BA_REL_ "GenSigTimeoutTime" BU_SG_REL_ SitzMem_HFS SG_ 2600468529 NM_ELV_SNI 2000;
BA_REL_ "GenSigTimeoutTime" BU_SG_REL_ SitzMem_SR3 SG_ 2600468529 NM_ELV_SNI 2000;
BA_REL_ "GenSigTimeoutTime" BU_SG_REL_ SpoilerSG SG_ 2600468529 NM_ELV_SNI 2000;
BA_REL_ "GenSigTimeoutTime" BU_SG_REL_ TSG_BFS SG_ 2600468529 NM_ELV_SNI 2000;
BA_REL_ "GenSigTimeoutTime" BU_SG_REL_ TSG_FS SG_ 2600468529 NM_ELV_SNI 2000;
BA_REL_ "GenSigTimeoutTime" BU_SG_REL_ VSG SG_ 2600468529 NM_ELV_SNI 2000;
BA_REL_ "GenSigTimeoutTime" BU_SG_REL_ VTS SG_ 2600468529 NM_ELV_SNI 2000;
BA_REL_ "GenSigTimeoutTime" BU_SG_REL_ Gateway SG_ 2600468529 NM_ELV_CBV_AWB 2000;
BA_REL_ "GenSigTimeoutTime" BU_SG_REL_ AAG SG_ 2600468529 NM_ELV_CBV_CRI 2000;
BA_REL_ "GenSigTimeoutTime" BU_SG_REL_ BCM1 SG_ 2600468529 NM_ELV_CBV_CRI 2000;
BA_REL_ "GenSigTimeoutTime" BU_SG_REL_ BCM2 SG_ 2600468529 NM_ELV_CBV_CRI 2000;
BA_REL_ "GenSigTimeoutTime" BU_SG_REL_ ELV SG_ 2600468529 NM_ELV_CBV_CRI 2000;
BA_REL_ "GenSigTimeoutTime" BU_SG_REL_ Gateway SG_ 2600468529 NM_ELV_CBV_CRI 2000;
BA_REL_ "GenSigTimeoutTime" BU_SG_REL_ HDSG SG_ 2600468529 NM_ELV_CBV_CRI 2000;
BA_REL_ "GenSigTimeoutTime" BU_SG_REL_ IEZS SG_ 2600468529 NM_ELV_CBV_CRI 2000;
BA_REL_ "GenSigTimeoutTime" BU_SG_REL_ MFG SG_ 2600468529 NM_ELV_CBV_CRI 2000;
BA_REL_ "GenSigTimeoutTime" BU_SG_REL_ MSBBR SG_ 2600468529 NM_ELV_CBV_CRI 2000;
BA_REL_ "GenSigTimeoutTime" BU_SG_REL_ SAD SG_ 2600468529 NM_ELV_CBV_CRI 2000;
BA_REL_ "GenSigTimeoutTime" BU_SG_REL_ SAD2 SG_ 2600468529 NM_ELV_CBV_CRI 2000;
BA_REL_ "GenSigTimeoutTime" BU_SG_REL_ SitzMem_BFS SG_ 2600468529 NM_ELV_CBV_CRI 2000;
BA_REL_ "GenSigTimeoutTime" BU_SG_REL_ SitzMem_FS SG_ 2600468529 NM_ELV_CBV_CRI 2000;
BA_REL_ "GenSigTimeoutTime" BU_SG_REL_ SitzMem_HBFS SG_ 2600468529 NM_ELV_CBV_CRI 2000;
BA_REL_ "GenSigTimeoutTime" BU_SG_REL_ SitzMem_HFS SG_ 2600468529 NM_ELV_CBV_CRI 2000;
BA_REL_ "GenSigTimeoutTime" BU_SG_REL_ SitzMem_SR3 SG_ 2600468529 NM_ELV_CBV_CRI 2000;
BA_REL_ "GenSigTimeoutTime" BU_SG_REL_ SpoilerSG SG_ 2600468529 NM_ELV_CBV_CRI 2000;
BA_REL_ "GenSigTimeoutTime" BU_SG_REL_ TSG_BFS SG_ 2600468529 NM_ELV_CBV_CRI 2000;
BA_REL_ "GenSigTimeoutTime" BU_SG_REL_ TSG_FS SG_ 2600468529 NM_ELV_CBV_CRI 2000;
BA_REL_ "GenSigTimeoutTime" BU_SG_REL_ VSG SG_ 2600468529 NM_ELV_CBV_CRI 2000;
BA_REL_ "GenSigTimeoutTime" BU_SG_REL_ VTS SG_ 2600468529 NM_ELV_CBV_CRI 2000;
BA_REL_ "GenSigTimeoutTime" BU_SG_REL_ Gateway SG_ 2600468529 NM_ELV_Car_Wakeup 2000;
BA_REL_ "GenSigTimeoutTime" BU_SG_REL_ AAG SG_ 2600468529 NM_ELV_CAB 2000;
BA_REL_ "GenSigTimeoutTime" BU_SG_REL_ BCM1 SG_ 2600468529 NM_ELV_CAB 2000;
BA_REL_ "GenSigTimeoutTime" BU_SG_REL_ BCM2 SG_ 2600468529 NM_ELV_CAB 2000;
BA_REL_ "GenSigTimeoutTime" BU_SG_REL_ ELV SG_ 2600468529 NM_ELV_CAB 2000;
BA_REL_ "GenSigTimeoutTime" BU_SG_REL_ Gateway SG_ 2600468529 NM_ELV_CAB 2000;
BA_REL_ "GenSigTimeoutTime" BU_SG_REL_ HDSG SG_ 2600468529 NM_ELV_CAB 2000;
BA_REL_ "GenSigTimeoutTime" BU_SG_REL_ IEZS SG_ 2600468529 NM_ELV_CAB 2000;
BA_REL_ "GenSigTimeoutTime" BU_SG_REL_ MFG SG_ 2600468529 NM_ELV_CAB 2000;
BA_REL_ "GenSigTimeoutTime" BU_SG_REL_ MSBBR SG_ 2600468529 NM_ELV_CAB 2000;
BA_REL_ "GenSigTimeoutTime" BU_SG_REL_ SAD SG_ 2600468529 NM_ELV_CAB 2000;
BA_REL_ "GenSigTimeoutTime" BU_SG_REL_ SAD2 SG_ 2600468529 NM_ELV_CAB 2000;
BA_REL_ "GenSigTimeoutTime" BU_SG_REL_ SitzMem_BFS SG_ 2600468529 NM_ELV_CAB 2000;
BA_REL_ "GenSigTimeoutTime" BU_SG_REL_ SitzMem_FS SG_ 2600468529 NM_ELV_CAB 2000;
BA_REL_ "GenSigTimeoutTime" BU_SG_REL_ SitzMem_HBFS SG_ 2600468529 NM_ELV_CAB 2000;
BA_REL_ "GenSigTimeoutTime" BU_SG_REL_ SitzMem_HFS SG_ 2600468529 NM_ELV_CAB 2000;
BA_REL_ "GenSigTimeoutTime" BU_SG_REL_ SitzMem_SR3 SG_ 2600468529 NM_ELV_CAB 2000;
BA_REL_ "GenSigTimeoutTime" BU_SG_REL_ SpoilerSG SG_ 2600468529 NM_ELV_CAB 2000;
BA_REL_ "GenSigTimeoutTime" BU_SG_REL_ TSG_BFS SG_ 2600468529 NM_ELV_CAB 2000;
BA_REL_ "GenSigTimeoutTime" BU_SG_REL_ TSG_FS SG_ 2600468529 NM_ELV_CAB 2000;
BA_REL_ "GenSigTimeoutTime" BU_SG_REL_ VSG SG_ 2600468529 NM_ELV_CAB 2000;
BA_REL_ "GenSigTimeoutTime" BU_SG_REL_ VTS SG_ 2600468529 NM_ELV_CAB 2000;
BA_REL_ "GenSigTimeoutTime" BU_SG_REL_ AAG SG_ 2600468496 NM_Gateway_SNI 2000;
BA_REL_ "GenSigTimeoutTime" BU_SG_REL_ BCM1 SG_ 2600468496 NM_Gateway_SNI 2000;
BA_REL_ "GenSigTimeoutTime" BU_SG_REL_ BCM2 SG_ 2600468496 NM_Gateway_SNI 2000;
BA_REL_ "GenSigTimeoutTime" BU_SG_REL_ ELV SG_ 2600468496 NM_Gateway_SNI 2000;
BA_REL_ "GenSigTimeoutTime" BU_SG_REL_ Gateway SG_ 2600468496 NM_Gateway_SNI 2000;
BA_REL_ "GenSigTimeoutTime" BU_SG_REL_ HDSG SG_ 2600468496 NM_Gateway_SNI 2000;
BA_REL_ "GenSigTimeoutTime" BU_SG_REL_ IEZS SG_ 2600468496 NM_Gateway_SNI 2000;
BA_REL_ "GenSigTimeoutTime" BU_SG_REL_ MFG SG_ 2600468496 NM_Gateway_SNI 2000;
BA_REL_ "GenSigTimeoutTime" BU_SG_REL_ MSBBR SG_ 2600468496 NM_Gateway_SNI 2000;
BA_REL_ "GenSigTimeoutTime" BU_SG_REL_ SAD SG_ 2600468496 NM_Gateway_SNI 2000;
BA_REL_ "GenSigTimeoutTime" BU_SG_REL_ SAD2 SG_ 2600468496 NM_Gateway_SNI 2000;
BA_REL_ "GenSigTimeoutTime" BU_SG_REL_ SitzMem_BFS SG_ 2600468496 NM_Gateway_SNI 2000;
BA_REL_ "GenSigTimeoutTime" BU_SG_REL_ SitzMem_FS SG_ 2600468496 NM_Gateway_SNI 2000;
BA_REL_ "GenSigTimeoutTime" BU_SG_REL_ SitzMem_HBFS SG_ 2600468496 NM_Gateway_SNI 2000;
BA_REL_ "GenSigTimeoutTime" BU_SG_REL_ SitzMem_HFS SG_ 2600468496 NM_Gateway_SNI 2000;
BA_REL_ "GenSigTimeoutTime" BU_SG_REL_ SitzMem_SR3 SG_ 2600468496 NM_Gateway_SNI 2000;
BA_REL_ "GenSigTimeoutTime" BU_SG_REL_ SpoilerSG SG_ 2600468496 NM_Gateway_SNI 2000;
BA_REL_ "GenSigTimeoutTime" BU_SG_REL_ TSG_BFS SG_ 2600468496 NM_Gateway_SNI 2000;
BA_REL_ "GenSigTimeoutTime" BU_SG_REL_ TSG_FS SG_ 2600468496 NM_Gateway_SNI 2000;
BA_REL_ "GenSigTimeoutTime" BU_SG_REL_ VSG SG_ 2600468496 NM_Gateway_SNI 2000;
BA_REL_ "GenSigTimeoutTime" BU_SG_REL_ VTS SG_ 2600468496 NM_Gateway_SNI 2000;
BA_REL_ "GenSigTimeoutTime" BU_SG_REL_ AAG SG_ 2600468496 NM_Gateway_CBV_CRI 2000;
BA_REL_ "GenSigTimeoutTime" BU_SG_REL_ BCM1 SG_ 2600468496 NM_Gateway_CBV_CRI 2000;
BA_REL_ "GenSigTimeoutTime" BU_SG_REL_ BCM2 SG_ 2600468496 NM_Gateway_CBV_CRI 2000;
BA_REL_ "GenSigTimeoutTime" BU_SG_REL_ ELV SG_ 2600468496 NM_Gateway_CBV_CRI 2000;
BA_REL_ "GenSigTimeoutTime" BU_SG_REL_ Gateway SG_ 2600468496 NM_Gateway_CBV_CRI 2000;
BA_REL_ "GenSigTimeoutTime" BU_SG_REL_ HDSG SG_ 2600468496 NM_Gateway_CBV_CRI 2000;
BA_REL_ "GenSigTimeoutTime" BU_SG_REL_ IEZS SG_ 2600468496 NM_Gateway_CBV_CRI 2000;
BA_REL_ "GenSigTimeoutTime" BU_SG_REL_ MFG SG_ 2600468496 NM_Gateway_CBV_CRI 2000;
BA_REL_ "GenSigTimeoutTime" BU_SG_REL_ MSBBR SG_ 2600468496 NM_Gateway_CBV_CRI 2000;
BA_REL_ "GenSigTimeoutTime" BU_SG_REL_ SAD SG_ 2600468496 NM_Gateway_CBV_CRI 2000;
BA_REL_ "GenSigTimeoutTime" BU_SG_REL_ SAD2 SG_ 2600468496 NM_Gateway_CBV_CRI 2000;
BA_REL_ "GenSigTimeoutTime" BU_SG_REL_ SitzMem_BFS SG_ 2600468496 NM_Gateway_CBV_CRI 2000;
BA_REL_ "GenSigTimeoutTime" BU_SG_REL_ SitzMem_FS SG_ 2600468496 NM_Gateway_CBV_CRI 2000;
BA_REL_ "GenSigTimeoutTime" BU_SG_REL_ SitzMem_HBFS SG_ 2600468496 NM_Gateway_CBV_CRI 2000;
BA_REL_ "GenSigTimeoutTime" BU_SG_REL_ SitzMem_HFS SG_ 2600468496 NM_Gateway_CBV_CRI 2000;
BA_REL_ "GenSigTimeoutTime" BU_SG_REL_ SitzMem_SR3 SG_ 2600468496 NM_Gateway_CBV_CRI 2000;
BA_REL_ "GenSigTimeoutTime" BU_SG_REL_ SpoilerSG SG_ 2600468496 NM_Gateway_CBV_CRI 2000;
BA_REL_ "GenSigTimeoutTime" BU_SG_REL_ TSG_BFS SG_ 2600468496 NM_Gateway_CBV_CRI 2000;
BA_REL_ "GenSigTimeoutTime" BU_SG_REL_ TSG_FS SG_ 2600468496 NM_Gateway_CBV_CRI 2000;
BA_REL_ "GenSigTimeoutTime" BU_SG_REL_ VSG SG_ 2600468496 NM_Gateway_CBV_CRI 2000;
BA_REL_ "GenSigTimeoutTime" BU_SG_REL_ VTS SG_ 2600468496 NM_Gateway_CBV_CRI 2000;
BA_REL_ "GenSigTimeoutTime" BU_SG_REL_ AAG SG_ 2600468496 NM_Gateway_CAB 2000;
BA_REL_ "GenSigTimeoutTime" BU_SG_REL_ BCM1 SG_ 2600468496 NM_Gateway_CAB 2000;
BA_REL_ "GenSigTimeoutTime" BU_SG_REL_ BCM2 SG_ 2600468496 NM_Gateway_CAB 2000;
BA_REL_ "GenSigTimeoutTime" BU_SG_REL_ ELV SG_ 2600468496 NM_Gateway_CAB 2000;
BA_REL_ "GenSigTimeoutTime" BU_SG_REL_ Gateway SG_ 2600468496 NM_Gateway_CAB 2000;
BA_REL_ "GenSigTimeoutTime" BU_SG_REL_ HDSG SG_ 2600468496 NM_Gateway_CAB 2000;
BA_REL_ "GenSigTimeoutTime" BU_SG_REL_ IEZS SG_ 2600468496 NM_Gateway_CAB 2000;
BA_REL_ "GenSigTimeoutTime" BU_SG_REL_ MFG SG_ 2600468496 NM_Gateway_CAB 2000;
BA_REL_ "GenSigTimeoutTime" BU_SG_REL_ MSBBR SG_ 2600468496 NM_Gateway_CAB 2000;
BA_REL_ "GenSigTimeoutTime" BU_SG_REL_ SAD SG_ 2600468496 NM_Gateway_CAB 2000;
BA_REL_ "GenSigTimeoutTime" BU_SG_REL_ SAD2 SG_ 2600468496 NM_Gateway_CAB 2000;
BA_REL_ "GenSigTimeoutTime" BU_SG_REL_ SitzMem_BFS SG_ 2600468496 NM_Gateway_CAB 2000;
BA_REL_ "GenSigTimeoutTime" BU_SG_REL_ SitzMem_FS SG_ 2600468496 NM_Gateway_CAB 2000;
BA_REL_ "GenSigTimeoutTime" BU_SG_REL_ SitzMem_HBFS SG_ 2600468496 NM_Gateway_CAB 2000;
BA_REL_ "GenSigTimeoutTime" BU_SG_REL_ SitzMem_HFS SG_ 2600468496 NM_Gateway_CAB 2000;
BA_REL_ "GenSigTimeoutTime" BU_SG_REL_ SitzMem_SR3 SG_ 2600468496 NM_Gateway_CAB 2000;
BA_REL_ "GenSigTimeoutTime" BU_SG_REL_ SpoilerSG SG_ 2600468496 NM_Gateway_CAB 2000;
BA_REL_ "GenSigTimeoutTime" BU_SG_REL_ TSG_BFS SG_ 2600468496 NM_Gateway_CAB 2000;
BA_REL_ "GenSigTimeoutTime" BU_SG_REL_ TSG_FS SG_ 2600468496 NM_Gateway_CAB 2000;
BA_REL_ "GenSigTimeoutTime" BU_SG_REL_ VSG SG_ 2600468496 NM_Gateway_CAB 2000;
BA_REL_ "GenSigTimeoutTime" BU_SG_REL_ VTS SG_ 2600468496 NM_Gateway_CAB 2000;
BA_REL_ "GenSigTimeoutTime" BU_SG_REL_ AAG SG_ 2600468515 NM_HDSG_SNI 2000;
BA_REL_ "GenSigTimeoutTime" BU_SG_REL_ BCM1 SG_ 2600468515 NM_HDSG_SNI 2000;
BA_REL_ "GenSigTimeoutTime" BU_SG_REL_ BCM2 SG_ 2600468515 NM_HDSG_SNI 2000;
BA_REL_ "GenSigTimeoutTime" BU_SG_REL_ ELV SG_ 2600468515 NM_HDSG_SNI 2000;
BA_REL_ "GenSigTimeoutTime" BU_SG_REL_ Gateway SG_ 2600468515 NM_HDSG_SNI 2000;
BA_REL_ "GenSigTimeoutTime" BU_SG_REL_ HDSG SG_ 2600468515 NM_HDSG_SNI 2000;
BA_REL_ "GenSigTimeoutTime" BU_SG_REL_ IEZS SG_ 2600468515 NM_HDSG_SNI 2000;
BA_REL_ "GenSigTimeoutTime" BU_SG_REL_ MFG SG_ 2600468515 NM_HDSG_SNI 2000;
BA_REL_ "GenSigTimeoutTime" BU_SG_REL_ MSBBR SG_ 2600468515 NM_HDSG_SNI 2000;
BA_REL_ "GenSigTimeoutTime" BU_SG_REL_ SAD SG_ 2600468515 NM_HDSG_SNI 2000;
BA_REL_ "GenSigTimeoutTime" BU_SG_REL_ SAD2 SG_ 2600468515 NM_HDSG_SNI 2000;
BA_REL_ "GenSigTimeoutTime" BU_SG_REL_ SitzMem_BFS SG_ 2600468515 NM_HDSG_SNI 2000;
BA_REL_ "GenSigTimeoutTime" BU_SG_REL_ SitzMem_FS SG_ 2600468515 NM_HDSG_SNI 2000;
BA_REL_ "GenSigTimeoutTime" BU_SG_REL_ SitzMem_HBFS SG_ 2600468515 NM_HDSG_SNI 2000;
BA_REL_ "GenSigTimeoutTime" BU_SG_REL_ SitzMem_HFS SG_ 2600468515 NM_HDSG_SNI 2000;
BA_REL_ "GenSigTimeoutTime" BU_SG_REL_ SitzMem_SR3 SG_ 2600468515 NM_HDSG_SNI 2000;
BA_REL_ "GenSigTimeoutTime" BU_SG_REL_ SpoilerSG SG_ 2600468515 NM_HDSG_SNI 2000;
BA_REL_ "GenSigTimeoutTime" BU_SG_REL_ TSG_BFS SG_ 2600468515 NM_HDSG_SNI 2000;
BA_REL_ "GenSigTimeoutTime" BU_SG_REL_ TSG_FS SG_ 2600468515 NM_HDSG_SNI 2000;
BA_REL_ "GenSigTimeoutTime" BU_SG_REL_ VSG SG_ 2600468515 NM_HDSG_SNI 2000;
BA_REL_ "GenSigTimeoutTime" BU_SG_REL_ VTS SG_ 2600468515 NM_HDSG_SNI 2000;
BA_REL_ "GenSigTimeoutTime" BU_SG_REL_ Gateway SG_ 2600468515 NM_HDSG_CBV_AWB 2000;
BA_REL_ "GenSigTimeoutTime" BU_SG_REL_ AAG SG_ 2600468515 NM_HDSG_CBV_CRI 2000;
BA_REL_ "GenSigTimeoutTime" BU_SG_REL_ BCM1 SG_ 2600468515 NM_HDSG_CBV_CRI 2000;
BA_REL_ "GenSigTimeoutTime" BU_SG_REL_ BCM2 SG_ 2600468515 NM_HDSG_CBV_CRI 2000;
BA_REL_ "GenSigTimeoutTime" BU_SG_REL_ ELV SG_ 2600468515 NM_HDSG_CBV_CRI 2000;
BA_REL_ "GenSigTimeoutTime" BU_SG_REL_ Gateway SG_ 2600468515 NM_HDSG_CBV_CRI 2000;
BA_REL_ "GenSigTimeoutTime" BU_SG_REL_ HDSG SG_ 2600468515 NM_HDSG_CBV_CRI 2000;
BA_REL_ "GenSigTimeoutTime" BU_SG_REL_ IEZS SG_ 2600468515 NM_HDSG_CBV_CRI 2000;
BA_REL_ "GenSigTimeoutTime" BU_SG_REL_ MFG SG_ 2600468515 NM_HDSG_CBV_CRI 2000;
BA_REL_ "GenSigTimeoutTime" BU_SG_REL_ MSBBR SG_ 2600468515 NM_HDSG_CBV_CRI 2000;
BA_REL_ "GenSigTimeoutTime" BU_SG_REL_ SAD SG_ 2600468515 NM_HDSG_CBV_CRI 2000;
BA_REL_ "GenSigTimeoutTime" BU_SG_REL_ SAD2 SG_ 2600468515 NM_HDSG_CBV_CRI 2000;
BA_REL_ "GenSigTimeoutTime" BU_SG_REL_ SitzMem_BFS SG_ 2600468515 NM_HDSG_CBV_CRI 2000;
BA_REL_ "GenSigTimeoutTime" BU_SG_REL_ SitzMem_FS SG_ 2600468515 NM_HDSG_CBV_CRI 2000;
BA_REL_ "GenSigTimeoutTime" BU_SG_REL_ SitzMem_HBFS SG_ 2600468515 NM_HDSG_CBV_CRI 2000;
BA_REL_ "GenSigTimeoutTime" BU_SG_REL_ SitzMem_HFS SG_ 2600468515 NM_HDSG_CBV_CRI 2000;
BA_REL_ "GenSigTimeoutTime" BU_SG_REL_ SitzMem_SR3 SG_ 2600468515 NM_HDSG_CBV_CRI 2000;
BA_REL_ "GenSigTimeoutTime" BU_SG_REL_ SpoilerSG SG_ 2600468515 NM_HDSG_CBV_CRI 2000;
BA_REL_ "GenSigTimeoutTime" BU_SG_REL_ TSG_BFS SG_ 2600468515 NM_HDSG_CBV_CRI 2000;
BA_REL_ "GenSigTimeoutTime" BU_SG_REL_ TSG_FS SG_ 2600468515 NM_HDSG_CBV_CRI 2000;
BA_REL_ "GenSigTimeoutTime" BU_SG_REL_ VSG SG_ 2600468515 NM_HDSG_CBV_CRI 2000;
BA_REL_ "GenSigTimeoutTime" BU_SG_REL_ VTS SG_ 2600468515 NM_HDSG_CBV_CRI 2000;
BA_REL_ "GenSigTimeoutTime" BU_SG_REL_ Gateway SG_ 2600468515 NM_HDSG_Car_Wakeup 2000;
BA_REL_ "GenSigTimeoutTime" BU_SG_REL_ AAG SG_ 2600468515 NM_HDSG_CAB 2000;
BA_REL_ "GenSigTimeoutTime" BU_SG_REL_ BCM1 SG_ 2600468515 NM_HDSG_CAB 2000;
BA_REL_ "GenSigTimeoutTime" BU_SG_REL_ BCM2 SG_ 2600468515 NM_HDSG_CAB 2000;
BA_REL_ "GenSigTimeoutTime" BU_SG_REL_ ELV SG_ 2600468515 NM_HDSG_CAB 2000;
BA_REL_ "GenSigTimeoutTime" BU_SG_REL_ Gateway SG_ 2600468515 NM_HDSG_CAB 2000;
BA_REL_ "GenSigTimeoutTime" BU_SG_REL_ HDSG SG_ 2600468515 NM_HDSG_CAB 2000;
BA_REL_ "GenSigTimeoutTime" BU_SG_REL_ IEZS SG_ 2600468515 NM_HDSG_CAB 2000;
BA_REL_ "GenSigTimeoutTime" BU_SG_REL_ MFG SG_ 2600468515 NM_HDSG_CAB 2000;
BA_REL_ "GenSigTimeoutTime" BU_SG_REL_ MSBBR SG_ 2600468515 NM_HDSG_CAB 2000;
BA_REL_ "GenSigTimeoutTime" BU_SG_REL_ SAD SG_ 2600468515 NM_HDSG_CAB 2000;
BA_REL_ "GenSigTimeoutTime" BU_SG_REL_ SAD2 SG_ 2600468515 NM_HDSG_CAB 2000;
BA_REL_ "GenSigTimeoutTime" BU_SG_REL_ SitzMem_BFS SG_ 2600468515 NM_HDSG_CAB 2000;
BA_REL_ "GenSigTimeoutTime" BU_SG_REL_ SitzMem_FS SG_ 2600468515 NM_HDSG_CAB 2000;
BA_REL_ "GenSigTimeoutTime" BU_SG_REL_ SitzMem_HBFS SG_ 2600468515 NM_HDSG_CAB 2000;
BA_REL_ "GenSigTimeoutTime" BU_SG_REL_ SitzMem_HFS SG_ 2600468515 NM_HDSG_CAB 2000;
BA_REL_ "GenSigTimeoutTime" BU_SG_REL_ SitzMem_SR3 SG_ 2600468515 NM_HDSG_CAB 2000;
BA_REL_ "GenSigTimeoutTime" BU_SG_REL_ SpoilerSG SG_ 2600468515 NM_HDSG_CAB 2000;
BA_REL_ "GenSigTimeoutTime" BU_SG_REL_ TSG_BFS SG_ 2600468515 NM_HDSG_CAB 2000;
BA_REL_ "GenSigTimeoutTime" BU_SG_REL_ TSG_FS SG_ 2600468515 NM_HDSG_CAB 2000;
BA_REL_ "GenSigTimeoutTime" BU_SG_REL_ VSG SG_ 2600468515 NM_HDSG_CAB 2000;
BA_REL_ "GenSigTimeoutTime" BU_SG_REL_ VTS SG_ 2600468515 NM_HDSG_CAB 2000;
BA_REL_ "GenSigTimeoutTime" BU_SG_REL_ AAG SG_ 2600468530 NM_Kessy_SNI 2000;
BA_REL_ "GenSigTimeoutTime" BU_SG_REL_ BCM1 SG_ 2600468530 NM_Kessy_SNI 2000;
BA_REL_ "GenSigTimeoutTime" BU_SG_REL_ BCM2 SG_ 2600468530 NM_Kessy_SNI 2000;
BA_REL_ "GenSigTimeoutTime" BU_SG_REL_ ELV SG_ 2600468530 NM_Kessy_SNI 2000;
BA_REL_ "GenSigTimeoutTime" BU_SG_REL_ Gateway SG_ 2600468530 NM_Kessy_SNI 2000;
BA_REL_ "GenSigTimeoutTime" BU_SG_REL_ HDSG SG_ 2600468530 NM_Kessy_SNI 2000;
BA_REL_ "GenSigTimeoutTime" BU_SG_REL_ IEZS SG_ 2600468530 NM_Kessy_SNI 2000;
BA_REL_ "GenSigTimeoutTime" BU_SG_REL_ MFG SG_ 2600468530 NM_Kessy_SNI 2000;
BA_REL_ "GenSigTimeoutTime" BU_SG_REL_ MSBBR SG_ 2600468530 NM_Kessy_SNI 2000;
BA_REL_ "GenSigTimeoutTime" BU_SG_REL_ SAD SG_ 2600468530 NM_Kessy_SNI 2000;
BA_REL_ "GenSigTimeoutTime" BU_SG_REL_ SAD2 SG_ 2600468530 NM_Kessy_SNI 2000;
BA_REL_ "GenSigTimeoutTime" BU_SG_REL_ SitzMem_BFS SG_ 2600468530 NM_Kessy_SNI 2000;
BA_REL_ "GenSigTimeoutTime" BU_SG_REL_ SitzMem_FS SG_ 2600468530 NM_Kessy_SNI 2000;
BA_REL_ "GenSigTimeoutTime" BU_SG_REL_ SitzMem_HBFS SG_ 2600468530 NM_Kessy_SNI 2000;
BA_REL_ "GenSigTimeoutTime" BU_SG_REL_ SitzMem_HFS SG_ 2600468530 NM_Kessy_SNI 2000;
BA_REL_ "GenSigTimeoutTime" BU_SG_REL_ SitzMem_SR3 SG_ 2600468530 NM_Kessy_SNI 2000;
BA_REL_ "GenSigTimeoutTime" BU_SG_REL_ SpoilerSG SG_ 2600468530 NM_Kessy_SNI 2000;
BA_REL_ "GenSigTimeoutTime" BU_SG_REL_ TSG_BFS SG_ 2600468530 NM_Kessy_SNI 2000;
BA_REL_ "GenSigTimeoutTime" BU_SG_REL_ TSG_FS SG_ 2600468530 NM_Kessy_SNI 2000;
BA_REL_ "GenSigTimeoutTime" BU_SG_REL_ VSG SG_ 2600468530 NM_Kessy_SNI 2000;
BA_REL_ "GenSigTimeoutTime" BU_SG_REL_ VTS SG_ 2600468530 NM_Kessy_SNI 2000;
BA_REL_ "GenSigTimeoutTime" BU_SG_REL_ Gateway SG_ 2600468530 NM_Kessy_CBV_AWB 2000;
BA_REL_ "GenSigTimeoutTime" BU_SG_REL_ AAG SG_ 2600468530 NM_Kessy_CBV_CRI 2000;
BA_REL_ "GenSigTimeoutTime" BU_SG_REL_ BCM1 SG_ 2600468530 NM_Kessy_CBV_CRI 2000;
BA_REL_ "GenSigTimeoutTime" BU_SG_REL_ BCM2 SG_ 2600468530 NM_Kessy_CBV_CRI 2000;
BA_REL_ "GenSigTimeoutTime" BU_SG_REL_ ELV SG_ 2600468530 NM_Kessy_CBV_CRI 2000;
BA_REL_ "GenSigTimeoutTime" BU_SG_REL_ Gateway SG_ 2600468530 NM_Kessy_CBV_CRI 2000;
BA_REL_ "GenSigTimeoutTime" BU_SG_REL_ HDSG SG_ 2600468530 NM_Kessy_CBV_CRI 2000;
BA_REL_ "GenSigTimeoutTime" BU_SG_REL_ IEZS SG_ 2600468530 NM_Kessy_CBV_CRI 2000;
BA_REL_ "GenSigTimeoutTime" BU_SG_REL_ MFG SG_ 2600468530 NM_Kessy_CBV_CRI 2000;
BA_REL_ "GenSigTimeoutTime" BU_SG_REL_ MSBBR SG_ 2600468530 NM_Kessy_CBV_CRI 2000;
BA_REL_ "GenSigTimeoutTime" BU_SG_REL_ SAD SG_ 2600468530 NM_Kessy_CBV_CRI 2000;
BA_REL_ "GenSigTimeoutTime" BU_SG_REL_ SAD2 SG_ 2600468530 NM_Kessy_CBV_CRI 2000;
BA_REL_ "GenSigTimeoutTime" BU_SG_REL_ SitzMem_BFS SG_ 2600468530 NM_Kessy_CBV_CRI 2000;
BA_REL_ "GenSigTimeoutTime" BU_SG_REL_ SitzMem_FS SG_ 2600468530 NM_Kessy_CBV_CRI 2000;
BA_REL_ "GenSigTimeoutTime" BU_SG_REL_ SitzMem_HBFS SG_ 2600468530 NM_Kessy_CBV_CRI 2000;
BA_REL_ "GenSigTimeoutTime" BU_SG_REL_ SitzMem_HFS SG_ 2600468530 NM_Kessy_CBV_CRI 2000;
BA_REL_ "GenSigTimeoutTime" BU_SG_REL_ SitzMem_SR3 SG_ 2600468530 NM_Kessy_CBV_CRI 2000;
BA_REL_ "GenSigTimeoutTime" BU_SG_REL_ SpoilerSG SG_ 2600468530 NM_Kessy_CBV_CRI 2000;
BA_REL_ "GenSigTimeoutTime" BU_SG_REL_ TSG_BFS SG_ 2600468530 NM_Kessy_CBV_CRI 2000;
BA_REL_ "GenSigTimeoutTime" BU_SG_REL_ TSG_FS SG_ 2600468530 NM_Kessy_CBV_CRI 2000;
BA_REL_ "GenSigTimeoutTime" BU_SG_REL_ VSG SG_ 2600468530 NM_Kessy_CBV_CRI 2000;
BA_REL_ "GenSigTimeoutTime" BU_SG_REL_ VTS SG_ 2600468530 NM_Kessy_CBV_CRI 2000;
BA_REL_ "GenSigTimeoutTime" BU_SG_REL_ Gateway SG_ 2600468530 NM_Kessy_Car_Wakeup 2000;
BA_REL_ "GenSigTimeoutTime" BU_SG_REL_ AAG SG_ 2600468530 NM_Kessy_CAB 2000;
BA_REL_ "GenSigTimeoutTime" BU_SG_REL_ BCM1 SG_ 2600468530 NM_Kessy_CAB 2000;
BA_REL_ "GenSigTimeoutTime" BU_SG_REL_ BCM2 SG_ 2600468530 NM_Kessy_CAB 2000;
BA_REL_ "GenSigTimeoutTime" BU_SG_REL_ ELV SG_ 2600468530 NM_Kessy_CAB 2000;
BA_REL_ "GenSigTimeoutTime" BU_SG_REL_ Gateway SG_ 2600468530 NM_Kessy_CAB 2000;
BA_REL_ "GenSigTimeoutTime" BU_SG_REL_ HDSG SG_ 2600468530 NM_Kessy_CAB 2000;
BA_REL_ "GenSigTimeoutTime" BU_SG_REL_ IEZS SG_ 2600468530 NM_Kessy_CAB 2000;
BA_REL_ "GenSigTimeoutTime" BU_SG_REL_ MFG SG_ 2600468530 NM_Kessy_CAB 2000;
BA_REL_ "GenSigTimeoutTime" BU_SG_REL_ MSBBR SG_ 2600468530 NM_Kessy_CAB 2000;
BA_REL_ "GenSigTimeoutTime" BU_SG_REL_ SAD SG_ 2600468530 NM_Kessy_CAB 2000;
BA_REL_ "GenSigTimeoutTime" BU_SG_REL_ SAD2 SG_ 2600468530 NM_Kessy_CAB 2000;
BA_REL_ "GenSigTimeoutTime" BU_SG_REL_ SitzMem_BFS SG_ 2600468530 NM_Kessy_CAB 2000;
BA_REL_ "GenSigTimeoutTime" BU_SG_REL_ SitzMem_FS SG_ 2600468530 NM_Kessy_CAB 2000;
BA_REL_ "GenSigTimeoutTime" BU_SG_REL_ SitzMem_HBFS SG_ 2600468530 NM_Kessy_CAB 2000;
BA_REL_ "GenSigTimeoutTime" BU_SG_REL_ SitzMem_HFS SG_ 2600468530 NM_Kessy_CAB 2000;
BA_REL_ "GenSigTimeoutTime" BU_SG_REL_ SitzMem_SR3 SG_ 2600468530 NM_Kessy_CAB 2000;
BA_REL_ "GenSigTimeoutTime" BU_SG_REL_ SpoilerSG SG_ 2600468530 NM_Kessy_CAB 2000;
BA_REL_ "GenSigTimeoutTime" BU_SG_REL_ TSG_BFS SG_ 2600468530 NM_Kessy_CAB 2000;
BA_REL_ "GenSigTimeoutTime" BU_SG_REL_ TSG_FS SG_ 2600468530 NM_Kessy_CAB 2000;
BA_REL_ "GenSigTimeoutTime" BU_SG_REL_ VSG SG_ 2600468530 NM_Kessy_CAB 2000;
BA_REL_ "GenSigTimeoutTime" BU_SG_REL_ VTS SG_ 2600468530 NM_Kessy_CAB 2000;
BA_REL_ "GenSigTimeoutTime" BU_SG_REL_ AAG SG_ 2600468524 NM_MFG_SNI 2000;
BA_REL_ "GenSigTimeoutTime" BU_SG_REL_ BCM1 SG_ 2600468524 NM_MFG_SNI 2000;
BA_REL_ "GenSigTimeoutTime" BU_SG_REL_ BCM2 SG_ 2600468524 NM_MFG_SNI 2000;
BA_REL_ "GenSigTimeoutTime" BU_SG_REL_ ELV SG_ 2600468524 NM_MFG_SNI 2000;
BA_REL_ "GenSigTimeoutTime" BU_SG_REL_ Gateway SG_ 2600468524 NM_MFG_SNI 2000;
BA_REL_ "GenSigTimeoutTime" BU_SG_REL_ HDSG SG_ 2600468524 NM_MFG_SNI 2000;
BA_REL_ "GenSigTimeoutTime" BU_SG_REL_ IEZS SG_ 2600468524 NM_MFG_SNI 2000;
BA_REL_ "GenSigTimeoutTime" BU_SG_REL_ MFG SG_ 2600468524 NM_MFG_SNI 2000;
BA_REL_ "GenSigTimeoutTime" BU_SG_REL_ MSBBR SG_ 2600468524 NM_MFG_SNI 2000;
BA_REL_ "GenSigTimeoutTime" BU_SG_REL_ SAD SG_ 2600468524 NM_MFG_SNI 2000;
BA_REL_ "GenSigTimeoutTime" BU_SG_REL_ SAD2 SG_ 2600468524 NM_MFG_SNI 2000;
BA_REL_ "GenSigTimeoutTime" BU_SG_REL_ SitzMem_BFS SG_ 2600468524 NM_MFG_SNI 2000;
BA_REL_ "GenSigTimeoutTime" BU_SG_REL_ SitzMem_FS SG_ 2600468524 NM_MFG_SNI 2000;
BA_REL_ "GenSigTimeoutTime" BU_SG_REL_ SitzMem_HBFS SG_ 2600468524 NM_MFG_SNI 2000;
BA_REL_ "GenSigTimeoutTime" BU_SG_REL_ SitzMem_HFS SG_ 2600468524 NM_MFG_SNI 2000;
BA_REL_ "GenSigTimeoutTime" BU_SG_REL_ SitzMem_SR3 SG_ 2600468524 NM_MFG_SNI 2000;
BA_REL_ "GenSigTimeoutTime" BU_SG_REL_ SpoilerSG SG_ 2600468524 NM_MFG_SNI 2000;
BA_REL_ "GenSigTimeoutTime" BU_SG_REL_ TSG_BFS SG_ 2600468524 NM_MFG_SNI 2000;
BA_REL_ "GenSigTimeoutTime" BU_SG_REL_ TSG_FS SG_ 2600468524 NM_MFG_SNI 2000;
BA_REL_ "GenSigTimeoutTime" BU_SG_REL_ VSG SG_ 2600468524 NM_MFG_SNI 2000;
BA_REL_ "GenSigTimeoutTime" BU_SG_REL_ VTS SG_ 2600468524 NM_MFG_SNI 2000;
BA_REL_ "GenSigTimeoutTime" BU_SG_REL_ Gateway SG_ 2600468524 NM_MFG_CBV_AWB 2000;
BA_REL_ "GenSigTimeoutTime" BU_SG_REL_ AAG SG_ 2600468524 NM_MFG_CBV_CRI 2000;
BA_REL_ "GenSigTimeoutTime" BU_SG_REL_ BCM1 SG_ 2600468524 NM_MFG_CBV_CRI 2000;
BA_REL_ "GenSigTimeoutTime" BU_SG_REL_ BCM2 SG_ 2600468524 NM_MFG_CBV_CRI 2000;
BA_REL_ "GenSigTimeoutTime" BU_SG_REL_ ELV SG_ 2600468524 NM_MFG_CBV_CRI 2000;
BA_REL_ "GenSigTimeoutTime" BU_SG_REL_ Gateway SG_ 2600468524 NM_MFG_CBV_CRI 2000;
BA_REL_ "GenSigTimeoutTime" BU_SG_REL_ HDSG SG_ 2600468524 NM_MFG_CBV_CRI 2000;
BA_REL_ "GenSigTimeoutTime" BU_SG_REL_ IEZS SG_ 2600468524 NM_MFG_CBV_CRI 2000;
BA_REL_ "GenSigTimeoutTime" BU_SG_REL_ MFG SG_ 2600468524 NM_MFG_CBV_CRI 2000;
BA_REL_ "GenSigTimeoutTime" BU_SG_REL_ MSBBR SG_ 2600468524 NM_MFG_CBV_CRI 2000;
BA_REL_ "GenSigTimeoutTime" BU_SG_REL_ SAD SG_ 2600468524 NM_MFG_CBV_CRI 2000;
BA_REL_ "GenSigTimeoutTime" BU_SG_REL_ SAD2 SG_ 2600468524 NM_MFG_CBV_CRI 2000;
BA_REL_ "GenSigTimeoutTime" BU_SG_REL_ SitzMem_BFS SG_ 2600468524 NM_MFG_CBV_CRI 2000;
BA_REL_ "GenSigTimeoutTime" BU_SG_REL_ SitzMem_FS SG_ 2600468524 NM_MFG_CBV_CRI 2000;
BA_REL_ "GenSigTimeoutTime" BU_SG_REL_ SitzMem_HBFS SG_ 2600468524 NM_MFG_CBV_CRI 2000;
BA_REL_ "GenSigTimeoutTime" BU_SG_REL_ SitzMem_HFS SG_ 2600468524 NM_MFG_CBV_CRI 2000;
BA_REL_ "GenSigTimeoutTime" BU_SG_REL_ SitzMem_SR3 SG_ 2600468524 NM_MFG_CBV_CRI 2000;
BA_REL_ "GenSigTimeoutTime" BU_SG_REL_ SpoilerSG SG_ 2600468524 NM_MFG_CBV_CRI 2000;
BA_REL_ "GenSigTimeoutTime" BU_SG_REL_ TSG_BFS SG_ 2600468524 NM_MFG_CBV_CRI 2000;
BA_REL_ "GenSigTimeoutTime" BU_SG_REL_ TSG_FS SG_ 2600468524 NM_MFG_CBV_CRI 2000;
BA_REL_ "GenSigTimeoutTime" BU_SG_REL_ VSG SG_ 2600468524 NM_MFG_CBV_CRI 2000;
BA_REL_ "GenSigTimeoutTime" BU_SG_REL_ VTS SG_ 2600468524 NM_MFG_CBV_CRI 2000;
BA_REL_ "GenSigTimeoutTime" BU_SG_REL_ Gateway SG_ 2600468524 NM_MFG_Car_Wakeup 2000;
BA_REL_ "GenSigTimeoutTime" BU_SG_REL_ AAG SG_ 2600468524 NM_MFG_CAB 2000;
BA_REL_ "GenSigTimeoutTime" BU_SG_REL_ BCM1 SG_ 2600468524 NM_MFG_CAB 2000;
BA_REL_ "GenSigTimeoutTime" BU_SG_REL_ BCM2 SG_ 2600468524 NM_MFG_CAB 2000;
BA_REL_ "GenSigTimeoutTime" BU_SG_REL_ ELV SG_ 2600468524 NM_MFG_CAB 2000;
BA_REL_ "GenSigTimeoutTime" BU_SG_REL_ Gateway SG_ 2600468524 NM_MFG_CAB 2000;
BA_REL_ "GenSigTimeoutTime" BU_SG_REL_ HDSG SG_ 2600468524 NM_MFG_CAB 2000;
BA_REL_ "GenSigTimeoutTime" BU_SG_REL_ IEZS SG_ 2600468524 NM_MFG_CAB 2000;
BA_REL_ "GenSigTimeoutTime" BU_SG_REL_ MFG SG_ 2600468524 NM_MFG_CAB 2000;
BA_REL_ "GenSigTimeoutTime" BU_SG_REL_ MSBBR SG_ 2600468524 NM_MFG_CAB 2000;
BA_REL_ "GenSigTimeoutTime" BU_SG_REL_ SAD SG_ 2600468524 NM_MFG_CAB 2000;
BA_REL_ "GenSigTimeoutTime" BU_SG_REL_ SAD2 SG_ 2600468524 NM_MFG_CAB 2000;
BA_REL_ "GenSigTimeoutTime" BU_SG_REL_ SitzMem_BFS SG_ 2600468524 NM_MFG_CAB 2000;
BA_REL_ "GenSigTimeoutTime" BU_SG_REL_ SitzMem_FS SG_ 2600468524 NM_MFG_CAB 2000;
BA_REL_ "GenSigTimeoutTime" BU_SG_REL_ SitzMem_HBFS SG_ 2600468524 NM_MFG_CAB 2000;
BA_REL_ "GenSigTimeoutTime" BU_SG_REL_ SitzMem_HFS SG_ 2600468524 NM_MFG_CAB 2000;
BA_REL_ "GenSigTimeoutTime" BU_SG_REL_ SitzMem_SR3 SG_ 2600468524 NM_MFG_CAB 2000;
BA_REL_ "GenSigTimeoutTime" BU_SG_REL_ SpoilerSG SG_ 2600468524 NM_MFG_CAB 2000;
BA_REL_ "GenSigTimeoutTime" BU_SG_REL_ TSG_BFS SG_ 2600468524 NM_MFG_CAB 2000;
BA_REL_ "GenSigTimeoutTime" BU_SG_REL_ TSG_FS SG_ 2600468524 NM_MFG_CAB 2000;
BA_REL_ "GenSigTimeoutTime" BU_SG_REL_ VSG SG_ 2600468524 NM_MFG_CAB 2000;
BA_REL_ "GenSigTimeoutTime" BU_SG_REL_ VTS SG_ 2600468524 NM_MFG_CAB 2000;
BA_REL_ "GenSigTimeoutTime" BU_SG_REL_ AAG SG_ 2600468612 NM_SAD_SNI 2000;
BA_REL_ "GenSigTimeoutTime" BU_SG_REL_ BCM1 SG_ 2600468612 NM_SAD_SNI 2000;
BA_REL_ "GenSigTimeoutTime" BU_SG_REL_ BCM2 SG_ 2600468612 NM_SAD_SNI 2000;
BA_REL_ "GenSigTimeoutTime" BU_SG_REL_ ELV SG_ 2600468612 NM_SAD_SNI 2000;
BA_REL_ "GenSigTimeoutTime" BU_SG_REL_ Gateway SG_ 2600468612 NM_SAD_SNI 2000;
BA_REL_ "GenSigTimeoutTime" BU_SG_REL_ HDSG SG_ 2600468612 NM_SAD_SNI 2000;
BA_REL_ "GenSigTimeoutTime" BU_SG_REL_ IEZS SG_ 2600468612 NM_SAD_SNI 2000;
BA_REL_ "GenSigTimeoutTime" BU_SG_REL_ MFG SG_ 2600468612 NM_SAD_SNI 2000;
BA_REL_ "GenSigTimeoutTime" BU_SG_REL_ MSBBR SG_ 2600468612 NM_SAD_SNI 2000;
BA_REL_ "GenSigTimeoutTime" BU_SG_REL_ SAD SG_ 2600468612 NM_SAD_SNI 2000;
BA_REL_ "GenSigTimeoutTime" BU_SG_REL_ SAD2 SG_ 2600468612 NM_SAD_SNI 2000;
BA_REL_ "GenSigTimeoutTime" BU_SG_REL_ SitzMem_BFS SG_ 2600468612 NM_SAD_SNI 2000;
BA_REL_ "GenSigTimeoutTime" BU_SG_REL_ SitzMem_FS SG_ 2600468612 NM_SAD_SNI 2000;
BA_REL_ "GenSigTimeoutTime" BU_SG_REL_ SitzMem_HBFS SG_ 2600468612 NM_SAD_SNI 2000;
BA_REL_ "GenSigTimeoutTime" BU_SG_REL_ SitzMem_HFS SG_ 2600468612 NM_SAD_SNI 2000;
BA_REL_ "GenSigTimeoutTime" BU_SG_REL_ SitzMem_SR3 SG_ 2600468612 NM_SAD_SNI 2000;
BA_REL_ "GenSigTimeoutTime" BU_SG_REL_ SpoilerSG SG_ 2600468612 NM_SAD_SNI 2000;
BA_REL_ "GenSigTimeoutTime" BU_SG_REL_ TSG_BFS SG_ 2600468612 NM_SAD_SNI 2000;
BA_REL_ "GenSigTimeoutTime" BU_SG_REL_ TSG_FS SG_ 2600468612 NM_SAD_SNI 2000;
BA_REL_ "GenSigTimeoutTime" BU_SG_REL_ VSG SG_ 2600468612 NM_SAD_SNI 2000;
BA_REL_ "GenSigTimeoutTime" BU_SG_REL_ VTS SG_ 2600468612 NM_SAD_SNI 2000;
BA_REL_ "GenSigTimeoutTime" BU_SG_REL_ Gateway SG_ 2600468612 NM_SAD_CBV_AWB 2000;
BA_REL_ "GenSigTimeoutTime" BU_SG_REL_ AAG SG_ 2600468612 NM_SAD_CBV_CRI 2000;
BA_REL_ "GenSigTimeoutTime" BU_SG_REL_ BCM1 SG_ 2600468612 NM_SAD_CBV_CRI 2000;
BA_REL_ "GenSigTimeoutTime" BU_SG_REL_ BCM2 SG_ 2600468612 NM_SAD_CBV_CRI 2000;
BA_REL_ "GenSigTimeoutTime" BU_SG_REL_ ELV SG_ 2600468612 NM_SAD_CBV_CRI 2000;
BA_REL_ "GenSigTimeoutTime" BU_SG_REL_ Gateway SG_ 2600468612 NM_SAD_CBV_CRI 2000;
BA_REL_ "GenSigTimeoutTime" BU_SG_REL_ HDSG SG_ 2600468612 NM_SAD_CBV_CRI 2000;
BA_REL_ "GenSigTimeoutTime" BU_SG_REL_ IEZS SG_ 2600468612 NM_SAD_CBV_CRI 2000;
BA_REL_ "GenSigTimeoutTime" BU_SG_REL_ MFG SG_ 2600468612 NM_SAD_CBV_CRI 2000;
BA_REL_ "GenSigTimeoutTime" BU_SG_REL_ MSBBR SG_ 2600468612 NM_SAD_CBV_CRI 2000;
BA_REL_ "GenSigTimeoutTime" BU_SG_REL_ SAD SG_ 2600468612 NM_SAD_CBV_CRI 2000;
BA_REL_ "GenSigTimeoutTime" BU_SG_REL_ SAD2 SG_ 2600468612 NM_SAD_CBV_CRI 2000;
BA_REL_ "GenSigTimeoutTime" BU_SG_REL_ SitzMem_BFS SG_ 2600468612 NM_SAD_CBV_CRI 2000;
BA_REL_ "GenSigTimeoutTime" BU_SG_REL_ SitzMem_FS SG_ 2600468612 NM_SAD_CBV_CRI 2000;
BA_REL_ "GenSigTimeoutTime" BU_SG_REL_ SitzMem_HBFS SG_ 2600468612 NM_SAD_CBV_CRI 2000;
BA_REL_ "GenSigTimeoutTime" BU_SG_REL_ SitzMem_HFS SG_ 2600468612 NM_SAD_CBV_CRI 2000;
BA_REL_ "GenSigTimeoutTime" BU_SG_REL_ SitzMem_SR3 SG_ 2600468612 NM_SAD_CBV_CRI 2000;
BA_REL_ "GenSigTimeoutTime" BU_SG_REL_ SpoilerSG SG_ 2600468612 NM_SAD_CBV_CRI 2000;
BA_REL_ "GenSigTimeoutTime" BU_SG_REL_ TSG_BFS SG_ 2600468612 NM_SAD_CBV_CRI 2000;
BA_REL_ "GenSigTimeoutTime" BU_SG_REL_ TSG_FS SG_ 2600468612 NM_SAD_CBV_CRI 2000;
BA_REL_ "GenSigTimeoutTime" BU_SG_REL_ VSG SG_ 2600468612 NM_SAD_CBV_CRI 2000;
BA_REL_ "GenSigTimeoutTime" BU_SG_REL_ VTS SG_ 2600468612 NM_SAD_CBV_CRI 2000;
BA_REL_ "GenSigTimeoutTime" BU_SG_REL_ Gateway SG_ 2600468612 NM_SAD_Car_Wakeup 2000;
BA_REL_ "GenSigTimeoutTime" BU_SG_REL_ AAG SG_ 2600468612 NM_SAD_CAB 2000;
BA_REL_ "GenSigTimeoutTime" BU_SG_REL_ BCM1 SG_ 2600468612 NM_SAD_CAB 2000;
BA_REL_ "GenSigTimeoutTime" BU_SG_REL_ BCM2 SG_ 2600468612 NM_SAD_CAB 2000;
BA_REL_ "GenSigTimeoutTime" BU_SG_REL_ ELV SG_ 2600468612 NM_SAD_CAB 2000;
BA_REL_ "GenSigTimeoutTime" BU_SG_REL_ Gateway SG_ 2600468612 NM_SAD_CAB 2000;
BA_REL_ "GenSigTimeoutTime" BU_SG_REL_ HDSG SG_ 2600468612 NM_SAD_CAB 2000;
BA_REL_ "GenSigTimeoutTime" BU_SG_REL_ IEZS SG_ 2600468612 NM_SAD_CAB 2000;
BA_REL_ "GenSigTimeoutTime" BU_SG_REL_ MFG SG_ 2600468612 NM_SAD_CAB 2000;
BA_REL_ "GenSigTimeoutTime" BU_SG_REL_ MSBBR SG_ 2600468612 NM_SAD_CAB 2000;
BA_REL_ "GenSigTimeoutTime" BU_SG_REL_ SAD SG_ 2600468612 NM_SAD_CAB 2000;
BA_REL_ "GenSigTimeoutTime" BU_SG_REL_ SAD2 SG_ 2600468612 NM_SAD_CAB 2000;
BA_REL_ "GenSigTimeoutTime" BU_SG_REL_ SitzMem_BFS SG_ 2600468612 NM_SAD_CAB 2000;
BA_REL_ "GenSigTimeoutTime" BU_SG_REL_ SitzMem_FS SG_ 2600468612 NM_SAD_CAB 2000;
BA_REL_ "GenSigTimeoutTime" BU_SG_REL_ SitzMem_HBFS SG_ 2600468612 NM_SAD_CAB 2000;
BA_REL_ "GenSigTimeoutTime" BU_SG_REL_ SitzMem_HFS SG_ 2600468612 NM_SAD_CAB 2000;
BA_REL_ "GenSigTimeoutTime" BU_SG_REL_ SitzMem_SR3 SG_ 2600468612 NM_SAD_CAB 2000;
BA_REL_ "GenSigTimeoutTime" BU_SG_REL_ SpoilerSG SG_ 2600468612 NM_SAD_CAB 2000;
BA_REL_ "GenSigTimeoutTime" BU_SG_REL_ TSG_BFS SG_ 2600468612 NM_SAD_CAB 2000;
BA_REL_ "GenSigTimeoutTime" BU_SG_REL_ TSG_FS SG_ 2600468612 NM_SAD_CAB 2000;
BA_REL_ "GenSigTimeoutTime" BU_SG_REL_ VSG SG_ 2600468612 NM_SAD_CAB 2000;
BA_REL_ "GenSigTimeoutTime" BU_SG_REL_ VTS SG_ 2600468612 NM_SAD_CAB 2000;
BA_REL_ "GenSigTimeoutTime" BU_SG_REL_ AAG SG_ 2600468640 NM_SAD2_SNI 2000;
BA_REL_ "GenSigTimeoutTime" BU_SG_REL_ BCM1 SG_ 2600468640 NM_SAD2_SNI 2000;
BA_REL_ "GenSigTimeoutTime" BU_SG_REL_ BCM2 SG_ 2600468640 NM_SAD2_SNI 2000;
BA_REL_ "GenSigTimeoutTime" BU_SG_REL_ ELV SG_ 2600468640 NM_SAD2_SNI 2000;
BA_REL_ "GenSigTimeoutTime" BU_SG_REL_ Gateway SG_ 2600468640 NM_SAD2_SNI 2000;
BA_REL_ "GenSigTimeoutTime" BU_SG_REL_ HDSG SG_ 2600468640 NM_SAD2_SNI 2000;
BA_REL_ "GenSigTimeoutTime" BU_SG_REL_ IEZS SG_ 2600468640 NM_SAD2_SNI 2000;
BA_REL_ "GenSigTimeoutTime" BU_SG_REL_ MFG SG_ 2600468640 NM_SAD2_SNI 2000;
BA_REL_ "GenSigTimeoutTime" BU_SG_REL_ MSBBR SG_ 2600468640 NM_SAD2_SNI 2000;
BA_REL_ "GenSigTimeoutTime" BU_SG_REL_ SAD SG_ 2600468640 NM_SAD2_SNI 2000;
BA_REL_ "GenSigTimeoutTime" BU_SG_REL_ SAD2 SG_ 2600468640 NM_SAD2_SNI 2000;
BA_REL_ "GenSigTimeoutTime" BU_SG_REL_ SitzMem_BFS SG_ 2600468640 NM_SAD2_SNI 2000;
BA_REL_ "GenSigTimeoutTime" BU_SG_REL_ SitzMem_FS SG_ 2600468640 NM_SAD2_SNI 2000;
BA_REL_ "GenSigTimeoutTime" BU_SG_REL_ SitzMem_HBFS SG_ 2600468640 NM_SAD2_SNI 2000;
BA_REL_ "GenSigTimeoutTime" BU_SG_REL_ SitzMem_HFS SG_ 2600468640 NM_SAD2_SNI 2000;
BA_REL_ "GenSigTimeoutTime" BU_SG_REL_ SitzMem_SR3 SG_ 2600468640 NM_SAD2_SNI 2000;
BA_REL_ "GenSigTimeoutTime" BU_SG_REL_ SpoilerSG SG_ 2600468640 NM_SAD2_SNI 2000;
BA_REL_ "GenSigTimeoutTime" BU_SG_REL_ TSG_BFS SG_ 2600468640 NM_SAD2_SNI 2000;
BA_REL_ "GenSigTimeoutTime" BU_SG_REL_ TSG_FS SG_ 2600468640 NM_SAD2_SNI 2000;
BA_REL_ "GenSigTimeoutTime" BU_SG_REL_ VSG SG_ 2600468640 NM_SAD2_SNI 2000;
BA_REL_ "GenSigTimeoutTime" BU_SG_REL_ VTS SG_ 2600468640 NM_SAD2_SNI 2000;
BA_REL_ "GenSigTimeoutTime" BU_SG_REL_ AAG SG_ 2600468640 NM_SAD2_CBV_CRI 2000;
BA_REL_ "GenSigTimeoutTime" BU_SG_REL_ BCM1 SG_ 2600468640 NM_SAD2_CBV_CRI 2000;
BA_REL_ "GenSigTimeoutTime" BU_SG_REL_ BCM2 SG_ 2600468640 NM_SAD2_CBV_CRI 2000;
BA_REL_ "GenSigTimeoutTime" BU_SG_REL_ ELV SG_ 2600468640 NM_SAD2_CBV_CRI 2000;
BA_REL_ "GenSigTimeoutTime" BU_SG_REL_ Gateway SG_ 2600468640 NM_SAD2_CBV_CRI 2000;
BA_REL_ "GenSigTimeoutTime" BU_SG_REL_ HDSG SG_ 2600468640 NM_SAD2_CBV_CRI 2000;
BA_REL_ "GenSigTimeoutTime" BU_SG_REL_ IEZS SG_ 2600468640 NM_SAD2_CBV_CRI 2000;
BA_REL_ "GenSigTimeoutTime" BU_SG_REL_ MFG SG_ 2600468640 NM_SAD2_CBV_CRI 2000;
BA_REL_ "GenSigTimeoutTime" BU_SG_REL_ MSBBR SG_ 2600468640 NM_SAD2_CBV_CRI 2000;
BA_REL_ "GenSigTimeoutTime" BU_SG_REL_ SAD SG_ 2600468640 NM_SAD2_CBV_CRI 2000;
BA_REL_ "GenSigTimeoutTime" BU_SG_REL_ SAD2 SG_ 2600468640 NM_SAD2_CBV_CRI 2000;
BA_REL_ "GenSigTimeoutTime" BU_SG_REL_ SitzMem_BFS SG_ 2600468640 NM_SAD2_CBV_CRI 2000;
BA_REL_ "GenSigTimeoutTime" BU_SG_REL_ SitzMem_FS SG_ 2600468640 NM_SAD2_CBV_CRI 2000;
BA_REL_ "GenSigTimeoutTime" BU_SG_REL_ SitzMem_HBFS SG_ 2600468640 NM_SAD2_CBV_CRI 2000;
BA_REL_ "GenSigTimeoutTime" BU_SG_REL_ SitzMem_HFS SG_ 2600468640 NM_SAD2_CBV_CRI 2000;
BA_REL_ "GenSigTimeoutTime" BU_SG_REL_ SitzMem_SR3 SG_ 2600468640 NM_SAD2_CBV_CRI 2000;
BA_REL_ "GenSigTimeoutTime" BU_SG_REL_ SpoilerSG SG_ 2600468640 NM_SAD2_CBV_CRI 2000;
BA_REL_ "GenSigTimeoutTime" BU_SG_REL_ TSG_BFS SG_ 2600468640 NM_SAD2_CBV_CRI 2000;
BA_REL_ "GenSigTimeoutTime" BU_SG_REL_ TSG_FS SG_ 2600468640 NM_SAD2_CBV_CRI 2000;
BA_REL_ "GenSigTimeoutTime" BU_SG_REL_ VSG SG_ 2600468640 NM_SAD2_CBV_CRI 2000;
BA_REL_ "GenSigTimeoutTime" BU_SG_REL_ VTS SG_ 2600468640 NM_SAD2_CBV_CRI 2000;
BA_REL_ "GenSigTimeoutTime" BU_SG_REL_ AAG SG_ 2600468640 NM_SAD2_CAB 2000;
BA_REL_ "GenSigTimeoutTime" BU_SG_REL_ BCM1 SG_ 2600468640 NM_SAD2_CAB 2000;
BA_REL_ "GenSigTimeoutTime" BU_SG_REL_ BCM2 SG_ 2600468640 NM_SAD2_CAB 2000;
BA_REL_ "GenSigTimeoutTime" BU_SG_REL_ ELV SG_ 2600468640 NM_SAD2_CAB 2000;
BA_REL_ "GenSigTimeoutTime" BU_SG_REL_ Gateway SG_ 2600468640 NM_SAD2_CAB 2000;
BA_REL_ "GenSigTimeoutTime" BU_SG_REL_ HDSG SG_ 2600468640 NM_SAD2_CAB 2000;
BA_REL_ "GenSigTimeoutTime" BU_SG_REL_ IEZS SG_ 2600468640 NM_SAD2_CAB 2000;
BA_REL_ "GenSigTimeoutTime" BU_SG_REL_ MFG SG_ 2600468640 NM_SAD2_CAB 2000;
BA_REL_ "GenSigTimeoutTime" BU_SG_REL_ MSBBR SG_ 2600468640 NM_SAD2_CAB 2000;
BA_REL_ "GenSigTimeoutTime" BU_SG_REL_ SAD SG_ 2600468640 NM_SAD2_CAB 2000;
BA_REL_ "GenSigTimeoutTime" BU_SG_REL_ SAD2 SG_ 2600468640 NM_SAD2_CAB 2000;
BA_REL_ "GenSigTimeoutTime" BU_SG_REL_ SitzMem_BFS SG_ 2600468640 NM_SAD2_CAB 2000;
BA_REL_ "GenSigTimeoutTime" BU_SG_REL_ SitzMem_FS SG_ 2600468640 NM_SAD2_CAB 2000;
BA_REL_ "GenSigTimeoutTime" BU_SG_REL_ SitzMem_HBFS SG_ 2600468640 NM_SAD2_CAB 2000;
BA_REL_ "GenSigTimeoutTime" BU_SG_REL_ SitzMem_HFS SG_ 2600468640 NM_SAD2_CAB 2000;
BA_REL_ "GenSigTimeoutTime" BU_SG_REL_ SitzMem_SR3 SG_ 2600468640 NM_SAD2_CAB 2000;
BA_REL_ "GenSigTimeoutTime" BU_SG_REL_ SpoilerSG SG_ 2600468640 NM_SAD2_CAB 2000;
BA_REL_ "GenSigTimeoutTime" BU_SG_REL_ TSG_BFS SG_ 2600468640 NM_SAD2_CAB 2000;
BA_REL_ "GenSigTimeoutTime" BU_SG_REL_ TSG_FS SG_ 2600468640 NM_SAD2_CAB 2000;
BA_REL_ "GenSigTimeoutTime" BU_SG_REL_ VSG SG_ 2600468640 NM_SAD2_CAB 2000;
BA_REL_ "GenSigTimeoutTime" BU_SG_REL_ VTS SG_ 2600468640 NM_SAD2_CAB 2000;
BA_REL_ "GenSigTimeoutTime" BU_SG_REL_ AAG SG_ 2600468635 NM_MSBBR_SNI 2000;
BA_REL_ "GenSigTimeoutTime" BU_SG_REL_ BCM1 SG_ 2600468635 NM_MSBBR_SNI 2000;
BA_REL_ "GenSigTimeoutTime" BU_SG_REL_ BCM2 SG_ 2600468635 NM_MSBBR_SNI 2000;
BA_REL_ "GenSigTimeoutTime" BU_SG_REL_ ELV SG_ 2600468635 NM_MSBBR_SNI 2000;
BA_REL_ "GenSigTimeoutTime" BU_SG_REL_ Gateway SG_ 2600468635 NM_MSBBR_SNI 2000;
BA_REL_ "GenSigTimeoutTime" BU_SG_REL_ HDSG SG_ 2600468635 NM_MSBBR_SNI 2000;
BA_REL_ "GenSigTimeoutTime" BU_SG_REL_ IEZS SG_ 2600468635 NM_MSBBR_SNI 2000;
BA_REL_ "GenSigTimeoutTime" BU_SG_REL_ MFG SG_ 2600468635 NM_MSBBR_SNI 2000;
BA_REL_ "GenSigTimeoutTime" BU_SG_REL_ MSBBR SG_ 2600468635 NM_MSBBR_SNI 2000;
BA_REL_ "GenSigTimeoutTime" BU_SG_REL_ SAD SG_ 2600468635 NM_MSBBR_SNI 2000;
BA_REL_ "GenSigTimeoutTime" BU_SG_REL_ SAD2 SG_ 2600468635 NM_MSBBR_SNI 2000;
BA_REL_ "GenSigTimeoutTime" BU_SG_REL_ SitzMem_BFS SG_ 2600468635 NM_MSBBR_SNI 2000;
BA_REL_ "GenSigTimeoutTime" BU_SG_REL_ SitzMem_FS SG_ 2600468635 NM_MSBBR_SNI 2000;
BA_REL_ "GenSigTimeoutTime" BU_SG_REL_ SitzMem_HBFS SG_ 2600468635 NM_MSBBR_SNI 2000;
BA_REL_ "GenSigTimeoutTime" BU_SG_REL_ SitzMem_HFS SG_ 2600468635 NM_MSBBR_SNI 2000;
BA_REL_ "GenSigTimeoutTime" BU_SG_REL_ SitzMem_SR3 SG_ 2600468635 NM_MSBBR_SNI 2000;
BA_REL_ "GenSigTimeoutTime" BU_SG_REL_ SpoilerSG SG_ 2600468635 NM_MSBBR_SNI 2000;
BA_REL_ "GenSigTimeoutTime" BU_SG_REL_ TSG_BFS SG_ 2600468635 NM_MSBBR_SNI 2000;
BA_REL_ "GenSigTimeoutTime" BU_SG_REL_ TSG_FS SG_ 2600468635 NM_MSBBR_SNI 2000;
BA_REL_ "GenSigTimeoutTime" BU_SG_REL_ VSG SG_ 2600468635 NM_MSBBR_SNI 2000;
BA_REL_ "GenSigTimeoutTime" BU_SG_REL_ VTS SG_ 2600468635 NM_MSBBR_SNI 2000;
BA_REL_ "GenSigTimeoutTime" BU_SG_REL_ AAG SG_ 2600468635 NM_MSBBR_CBV_CRI 2000;
BA_REL_ "GenSigTimeoutTime" BU_SG_REL_ BCM1 SG_ 2600468635 NM_MSBBR_CBV_CRI 2000;
BA_REL_ "GenSigTimeoutTime" BU_SG_REL_ BCM2 SG_ 2600468635 NM_MSBBR_CBV_CRI 2000;
BA_REL_ "GenSigTimeoutTime" BU_SG_REL_ ELV SG_ 2600468635 NM_MSBBR_CBV_CRI 2000;
BA_REL_ "GenSigTimeoutTime" BU_SG_REL_ Gateway SG_ 2600468635 NM_MSBBR_CBV_CRI 2000;
BA_REL_ "GenSigTimeoutTime" BU_SG_REL_ HDSG SG_ 2600468635 NM_MSBBR_CBV_CRI 2000;
BA_REL_ "GenSigTimeoutTime" BU_SG_REL_ IEZS SG_ 2600468635 NM_MSBBR_CBV_CRI 2000;
BA_REL_ "GenSigTimeoutTime" BU_SG_REL_ MFG SG_ 2600468635 NM_MSBBR_CBV_CRI 2000;
BA_REL_ "GenSigTimeoutTime" BU_SG_REL_ MSBBR SG_ 2600468635 NM_MSBBR_CBV_CRI 2000;
BA_REL_ "GenSigTimeoutTime" BU_SG_REL_ SAD SG_ 2600468635 NM_MSBBR_CBV_CRI 2000;
BA_REL_ "GenSigTimeoutTime" BU_SG_REL_ SAD2 SG_ 2600468635 NM_MSBBR_CBV_CRI 2000;
BA_REL_ "GenSigTimeoutTime" BU_SG_REL_ SitzMem_BFS SG_ 2600468635 NM_MSBBR_CBV_CRI 2000;
BA_REL_ "GenSigTimeoutTime" BU_SG_REL_ SitzMem_FS SG_ 2600468635 NM_MSBBR_CBV_CRI 2000;
BA_REL_ "GenSigTimeoutTime" BU_SG_REL_ SitzMem_HBFS SG_ 2600468635 NM_MSBBR_CBV_CRI 2000;
BA_REL_ "GenSigTimeoutTime" BU_SG_REL_ SitzMem_HFS SG_ 2600468635 NM_MSBBR_CBV_CRI 2000;
BA_REL_ "GenSigTimeoutTime" BU_SG_REL_ SitzMem_SR3 SG_ 2600468635 NM_MSBBR_CBV_CRI 2000;
BA_REL_ "GenSigTimeoutTime" BU_SG_REL_ SpoilerSG SG_ 2600468635 NM_MSBBR_CBV_CRI 2000;
BA_REL_ "GenSigTimeoutTime" BU_SG_REL_ TSG_BFS SG_ 2600468635 NM_MSBBR_CBV_CRI 2000;
BA_REL_ "GenSigTimeoutTime" BU_SG_REL_ TSG_FS SG_ 2600468635 NM_MSBBR_CBV_CRI 2000;
BA_REL_ "GenSigTimeoutTime" BU_SG_REL_ VSG SG_ 2600468635 NM_MSBBR_CBV_CRI 2000;
BA_REL_ "GenSigTimeoutTime" BU_SG_REL_ VTS SG_ 2600468635 NM_MSBBR_CBV_CRI 2000;
BA_REL_ "GenSigTimeoutTime" BU_SG_REL_ AAG SG_ 2600468635 NM_MSBBR_CAB 2000;
BA_REL_ "GenSigTimeoutTime" BU_SG_REL_ BCM1 SG_ 2600468635 NM_MSBBR_CAB 2000;
BA_REL_ "GenSigTimeoutTime" BU_SG_REL_ BCM2 SG_ 2600468635 NM_MSBBR_CAB 2000;
BA_REL_ "GenSigTimeoutTime" BU_SG_REL_ ELV SG_ 2600468635 NM_MSBBR_CAB 2000;
BA_REL_ "GenSigTimeoutTime" BU_SG_REL_ Gateway SG_ 2600468635 NM_MSBBR_CAB 2000;
BA_REL_ "GenSigTimeoutTime" BU_SG_REL_ HDSG SG_ 2600468635 NM_MSBBR_CAB 2000;
BA_REL_ "GenSigTimeoutTime" BU_SG_REL_ IEZS SG_ 2600468635 NM_MSBBR_CAB 2000;
BA_REL_ "GenSigTimeoutTime" BU_SG_REL_ MFG SG_ 2600468635 NM_MSBBR_CAB 2000;
BA_REL_ "GenSigTimeoutTime" BU_SG_REL_ MSBBR SG_ 2600468635 NM_MSBBR_CAB 2000;
BA_REL_ "GenSigTimeoutTime" BU_SG_REL_ SAD SG_ 2600468635 NM_MSBBR_CAB 2000;
BA_REL_ "GenSigTimeoutTime" BU_SG_REL_ SAD2 SG_ 2600468635 NM_MSBBR_CAB 2000;
BA_REL_ "GenSigTimeoutTime" BU_SG_REL_ SitzMem_BFS SG_ 2600468635 NM_MSBBR_CAB 2000;
BA_REL_ "GenSigTimeoutTime" BU_SG_REL_ SitzMem_FS SG_ 2600468635 NM_MSBBR_CAB 2000;
BA_REL_ "GenSigTimeoutTime" BU_SG_REL_ SitzMem_HBFS SG_ 2600468635 NM_MSBBR_CAB 2000;
BA_REL_ "GenSigTimeoutTime" BU_SG_REL_ SitzMem_HFS SG_ 2600468635 NM_MSBBR_CAB 2000;
BA_REL_ "GenSigTimeoutTime" BU_SG_REL_ SitzMem_SR3 SG_ 2600468635 NM_MSBBR_CAB 2000;
BA_REL_ "GenSigTimeoutTime" BU_SG_REL_ SpoilerSG SG_ 2600468635 NM_MSBBR_CAB 2000;
BA_REL_ "GenSigTimeoutTime" BU_SG_REL_ TSG_BFS SG_ 2600468635 NM_MSBBR_CAB 2000;
BA_REL_ "GenSigTimeoutTime" BU_SG_REL_ TSG_FS SG_ 2600468635 NM_MSBBR_CAB 2000;
BA_REL_ "GenSigTimeoutTime" BU_SG_REL_ VSG SG_ 2600468635 NM_MSBBR_CAB 2000;
BA_REL_ "GenSigTimeoutTime" BU_SG_REL_ VTS SG_ 2600468635 NM_MSBBR_CAB 2000;
BA_REL_ "GenSigTimeoutTime" BU_SG_REL_ AAG SG_ 2600468557 NM_Sitzmemo_BFS_SNI 2000;
BA_REL_ "GenSigTimeoutTime" BU_SG_REL_ BCM1 SG_ 2600468557 NM_Sitzmemo_BFS_SNI 2000;
BA_REL_ "GenSigTimeoutTime" BU_SG_REL_ BCM2 SG_ 2600468557 NM_Sitzmemo_BFS_SNI 2000;
BA_REL_ "GenSigTimeoutTime" BU_SG_REL_ ELV SG_ 2600468557 NM_Sitzmemo_BFS_SNI 2000;
BA_REL_ "GenSigTimeoutTime" BU_SG_REL_ Gateway SG_ 2600468557 NM_Sitzmemo_BFS_SNI 2000;
BA_REL_ "GenSigTimeoutTime" BU_SG_REL_ HDSG SG_ 2600468557 NM_Sitzmemo_BFS_SNI 2000;
BA_REL_ "GenSigTimeoutTime" BU_SG_REL_ IEZS SG_ 2600468557 NM_Sitzmemo_BFS_SNI 2000;
BA_REL_ "GenSigTimeoutTime" BU_SG_REL_ MFG SG_ 2600468557 NM_Sitzmemo_BFS_SNI 2000;
BA_REL_ "GenSigTimeoutTime" BU_SG_REL_ MSBBR SG_ 2600468557 NM_Sitzmemo_BFS_SNI 2000;
BA_REL_ "GenSigTimeoutTime" BU_SG_REL_ SAD SG_ 2600468557 NM_Sitzmemo_BFS_SNI 2000;
BA_REL_ "GenSigTimeoutTime" BU_SG_REL_ SAD2 SG_ 2600468557 NM_Sitzmemo_BFS_SNI 2000;
BA_REL_ "GenSigTimeoutTime" BU_SG_REL_ SitzMem_BFS SG_ 2600468557 NM_Sitzmemo_BFS_SNI 2000;
BA_REL_ "GenSigTimeoutTime" BU_SG_REL_ SitzMem_FS SG_ 2600468557 NM_Sitzmemo_BFS_SNI 2000;
BA_REL_ "GenSigTimeoutTime" BU_SG_REL_ SitzMem_HBFS SG_ 2600468557 NM_Sitzmemo_BFS_SNI 2000;
BA_REL_ "GenSigTimeoutTime" BU_SG_REL_ SitzMem_HFS SG_ 2600468557 NM_Sitzmemo_BFS_SNI 2000;
BA_REL_ "GenSigTimeoutTime" BU_SG_REL_ SitzMem_SR3 SG_ 2600468557 NM_Sitzmemo_BFS_SNI 2000;
BA_REL_ "GenSigTimeoutTime" BU_SG_REL_ SpoilerSG SG_ 2600468557 NM_Sitzmemo_BFS_SNI 2000;
BA_REL_ "GenSigTimeoutTime" BU_SG_REL_ TSG_BFS SG_ 2600468557 NM_Sitzmemo_BFS_SNI 2000;
BA_REL_ "GenSigTimeoutTime" BU_SG_REL_ TSG_FS SG_ 2600468557 NM_Sitzmemo_BFS_SNI 2000;
BA_REL_ "GenSigTimeoutTime" BU_SG_REL_ VSG SG_ 2600468557 NM_Sitzmemo_BFS_SNI 2000;
BA_REL_ "GenSigTimeoutTime" BU_SG_REL_ VTS SG_ 2600468557 NM_Sitzmemo_BFS_SNI 2000;
BA_REL_ "GenSigTimeoutTime" BU_SG_REL_ Gateway SG_ 2600468557 NM_Sitzmemo_BFS_CBV_AWB 2000;
BA_REL_ "GenSigTimeoutTime" BU_SG_REL_ AAG SG_ 2600468557 NM_Sitzmemo_BFS_CBV_CRI 2000;
BA_REL_ "GenSigTimeoutTime" BU_SG_REL_ BCM1 SG_ 2600468557 NM_Sitzmemo_BFS_CBV_CRI 2000;
BA_REL_ "GenSigTimeoutTime" BU_SG_REL_ BCM2 SG_ 2600468557 NM_Sitzmemo_BFS_CBV_CRI 2000;
BA_REL_ "GenSigTimeoutTime" BU_SG_REL_ ELV SG_ 2600468557 NM_Sitzmemo_BFS_CBV_CRI 2000;
BA_REL_ "GenSigTimeoutTime" BU_SG_REL_ Gateway SG_ 2600468557 NM_Sitzmemo_BFS_CBV_CRI 2000;
BA_REL_ "GenSigTimeoutTime" BU_SG_REL_ HDSG SG_ 2600468557 NM_Sitzmemo_BFS_CBV_CRI 2000;
BA_REL_ "GenSigTimeoutTime" BU_SG_REL_ IEZS SG_ 2600468557 NM_Sitzmemo_BFS_CBV_CRI 2000;
BA_REL_ "GenSigTimeoutTime" BU_SG_REL_ MFG SG_ 2600468557 NM_Sitzmemo_BFS_CBV_CRI 2000;
BA_REL_ "GenSigTimeoutTime" BU_SG_REL_ MSBBR SG_ 2600468557 NM_Sitzmemo_BFS_CBV_CRI 2000;
BA_REL_ "GenSigTimeoutTime" BU_SG_REL_ SAD SG_ 2600468557 NM_Sitzmemo_BFS_CBV_CRI 2000;
BA_REL_ "GenSigTimeoutTime" BU_SG_REL_ SAD2 SG_ 2600468557 NM_Sitzmemo_BFS_CBV_CRI 2000;
BA_REL_ "GenSigTimeoutTime" BU_SG_REL_ SitzMem_BFS SG_ 2600468557 NM_Sitzmemo_BFS_CBV_CRI 2000;
BA_REL_ "GenSigTimeoutTime" BU_SG_REL_ SitzMem_FS SG_ 2600468557 NM_Sitzmemo_BFS_CBV_CRI 2000;
BA_REL_ "GenSigTimeoutTime" BU_SG_REL_ SitzMem_HBFS SG_ 2600468557 NM_Sitzmemo_BFS_CBV_CRI 2000;
BA_REL_ "GenSigTimeoutTime" BU_SG_REL_ SitzMem_HFS SG_ 2600468557 NM_Sitzmemo_BFS_CBV_CRI 2000;
BA_REL_ "GenSigTimeoutTime" BU_SG_REL_ SitzMem_SR3 SG_ 2600468557 NM_Sitzmemo_BFS_CBV_CRI 2000;
BA_REL_ "GenSigTimeoutTime" BU_SG_REL_ SpoilerSG SG_ 2600468557 NM_Sitzmemo_BFS_CBV_CRI 2000;
BA_REL_ "GenSigTimeoutTime" BU_SG_REL_ TSG_BFS SG_ 2600468557 NM_Sitzmemo_BFS_CBV_CRI 2000;
BA_REL_ "GenSigTimeoutTime" BU_SG_REL_ TSG_FS SG_ 2600468557 NM_Sitzmemo_BFS_CBV_CRI 2000;
BA_REL_ "GenSigTimeoutTime" BU_SG_REL_ VSG SG_ 2600468557 NM_Sitzmemo_BFS_CBV_CRI 2000;
BA_REL_ "GenSigTimeoutTime" BU_SG_REL_ VTS SG_ 2600468557 NM_Sitzmemo_BFS_CBV_CRI 2000;
BA_REL_ "GenSigTimeoutTime" BU_SG_REL_ Gateway SG_ 2600468557 NM_Sitzmemo_BFS_Car_Wakeup 2000;
BA_REL_ "GenSigTimeoutTime" BU_SG_REL_ AAG SG_ 2600468557 NM_Sitzmemo_BFS_CAB 2000;
BA_REL_ "GenSigTimeoutTime" BU_SG_REL_ BCM1 SG_ 2600468557 NM_Sitzmemo_BFS_CAB 2000;
BA_REL_ "GenSigTimeoutTime" BU_SG_REL_ BCM2 SG_ 2600468557 NM_Sitzmemo_BFS_CAB 2000;
BA_REL_ "GenSigTimeoutTime" BU_SG_REL_ ELV SG_ 2600468557 NM_Sitzmemo_BFS_CAB 2000;
BA_REL_ "GenSigTimeoutTime" BU_SG_REL_ Gateway SG_ 2600468557 NM_Sitzmemo_BFS_CAB 2000;
BA_REL_ "GenSigTimeoutTime" BU_SG_REL_ HDSG SG_ 2600468557 NM_Sitzmemo_BFS_CAB 2000;
BA_REL_ "GenSigTimeoutTime" BU_SG_REL_ IEZS SG_ 2600468557 NM_Sitzmemo_BFS_CAB 2000;
BA_REL_ "GenSigTimeoutTime" BU_SG_REL_ MFG SG_ 2600468557 NM_Sitzmemo_BFS_CAB 2000;
BA_REL_ "GenSigTimeoutTime" BU_SG_REL_ MSBBR SG_ 2600468557 NM_Sitzmemo_BFS_CAB 2000;
BA_REL_ "GenSigTimeoutTime" BU_SG_REL_ SAD SG_ 2600468557 NM_Sitzmemo_BFS_CAB 2000;
BA_REL_ "GenSigTimeoutTime" BU_SG_REL_ SAD2 SG_ 2600468557 NM_Sitzmemo_BFS_CAB 2000;
BA_REL_ "GenSigTimeoutTime" BU_SG_REL_ SitzMem_BFS SG_ 2600468557 NM_Sitzmemo_BFS_CAB 2000;
BA_REL_ "GenSigTimeoutTime" BU_SG_REL_ SitzMem_FS SG_ 2600468557 NM_Sitzmemo_BFS_CAB 2000;
BA_REL_ "GenSigTimeoutTime" BU_SG_REL_ SitzMem_HBFS SG_ 2600468557 NM_Sitzmemo_BFS_CAB 2000;
BA_REL_ "GenSigTimeoutTime" BU_SG_REL_ SitzMem_HFS SG_ 2600468557 NM_Sitzmemo_BFS_CAB 2000;
BA_REL_ "GenSigTimeoutTime" BU_SG_REL_ SitzMem_SR3 SG_ 2600468557 NM_Sitzmemo_BFS_CAB 2000;
BA_REL_ "GenSigTimeoutTime" BU_SG_REL_ SpoilerSG SG_ 2600468557 NM_Sitzmemo_BFS_CAB 2000;
BA_REL_ "GenSigTimeoutTime" BU_SG_REL_ TSG_BFS SG_ 2600468557 NM_Sitzmemo_BFS_CAB 2000;
BA_REL_ "GenSigTimeoutTime" BU_SG_REL_ TSG_FS SG_ 2600468557 NM_Sitzmemo_BFS_CAB 2000;
BA_REL_ "GenSigTimeoutTime" BU_SG_REL_ VSG SG_ 2600468557 NM_Sitzmemo_BFS_CAB 2000;
BA_REL_ "GenSigTimeoutTime" BU_SG_REL_ VTS SG_ 2600468557 NM_Sitzmemo_BFS_CAB 2000;
BA_REL_ "GenSigTimeoutTime" BU_SG_REL_ AAG SG_ 2600468616 NM_Sitz_BFSFo_SNI 2000;
BA_REL_ "GenSigTimeoutTime" BU_SG_REL_ BCM1 SG_ 2600468616 NM_Sitz_BFSFo_SNI 2000;
BA_REL_ "GenSigTimeoutTime" BU_SG_REL_ BCM2 SG_ 2600468616 NM_Sitz_BFSFo_SNI 2000;
BA_REL_ "GenSigTimeoutTime" BU_SG_REL_ ELV SG_ 2600468616 NM_Sitz_BFSFo_SNI 2000;
BA_REL_ "GenSigTimeoutTime" BU_SG_REL_ Gateway SG_ 2600468616 NM_Sitz_BFSFo_SNI 2000;
BA_REL_ "GenSigTimeoutTime" BU_SG_REL_ HDSG SG_ 2600468616 NM_Sitz_BFSFo_SNI 2000;
BA_REL_ "GenSigTimeoutTime" BU_SG_REL_ IEZS SG_ 2600468616 NM_Sitz_BFSFo_SNI 2000;
BA_REL_ "GenSigTimeoutTime" BU_SG_REL_ MFG SG_ 2600468616 NM_Sitz_BFSFo_SNI 2000;
BA_REL_ "GenSigTimeoutTime" BU_SG_REL_ MSBBR SG_ 2600468616 NM_Sitz_BFSFo_SNI 2000;
BA_REL_ "GenSigTimeoutTime" BU_SG_REL_ SAD SG_ 2600468616 NM_Sitz_BFSFo_SNI 2000;
BA_REL_ "GenSigTimeoutTime" BU_SG_REL_ SAD2 SG_ 2600468616 NM_Sitz_BFSFo_SNI 2000;
BA_REL_ "GenSigTimeoutTime" BU_SG_REL_ SitzMem_BFS SG_ 2600468616 NM_Sitz_BFSFo_SNI 2000;
BA_REL_ "GenSigTimeoutTime" BU_SG_REL_ SitzMem_FS SG_ 2600468616 NM_Sitz_BFSFo_SNI 2000;
BA_REL_ "GenSigTimeoutTime" BU_SG_REL_ SitzMem_HBFS SG_ 2600468616 NM_Sitz_BFSFo_SNI 2000;
BA_REL_ "GenSigTimeoutTime" BU_SG_REL_ SitzMem_HFS SG_ 2600468616 NM_Sitz_BFSFo_SNI 2000;
BA_REL_ "GenSigTimeoutTime" BU_SG_REL_ SitzMem_SR3 SG_ 2600468616 NM_Sitz_BFSFo_SNI 2000;
BA_REL_ "GenSigTimeoutTime" BU_SG_REL_ SpoilerSG SG_ 2600468616 NM_Sitz_BFSFo_SNI 2000;
BA_REL_ "GenSigTimeoutTime" BU_SG_REL_ TSG_BFS SG_ 2600468616 NM_Sitz_BFSFo_SNI 2000;
BA_REL_ "GenSigTimeoutTime" BU_SG_REL_ TSG_FS SG_ 2600468616 NM_Sitz_BFSFo_SNI 2000;
BA_REL_ "GenSigTimeoutTime" BU_SG_REL_ VSG SG_ 2600468616 NM_Sitz_BFSFo_SNI 2000;
BA_REL_ "GenSigTimeoutTime" BU_SG_REL_ VTS SG_ 2600468616 NM_Sitz_BFSFo_SNI 2000;
BA_REL_ "GenSigTimeoutTime" BU_SG_REL_ Gateway SG_ 2600468616 NM_Sitz_BFSFo_CBV_AWB 2000;
BA_REL_ "GenSigTimeoutTime" BU_SG_REL_ AAG SG_ 2600468616 NM_Sitz_BFSFo_CBV_CRI 2000;
BA_REL_ "GenSigTimeoutTime" BU_SG_REL_ BCM1 SG_ 2600468616 NM_Sitz_BFSFo_CBV_CRI 2000;
BA_REL_ "GenSigTimeoutTime" BU_SG_REL_ BCM2 SG_ 2600468616 NM_Sitz_BFSFo_CBV_CRI 2000;
BA_REL_ "GenSigTimeoutTime" BU_SG_REL_ ELV SG_ 2600468616 NM_Sitz_BFSFo_CBV_CRI 2000;
BA_REL_ "GenSigTimeoutTime" BU_SG_REL_ Gateway SG_ 2600468616 NM_Sitz_BFSFo_CBV_CRI 2000;
BA_REL_ "GenSigTimeoutTime" BU_SG_REL_ HDSG SG_ 2600468616 NM_Sitz_BFSFo_CBV_CRI 2000;
BA_REL_ "GenSigTimeoutTime" BU_SG_REL_ IEZS SG_ 2600468616 NM_Sitz_BFSFo_CBV_CRI 2000;
BA_REL_ "GenSigTimeoutTime" BU_SG_REL_ MFG SG_ 2600468616 NM_Sitz_BFSFo_CBV_CRI 2000;
BA_REL_ "GenSigTimeoutTime" BU_SG_REL_ MSBBR SG_ 2600468616 NM_Sitz_BFSFo_CBV_CRI 2000;
BA_REL_ "GenSigTimeoutTime" BU_SG_REL_ SAD SG_ 2600468616 NM_Sitz_BFSFo_CBV_CRI 2000;
BA_REL_ "GenSigTimeoutTime" BU_SG_REL_ SAD2 SG_ 2600468616 NM_Sitz_BFSFo_CBV_CRI 2000;
BA_REL_ "GenSigTimeoutTime" BU_SG_REL_ SitzMem_BFS SG_ 2600468616 NM_Sitz_BFSFo_CBV_CRI 2000;
BA_REL_ "GenSigTimeoutTime" BU_SG_REL_ SitzMem_FS SG_ 2600468616 NM_Sitz_BFSFo_CBV_CRI 2000;
BA_REL_ "GenSigTimeoutTime" BU_SG_REL_ SitzMem_HBFS SG_ 2600468616 NM_Sitz_BFSFo_CBV_CRI 2000;
BA_REL_ "GenSigTimeoutTime" BU_SG_REL_ SitzMem_HFS SG_ 2600468616 NM_Sitz_BFSFo_CBV_CRI 2000;
BA_REL_ "GenSigTimeoutTime" BU_SG_REL_ SitzMem_SR3 SG_ 2600468616 NM_Sitz_BFSFo_CBV_CRI 2000;
BA_REL_ "GenSigTimeoutTime" BU_SG_REL_ SpoilerSG SG_ 2600468616 NM_Sitz_BFSFo_CBV_CRI 2000;
BA_REL_ "GenSigTimeoutTime" BU_SG_REL_ TSG_BFS SG_ 2600468616 NM_Sitz_BFSFo_CBV_CRI 2000;
BA_REL_ "GenSigTimeoutTime" BU_SG_REL_ TSG_FS SG_ 2600468616 NM_Sitz_BFSFo_CBV_CRI 2000;
BA_REL_ "GenSigTimeoutTime" BU_SG_REL_ VSG SG_ 2600468616 NM_Sitz_BFSFo_CBV_CRI 2000;
BA_REL_ "GenSigTimeoutTime" BU_SG_REL_ VTS SG_ 2600468616 NM_Sitz_BFSFo_CBV_CRI 2000;
BA_REL_ "GenSigTimeoutTime" BU_SG_REL_ Gateway SG_ 2600468616 NM_Sitz_BFSFo_Car_Wakeup 2000;
BA_REL_ "GenSigTimeoutTime" BU_SG_REL_ AAG SG_ 2600468616 NM_Sitz_BFSFo_CAB 2000;
BA_REL_ "GenSigTimeoutTime" BU_SG_REL_ BCM1 SG_ 2600468616 NM_Sitz_BFSFo_CAB 2000;
BA_REL_ "GenSigTimeoutTime" BU_SG_REL_ BCM2 SG_ 2600468616 NM_Sitz_BFSFo_CAB 2000;
BA_REL_ "GenSigTimeoutTime" BU_SG_REL_ ELV SG_ 2600468616 NM_Sitz_BFSFo_CAB 2000;
BA_REL_ "GenSigTimeoutTime" BU_SG_REL_ Gateway SG_ 2600468616 NM_Sitz_BFSFo_CAB 2000;
BA_REL_ "GenSigTimeoutTime" BU_SG_REL_ HDSG SG_ 2600468616 NM_Sitz_BFSFo_CAB 2000;
BA_REL_ "GenSigTimeoutTime" BU_SG_REL_ IEZS SG_ 2600468616 NM_Sitz_BFSFo_CAB 2000;
BA_REL_ "GenSigTimeoutTime" BU_SG_REL_ MFG SG_ 2600468616 NM_Sitz_BFSFo_CAB 2000;
BA_REL_ "GenSigTimeoutTime" BU_SG_REL_ MSBBR SG_ 2600468616 NM_Sitz_BFSFo_CAB 2000;
BA_REL_ "GenSigTimeoutTime" BU_SG_REL_ SAD SG_ 2600468616 NM_Sitz_BFSFo_CAB 2000;
BA_REL_ "GenSigTimeoutTime" BU_SG_REL_ SAD2 SG_ 2600468616 NM_Sitz_BFSFo_CAB 2000;
BA_REL_ "GenSigTimeoutTime" BU_SG_REL_ SitzMem_BFS SG_ 2600468616 NM_Sitz_BFSFo_CAB 2000;
BA_REL_ "GenSigTimeoutTime" BU_SG_REL_ SitzMem_FS SG_ 2600468616 NM_Sitz_BFSFo_CAB 2000;
BA_REL_ "GenSigTimeoutTime" BU_SG_REL_ SitzMem_HBFS SG_ 2600468616 NM_Sitz_BFSFo_CAB 2000;
BA_REL_ "GenSigTimeoutTime" BU_SG_REL_ SitzMem_HFS SG_ 2600468616 NM_Sitz_BFSFo_CAB 2000;
BA_REL_ "GenSigTimeoutTime" BU_SG_REL_ SitzMem_SR3 SG_ 2600468616 NM_Sitz_BFSFo_CAB 2000;
BA_REL_ "GenSigTimeoutTime" BU_SG_REL_ SpoilerSG SG_ 2600468616 NM_Sitz_BFSFo_CAB 2000;
BA_REL_ "GenSigTimeoutTime" BU_SG_REL_ TSG_BFS SG_ 2600468616 NM_Sitz_BFSFo_CAB 2000;
BA_REL_ "GenSigTimeoutTime" BU_SG_REL_ TSG_FS SG_ 2600468616 NM_Sitz_BFSFo_CAB 2000;
BA_REL_ "GenSigTimeoutTime" BU_SG_REL_ VSG SG_ 2600468616 NM_Sitz_BFSFo_CAB 2000;
BA_REL_ "GenSigTimeoutTime" BU_SG_REL_ VTS SG_ 2600468616 NM_Sitz_BFSFo_CAB 2000;
BA_REL_ "GenSigTimeoutTime" BU_SG_REL_ AAG SG_ 2600468556 NM_Sitzmemo_FS_SNI 2000;
BA_REL_ "GenSigTimeoutTime" BU_SG_REL_ BCM1 SG_ 2600468556 NM_Sitzmemo_FS_SNI 2000;
BA_REL_ "GenSigTimeoutTime" BU_SG_REL_ BCM2 SG_ 2600468556 NM_Sitzmemo_FS_SNI 2000;
BA_REL_ "GenSigTimeoutTime" BU_SG_REL_ ELV SG_ 2600468556 NM_Sitzmemo_FS_SNI 2000;
BA_REL_ "GenSigTimeoutTime" BU_SG_REL_ Gateway SG_ 2600468556 NM_Sitzmemo_FS_SNI 2000;
BA_REL_ "GenSigTimeoutTime" BU_SG_REL_ HDSG SG_ 2600468556 NM_Sitzmemo_FS_SNI 2000;
BA_REL_ "GenSigTimeoutTime" BU_SG_REL_ IEZS SG_ 2600468556 NM_Sitzmemo_FS_SNI 2000;
BA_REL_ "GenSigTimeoutTime" BU_SG_REL_ MFG SG_ 2600468556 NM_Sitzmemo_FS_SNI 2000;
BA_REL_ "GenSigTimeoutTime" BU_SG_REL_ MSBBR SG_ 2600468556 NM_Sitzmemo_FS_SNI 2000;
BA_REL_ "GenSigTimeoutTime" BU_SG_REL_ SAD SG_ 2600468556 NM_Sitzmemo_FS_SNI 2000;
BA_REL_ "GenSigTimeoutTime" BU_SG_REL_ SAD2 SG_ 2600468556 NM_Sitzmemo_FS_SNI 2000;
BA_REL_ "GenSigTimeoutTime" BU_SG_REL_ SitzMem_BFS SG_ 2600468556 NM_Sitzmemo_FS_SNI 2000;
BA_REL_ "GenSigTimeoutTime" BU_SG_REL_ SitzMem_FS SG_ 2600468556 NM_Sitzmemo_FS_SNI 2000;
BA_REL_ "GenSigTimeoutTime" BU_SG_REL_ SitzMem_HBFS SG_ 2600468556 NM_Sitzmemo_FS_SNI 2000;
BA_REL_ "GenSigTimeoutTime" BU_SG_REL_ SitzMem_HFS SG_ 2600468556 NM_Sitzmemo_FS_SNI 2000;
BA_REL_ "GenSigTimeoutTime" BU_SG_REL_ SitzMem_SR3 SG_ 2600468556 NM_Sitzmemo_FS_SNI 2000;
BA_REL_ "GenSigTimeoutTime" BU_SG_REL_ SpoilerSG SG_ 2600468556 NM_Sitzmemo_FS_SNI 2000;
BA_REL_ "GenSigTimeoutTime" BU_SG_REL_ TSG_BFS SG_ 2600468556 NM_Sitzmemo_FS_SNI 2000;
BA_REL_ "GenSigTimeoutTime" BU_SG_REL_ TSG_FS SG_ 2600468556 NM_Sitzmemo_FS_SNI 2000;
BA_REL_ "GenSigTimeoutTime" BU_SG_REL_ VSG SG_ 2600468556 NM_Sitzmemo_FS_SNI 2000;
BA_REL_ "GenSigTimeoutTime" BU_SG_REL_ VTS SG_ 2600468556 NM_Sitzmemo_FS_SNI 2000;
BA_REL_ "GenSigTimeoutTime" BU_SG_REL_ Gateway SG_ 2600468556 NM_Sitzmemo_FS_CBV_AWB 2000;
BA_REL_ "GenSigTimeoutTime" BU_SG_REL_ AAG SG_ 2600468556 NM_Sitzmemo_FS_CBV_CRI 2000;
BA_REL_ "GenSigTimeoutTime" BU_SG_REL_ BCM1 SG_ 2600468556 NM_Sitzmemo_FS_CBV_CRI 2000;
BA_REL_ "GenSigTimeoutTime" BU_SG_REL_ BCM2 SG_ 2600468556 NM_Sitzmemo_FS_CBV_CRI 2000;
BA_REL_ "GenSigTimeoutTime" BU_SG_REL_ ELV SG_ 2600468556 NM_Sitzmemo_FS_CBV_CRI 2000;
BA_REL_ "GenSigTimeoutTime" BU_SG_REL_ Gateway SG_ 2600468556 NM_Sitzmemo_FS_CBV_CRI 2000;
BA_REL_ "GenSigTimeoutTime" BU_SG_REL_ HDSG SG_ 2600468556 NM_Sitzmemo_FS_CBV_CRI 2000;
BA_REL_ "GenSigTimeoutTime" BU_SG_REL_ IEZS SG_ 2600468556 NM_Sitzmemo_FS_CBV_CRI 2000;
BA_REL_ "GenSigTimeoutTime" BU_SG_REL_ MFG SG_ 2600468556 NM_Sitzmemo_FS_CBV_CRI 2000;
BA_REL_ "GenSigTimeoutTime" BU_SG_REL_ MSBBR SG_ 2600468556 NM_Sitzmemo_FS_CBV_CRI 2000;
BA_REL_ "GenSigTimeoutTime" BU_SG_REL_ SAD SG_ 2600468556 NM_Sitzmemo_FS_CBV_CRI 2000;
BA_REL_ "GenSigTimeoutTime" BU_SG_REL_ SAD2 SG_ 2600468556 NM_Sitzmemo_FS_CBV_CRI 2000;
BA_REL_ "GenSigTimeoutTime" BU_SG_REL_ SitzMem_BFS SG_ 2600468556 NM_Sitzmemo_FS_CBV_CRI 2000;
BA_REL_ "GenSigTimeoutTime" BU_SG_REL_ SitzMem_FS SG_ 2600468556 NM_Sitzmemo_FS_CBV_CRI 2000;
BA_REL_ "GenSigTimeoutTime" BU_SG_REL_ SitzMem_HBFS SG_ 2600468556 NM_Sitzmemo_FS_CBV_CRI 2000;
BA_REL_ "GenSigTimeoutTime" BU_SG_REL_ SitzMem_HFS SG_ 2600468556 NM_Sitzmemo_FS_CBV_CRI 2000;
BA_REL_ "GenSigTimeoutTime" BU_SG_REL_ SitzMem_SR3 SG_ 2600468556 NM_Sitzmemo_FS_CBV_CRI 2000;
BA_REL_ "GenSigTimeoutTime" BU_SG_REL_ SpoilerSG SG_ 2600468556 NM_Sitzmemo_FS_CBV_CRI 2000;
BA_REL_ "GenSigTimeoutTime" BU_SG_REL_ TSG_BFS SG_ 2600468556 NM_Sitzmemo_FS_CBV_CRI 2000;
BA_REL_ "GenSigTimeoutTime" BU_SG_REL_ TSG_FS SG_ 2600468556 NM_Sitzmemo_FS_CBV_CRI 2000;
BA_REL_ "GenSigTimeoutTime" BU_SG_REL_ VSG SG_ 2600468556 NM_Sitzmemo_FS_CBV_CRI 2000;
BA_REL_ "GenSigTimeoutTime" BU_SG_REL_ VTS SG_ 2600468556 NM_Sitzmemo_FS_CBV_CRI 2000;
BA_REL_ "GenSigTimeoutTime" BU_SG_REL_ Gateway SG_ 2600468556 NM_Sitzmemo_FS_Car_Wakeup 2000;
BA_REL_ "GenSigTimeoutTime" BU_SG_REL_ AAG SG_ 2600468556 NM_Sitzmemo_FS_CAB 2000;
BA_REL_ "GenSigTimeoutTime" BU_SG_REL_ BCM1 SG_ 2600468556 NM_Sitzmemo_FS_CAB 2000;
BA_REL_ "GenSigTimeoutTime" BU_SG_REL_ BCM2 SG_ 2600468556 NM_Sitzmemo_FS_CAB 2000;
BA_REL_ "GenSigTimeoutTime" BU_SG_REL_ ELV SG_ 2600468556 NM_Sitzmemo_FS_CAB 2000;
BA_REL_ "GenSigTimeoutTime" BU_SG_REL_ Gateway SG_ 2600468556 NM_Sitzmemo_FS_CAB 2000;
BA_REL_ "GenSigTimeoutTime" BU_SG_REL_ HDSG SG_ 2600468556 NM_Sitzmemo_FS_CAB 2000;
BA_REL_ "GenSigTimeoutTime" BU_SG_REL_ IEZS SG_ 2600468556 NM_Sitzmemo_FS_CAB 2000;
BA_REL_ "GenSigTimeoutTime" BU_SG_REL_ MFG SG_ 2600468556 NM_Sitzmemo_FS_CAB 2000;
BA_REL_ "GenSigTimeoutTime" BU_SG_REL_ MSBBR SG_ 2600468556 NM_Sitzmemo_FS_CAB 2000;
BA_REL_ "GenSigTimeoutTime" BU_SG_REL_ SAD SG_ 2600468556 NM_Sitzmemo_FS_CAB 2000;
BA_REL_ "GenSigTimeoutTime" BU_SG_REL_ SAD2 SG_ 2600468556 NM_Sitzmemo_FS_CAB 2000;
BA_REL_ "GenSigTimeoutTime" BU_SG_REL_ SitzMem_BFS SG_ 2600468556 NM_Sitzmemo_FS_CAB 2000;
BA_REL_ "GenSigTimeoutTime" BU_SG_REL_ SitzMem_FS SG_ 2600468556 NM_Sitzmemo_FS_CAB 2000;
BA_REL_ "GenSigTimeoutTime" BU_SG_REL_ SitzMem_HBFS SG_ 2600468556 NM_Sitzmemo_FS_CAB 2000;
BA_REL_ "GenSigTimeoutTime" BU_SG_REL_ SitzMem_HFS SG_ 2600468556 NM_Sitzmemo_FS_CAB 2000;
BA_REL_ "GenSigTimeoutTime" BU_SG_REL_ SitzMem_SR3 SG_ 2600468556 NM_Sitzmemo_FS_CAB 2000;
BA_REL_ "GenSigTimeoutTime" BU_SG_REL_ SpoilerSG SG_ 2600468556 NM_Sitzmemo_FS_CAB 2000;
BA_REL_ "GenSigTimeoutTime" BU_SG_REL_ TSG_BFS SG_ 2600468556 NM_Sitzmemo_FS_CAB 2000;
BA_REL_ "GenSigTimeoutTime" BU_SG_REL_ TSG_FS SG_ 2600468556 NM_Sitzmemo_FS_CAB 2000;
BA_REL_ "GenSigTimeoutTime" BU_SG_REL_ VSG SG_ 2600468556 NM_Sitzmemo_FS_CAB 2000;
BA_REL_ "GenSigTimeoutTime" BU_SG_REL_ VTS SG_ 2600468556 NM_Sitzmemo_FS_CAB 2000;
BA_REL_ "GenSigTimeoutTime" BU_SG_REL_ AAG SG_ 2600468615 NM_Sitz_FSFo_SNI 2000;
BA_REL_ "GenSigTimeoutTime" BU_SG_REL_ BCM1 SG_ 2600468615 NM_Sitz_FSFo_SNI 2000;
BA_REL_ "GenSigTimeoutTime" BU_SG_REL_ BCM2 SG_ 2600468615 NM_Sitz_FSFo_SNI 2000;
BA_REL_ "GenSigTimeoutTime" BU_SG_REL_ ELV SG_ 2600468615 NM_Sitz_FSFo_SNI 2000;
BA_REL_ "GenSigTimeoutTime" BU_SG_REL_ Gateway SG_ 2600468615 NM_Sitz_FSFo_SNI 2000;
BA_REL_ "GenSigTimeoutTime" BU_SG_REL_ HDSG SG_ 2600468615 NM_Sitz_FSFo_SNI 2000;
BA_REL_ "GenSigTimeoutTime" BU_SG_REL_ IEZS SG_ 2600468615 NM_Sitz_FSFo_SNI 2000;
BA_REL_ "GenSigTimeoutTime" BU_SG_REL_ MFG SG_ 2600468615 NM_Sitz_FSFo_SNI 2000;
BA_REL_ "GenSigTimeoutTime" BU_SG_REL_ MSBBR SG_ 2600468615 NM_Sitz_FSFo_SNI 2000;
BA_REL_ "GenSigTimeoutTime" BU_SG_REL_ SAD SG_ 2600468615 NM_Sitz_FSFo_SNI 2000;
BA_REL_ "GenSigTimeoutTime" BU_SG_REL_ SAD2 SG_ 2600468615 NM_Sitz_FSFo_SNI 2000;
BA_REL_ "GenSigTimeoutTime" BU_SG_REL_ SitzMem_BFS SG_ 2600468615 NM_Sitz_FSFo_SNI 2000;
BA_REL_ "GenSigTimeoutTime" BU_SG_REL_ SitzMem_FS SG_ 2600468615 NM_Sitz_FSFo_SNI 2000;
BA_REL_ "GenSigTimeoutTime" BU_SG_REL_ SitzMem_HBFS SG_ 2600468615 NM_Sitz_FSFo_SNI 2000;
BA_REL_ "GenSigTimeoutTime" BU_SG_REL_ SitzMem_HFS SG_ 2600468615 NM_Sitz_FSFo_SNI 2000;
BA_REL_ "GenSigTimeoutTime" BU_SG_REL_ SitzMem_SR3 SG_ 2600468615 NM_Sitz_FSFo_SNI 2000;
BA_REL_ "GenSigTimeoutTime" BU_SG_REL_ SpoilerSG SG_ 2600468615 NM_Sitz_FSFo_SNI 2000;
BA_REL_ "GenSigTimeoutTime" BU_SG_REL_ TSG_BFS SG_ 2600468615 NM_Sitz_FSFo_SNI 2000;
BA_REL_ "GenSigTimeoutTime" BU_SG_REL_ TSG_FS SG_ 2600468615 NM_Sitz_FSFo_SNI 2000;
BA_REL_ "GenSigTimeoutTime" BU_SG_REL_ VSG SG_ 2600468615 NM_Sitz_FSFo_SNI 2000;
BA_REL_ "GenSigTimeoutTime" BU_SG_REL_ VTS SG_ 2600468615 NM_Sitz_FSFo_SNI 2000;
BA_REL_ "GenSigTimeoutTime" BU_SG_REL_ Gateway SG_ 2600468615 NM_Sitz_FSFo_CBV_AWB 2000;
BA_REL_ "GenSigTimeoutTime" BU_SG_REL_ AAG SG_ 2600468615 NM_Sitz_FSFo_CBV_CRI 2000;
BA_REL_ "GenSigTimeoutTime" BU_SG_REL_ BCM1 SG_ 2600468615 NM_Sitz_FSFo_CBV_CRI 2000;
BA_REL_ "GenSigTimeoutTime" BU_SG_REL_ BCM2 SG_ 2600468615 NM_Sitz_FSFo_CBV_CRI 2000;
BA_REL_ "GenSigTimeoutTime" BU_SG_REL_ ELV SG_ 2600468615 NM_Sitz_FSFo_CBV_CRI 2000;
BA_REL_ "GenSigTimeoutTime" BU_SG_REL_ Gateway SG_ 2600468615 NM_Sitz_FSFo_CBV_CRI 2000;
BA_REL_ "GenSigTimeoutTime" BU_SG_REL_ HDSG SG_ 2600468615 NM_Sitz_FSFo_CBV_CRI 2000;
BA_REL_ "GenSigTimeoutTime" BU_SG_REL_ IEZS SG_ 2600468615 NM_Sitz_FSFo_CBV_CRI 2000;
BA_REL_ "GenSigTimeoutTime" BU_SG_REL_ MFG SG_ 2600468615 NM_Sitz_FSFo_CBV_CRI 2000;
BA_REL_ "GenSigTimeoutTime" BU_SG_REL_ MSBBR SG_ 2600468615 NM_Sitz_FSFo_CBV_CRI 2000;
BA_REL_ "GenSigTimeoutTime" BU_SG_REL_ SAD SG_ 2600468615 NM_Sitz_FSFo_CBV_CRI 2000;
BA_REL_ "GenSigTimeoutTime" BU_SG_REL_ SAD2 SG_ 2600468615 NM_Sitz_FSFo_CBV_CRI 2000;
BA_REL_ "GenSigTimeoutTime" BU_SG_REL_ SitzMem_BFS SG_ 2600468615 NM_Sitz_FSFo_CBV_CRI 2000;
BA_REL_ "GenSigTimeoutTime" BU_SG_REL_ SitzMem_FS SG_ 2600468615 NM_Sitz_FSFo_CBV_CRI 2000;
BA_REL_ "GenSigTimeoutTime" BU_SG_REL_ SitzMem_HBFS SG_ 2600468615 NM_Sitz_FSFo_CBV_CRI 2000;
BA_REL_ "GenSigTimeoutTime" BU_SG_REL_ SitzMem_HFS SG_ 2600468615 NM_Sitz_FSFo_CBV_CRI 2000;
BA_REL_ "GenSigTimeoutTime" BU_SG_REL_ SitzMem_SR3 SG_ 2600468615 NM_Sitz_FSFo_CBV_CRI 2000;
BA_REL_ "GenSigTimeoutTime" BU_SG_REL_ SpoilerSG SG_ 2600468615 NM_Sitz_FSFo_CBV_CRI 2000;
BA_REL_ "GenSigTimeoutTime" BU_SG_REL_ TSG_BFS SG_ 2600468615 NM_Sitz_FSFo_CBV_CRI 2000;
BA_REL_ "GenSigTimeoutTime" BU_SG_REL_ TSG_FS SG_ 2600468615 NM_Sitz_FSFo_CBV_CRI 2000;
BA_REL_ "GenSigTimeoutTime" BU_SG_REL_ VSG SG_ 2600468615 NM_Sitz_FSFo_CBV_CRI 2000;
BA_REL_ "GenSigTimeoutTime" BU_SG_REL_ VTS SG_ 2600468615 NM_Sitz_FSFo_CBV_CRI 2000;
BA_REL_ "GenSigTimeoutTime" BU_SG_REL_ Gateway SG_ 2600468615 NM_Sitz_FSFo_Car_Wakeup 2000;
BA_REL_ "GenSigTimeoutTime" BU_SG_REL_ AAG SG_ 2600468615 NM_Sitz_FSFo_CAB 2000;
BA_REL_ "GenSigTimeoutTime" BU_SG_REL_ BCM1 SG_ 2600468615 NM_Sitz_FSFo_CAB 2000;
BA_REL_ "GenSigTimeoutTime" BU_SG_REL_ BCM2 SG_ 2600468615 NM_Sitz_FSFo_CAB 2000;
BA_REL_ "GenSigTimeoutTime" BU_SG_REL_ ELV SG_ 2600468615 NM_Sitz_FSFo_CAB 2000;
BA_REL_ "GenSigTimeoutTime" BU_SG_REL_ Gateway SG_ 2600468615 NM_Sitz_FSFo_CAB 2000;
BA_REL_ "GenSigTimeoutTime" BU_SG_REL_ HDSG SG_ 2600468615 NM_Sitz_FSFo_CAB 2000;
BA_REL_ "GenSigTimeoutTime" BU_SG_REL_ IEZS SG_ 2600468615 NM_Sitz_FSFo_CAB 2000;
BA_REL_ "GenSigTimeoutTime" BU_SG_REL_ MFG SG_ 2600468615 NM_Sitz_FSFo_CAB 2000;
BA_REL_ "GenSigTimeoutTime" BU_SG_REL_ MSBBR SG_ 2600468615 NM_Sitz_FSFo_CAB 2000;
BA_REL_ "GenSigTimeoutTime" BU_SG_REL_ SAD SG_ 2600468615 NM_Sitz_FSFo_CAB 2000;
BA_REL_ "GenSigTimeoutTime" BU_SG_REL_ SAD2 SG_ 2600468615 NM_Sitz_FSFo_CAB 2000;
BA_REL_ "GenSigTimeoutTime" BU_SG_REL_ SitzMem_BFS SG_ 2600468615 NM_Sitz_FSFo_CAB 2000;
BA_REL_ "GenSigTimeoutTime" BU_SG_REL_ SitzMem_FS SG_ 2600468615 NM_Sitz_FSFo_CAB 2000;
BA_REL_ "GenSigTimeoutTime" BU_SG_REL_ SitzMem_HBFS SG_ 2600468615 NM_Sitz_FSFo_CAB 2000;
BA_REL_ "GenSigTimeoutTime" BU_SG_REL_ SitzMem_HFS SG_ 2600468615 NM_Sitz_FSFo_CAB 2000;
BA_REL_ "GenSigTimeoutTime" BU_SG_REL_ SitzMem_SR3 SG_ 2600468615 NM_Sitz_FSFo_CAB 2000;
BA_REL_ "GenSigTimeoutTime" BU_SG_REL_ SpoilerSG SG_ 2600468615 NM_Sitz_FSFo_CAB 2000;
BA_REL_ "GenSigTimeoutTime" BU_SG_REL_ TSG_BFS SG_ 2600468615 NM_Sitz_FSFo_CAB 2000;
BA_REL_ "GenSigTimeoutTime" BU_SG_REL_ TSG_FS SG_ 2600468615 NM_Sitz_FSFo_CAB 2000;
BA_REL_ "GenSigTimeoutTime" BU_SG_REL_ VSG SG_ 2600468615 NM_Sitz_FSFo_CAB 2000;
BA_REL_ "GenSigTimeoutTime" BU_SG_REL_ VTS SG_ 2600468615 NM_Sitz_FSFo_CAB 2000;
VAL_ 1601 MO_Faktor_Momente_02 0 "nicht_belegt" ;
VAL_ 1601 MO_Hybridfahrzeug 0 "kein_Hybridfahrzeug" 1 "Mild_Hybrid" 2 "Full_Hybrid" 3 "PlugIn_Hybrid" ;
VAL_ 1601 MO_Getriebe_Code 0 "Init" 2 "DL501" 3 "DL800" 4 "VL381" 5 "DL382_Front" 6 "DL382_Allrad" 7 "DL702" 8 "AL552_Allrad" 9 "AL552_Front" 10 "AL651" 11 "AL551__AL951__AL1000_8A" 12 "PDK_PAG" 13 "AL551_Hybrid" 15 "Handschalter_konventionell" 16 "AQ250_160" 17 "AQ450" 18 "DQ200" 19 "DQ250" 20 "DQ500" 21 "SQ100" 22 "SQ200" 23 "DQ400E" 32 "Single_Gear__ohne_GSG_WH_am_MSG" ;
VAL_ 1601 MO_StartStopp_Codiert 0 "Start_Stopp_nicht_verbaut" 1 "Start_Stopp_verbaut" ;
VAL_ 1601 MO_Anzahl_Zyl 0 "kein_Zylinder" 1 "1_Zylinder" 2 "2_Zylinder" 3 "3_Zylinder" 4 "4_Zylinder" 5 "5_Zylinder" 6 "6_Zylinder" 7 "7_Zylinder" 8 "8_Zylinder" 9 "9_Zylinder" 10 "10_Zylinder" 11 "11_Zylinder" 12 "12_Zylinder" 13 "15_Zylinder" 14 "16_Zylinder" 15 "18_Zylinder" ;
VAL_ 1601 MO_Kraftstoffart 0 "Diesel" 1 "Benzin_inkl_E25_E85" 2 "CNG" 3 "LPG" 4 "Wasserstoff" 5 "E100_Ethanol" 15 "kein_Verbrennungskraftstoff" ;
VAL_ 1601 MO_Ansaugsystem 0 "Turbo" 1 "Sauger" ;
VAL_ 1601 MO_OBD_Typ 0 "NoOBD_RdW" 1 "EOBD" 2 "US_OBD" 3 "reserviert" ;
VAL_ 1601 MO_DPF_verbaut 0 "kein_DPF_verbaut" 1 "DPF_verbaut" ;
VAL_ 1601 TSK_Codierung 0 "kein_Fahrgeschwindigkeitsregler" 1 "GRA" 2 "GRA_Plus" 3 "Basis_ACC" 4 "ACC_Follow_to_Stop" 5 "ACC_Stop_and_Go" 7 "Codierung_in_Plausibilisierungsphase" ;
VAL_ 394 MO_Ablaufstatus 0 "keine_Aktion" 1 "Aktion_regulaerer_Uebergang" 2 "Aktion_regulaerer_Uebergang" 3 "Aktion_regulaerer_Uebergang" 4 "Aktion_regulaerer_Uebergang" 5 "Aktion_regulaerer_Uebergang" 6 "Aktion_regulaerer_Uebergang" 7 "Aktion_regulaerer_Uebergang" 8 "regulaerer_Uebergang_fertig" 9 "Aktion_Abbruch_Uebergang" 10 "Aktion_Abbruch_Uebergang" 11 "Aktion_Abbruch_Uebergang" 12 "Aktion_Abbruch_Uebergang" 13 "Aktion_Abbruch_Uebergang" 14 "Abbruch_Uebergang_fertig" 15 "Fehler" ;
VAL_ 394 MO_Ablaufstrg_Betriebszustand 0 "Init_Nicht_Betriebsbereit" 1 "Betriebsbereitschaft" 2 "Fahrbetrieb" 7 "Fehler" ;
VAL_ 394 MO_Ablaufstrg_Zustand_VKM_Ist 0 "VKM_aus" 1 "VKM_ein" ;
VAL_ 394 MO_Ablaufstrg_Kraftschluss_Ist 0 "kein_Kraftschluss" 1 "Kraftschluss" ;
VAL_ 394 MO_Ablaufstrg_Zustand_K0_Ist 0 "K0_Kupplung_auf" 1 "K0_Kupplung_zu" ;
VAL_ 394 MO_Ablaufstrg_Kraftschluss2_Ist 0 "Sekundärachse abgekoppelt" 1 "Sekundärachse angekoppelt" ;
VAL_ 394 MO_Ablaufstrg_Zustand_VKM_Ziel 0 "VKM_aus" 1 "VKM_ein" ;
VAL_ 394 MO_Ablaufstrg_Kraftschluss_Ziel 0 "kein_Kraftschluss" 1 "Kraftschluss" ;
VAL_ 394 MO_Ablaufstrg_Zustand_K0_Ziel 0 "K0_Kupplung_auf" 1 "K0_Kupplung_zu" ;
VAL_ 394 MO_Ablaufstrg_Kraftschluss2_Ziel 0 "Anforderung Sekundaerachse abkoppeln" 1 "Anforderung Sekundaerachse ankoppeln" ;
VAL_ 394 MO_Auth_Aufforderung_WFS 0 "Aus" 1 "Ein" ;
VAL_ 394 MO_Start_Dynamik 0 "Komfort" 1 "Dynamik" 2 "Sport" 7 "Notstart" ;
VAL_ 394 MO_Start_Art 0 "Init" 1 "Zustarteinrichtung" 2 "Schlupfstart" 3 "Schleppstart" ;
VAL_ 394 MO_Abstellposition_02 255 "Abstellposition_ungenau" ;
VAL_ 394 MO_Mom_Freiheit_Sekundaerachse 0 "Sekundaerachse ist nicht momentenfrei" 1 "Sekundaerachse ist momentenfrei" ;
VAL_ 394 MO_Tankklappensteuerung 0 "Init_nicht_verbaut" 1 "Tankklappe_soll_entriegeln" 2 "Tankklappe_soll_verriegeln" 3 "keine_Aktion" ;
VAL_ 394 MO_HYB_E_Faktor 0 "null" 1 "plus_1" 2 "plus_2" 3 "plus_3" 4 "plus_4" 5 "plus_5" 6 "plus_6" 7 "plus_7" 8 "minus_8" 9 "minus_7" 10 "minus_6" 11 "minus_5" 12 "minus_4" 13 "minus_3" 14 "minus_2" 15 "minus_1" ;
VAL_ 1157 ND_SatInUse 30 "Init" 31 "Fehler" ;
VAL_ 1157 ND_SatInView 30 "Init" 31 "Fehler" ;
VAL_ 1157 NP_Altitude 4094 "Init" 4095 "Fehler" ;
VAL_ 1158 NP_LatDegree 134217726 "Init" 134217727 "Fehler" ;
VAL_ 1158 NP_LongDegree 268435454 "Init" 268435455 "Fehler" ;
VAL_ 1158 NP_LatDirection 0 "Nord" 1 "Sued" ;
VAL_ 1158 NP_LongDirection 0 "Ost" 1 "West" ;
VAL_ 1158 NP_Sat 30 "Init" 31 "Fehler" ;
VAL_ 1158 NP_Fix 0 "Init" 1 "No_Fix" 2 "2D_Fix" 3 "3D_Fix" ;
VAL_ 2589283496 POS_MUX 0 "MUX_0" 1 "MUX_1" 2 "reserved" 3 "Init" ;
VAL_ 2589283496 POS_ODD_EVEN 0 "ODD" 1 "EVEN" ;
VAL_ 2589283496 POS_PosStati 0 "Init" 1 "NoNavAvailable" 2 "NoMapAvailable" 3 "NavBooting" 4 "NavError" 5 "NavCalibrating" 6 "NavNoGpsResyncSince1h" 7 "NavOffroadParkgarageRampOffset2" 8 "DeadReckoningWithoutGps" 9 "DeadReckoningWithGps" 10 "MapMatchedLowConfidence" 11 "MapMatchedLimitedConfidence" 12 "OffroadHighConfidence" 13 "MapMatchedHighConfidence" 14 "PosInSyncWithGpsAndMAP" ;
VAL_ 2589283496 POS_LatDirection 0 "North" 1 "South" ;
VAL_ 2589283496 POS_LatDegree 134217726 "Init" 134217727 "Fehler" ;
VAL_ 2589283496 POS_Heading_Trust 0 "Init" 1 "TrustLevel01" 2 "TrustLevel02" 3 "Fehler" ;
VAL_ 2589283496 POS_LongDirection 0 "East" 1 "West" ;
VAL_ 2589283496 POS_LongDegree 268435454 "Init" 268435455 "Fehler" ;
VAL_ 2600468551 NM_AAG_SNI 71 "" ;
VAL_ 2600468551 NM_AAG_CBV_AWB 0 "Passiver_WakeUp" 1 "Aktiver_WakeUp" ;
VAL_ 2600468551 NM_AAG_CBV_CRI 0 "Standard_Layout" 1 "TNB_Layout" ;
VAL_ 2600468551 NM_AAG_NM_State 1 "NM_RM_aus_BSM" 2 "NM_RM_aus_PBSM" 4 "NM_NO_aus_RM" 8 "NM_NO_aus_RS" ;
VAL_ 2600468551 NM_AAG_Car_Wakeup 0 "Inaktiv" 1 "Car_Wakeup" ;
VAL_ 2600468551 NM_AAG_UDS_CC 1 "CC_aktiv" ;
VAL_ 2600468551 NM_AAG_NM_aktiv_KL15 0 "Inaktiv" 1 "KL15_EIN" ;
VAL_ 2600468551 NM_AAG_NM_aktiv_Diagnose 1 "Diagnose_aktiv" ;
VAL_ 2600468551 NM_AAG_NM_aktiv_Tmin 0 "Inaktiv" 1 "Mindestaktivzeit" ;
VAL_ 2600468551 NM_AAG_NM_aktiv_Anhaenger_erk 0 "kein_Anhaenger_erkannt" 1 "Anhaenger_erkannt" ;
VAL_ 2600468551 NM_AAG_NM_aktiv_AVS_Fehler 0 "kein_AVS_Fehler_anliegend" 1 "AVS_Fehler_liegt_an" ;
VAL_ 2600468551 NM_AAG_NM_nicht_eingefahren 0 "Kupplung_in_Endlage_Eingefahren" 1 "Kupplung_nicht_in_Endlage_Eingefahren" ;
VAL_ 2600468551 NM_AAG_NM_KL15_unplausibel 0 "KL15 plausibel" 1 "aktiv wegen unplausibler KL15" ;
VAL_ 2600468551 NM_AAG_CAB 1 "CAB_01__Tueren" 2 "CAB_02__Anhaenger" 4 "CAB_03__Nightvision" 8 "CAB_04__Sitzverstellung" 16 "CAB_05__Klappen" 32 "CAB_06__Infotainment" 64 "CAB_07__Sub_Infotainment" 128 "CAB_08__Anzeige" 256 "CAB_09__Laden" ;
VAL_ 2600468494 NM_BCM1_SNI 14 "" ;
VAL_ 2600468494 NM_BCM1_CBV_AWB 0 "Passiver_WakeUp" 1 "Aktiver_WakeUp" ;
VAL_ 2600468494 NM_BCM1_CBV_CRI 0 "Standard_Layout" 1 "TNB_Layout" ;
VAL_ 2600468494 NM_BCM1_NM_State 1 "NM_RM_aus_BSM" 2 "NM_RM_aus_PBSM" 4 "NM_NO_aus_RM" 8 "NM_NO_aus_RS" ;
VAL_ 2600468494 NM_BCM1_Car_Wakeup 0 "Inaktiv" 1 "Car_Wakeup" ;
VAL_ 2600468494 NM_BCM1_UDS_CC 1 "CC_aktiv" ;
VAL_ 2600468494 NM_BCM1_NM_aktiv_KL15 0 "Inaktiv" 1 "KL15_EIN" ;
VAL_ 2600468494 NM_BCM1_NM_aktiv_Diagnose 1 "Diagnose_aktiv" ;
VAL_ 2600468494 NM_BCM1_NM_aktiv_Tmin 0 "Inaktiv" 1 "Mindestaktivzeit" ;
VAL_ 2600468494 NM_BCM1_NM_aktiv_Notlaufblinken 1 "Notlaufblinken_aktiv" ;
VAL_ 2600468494 NM_BCM1_NM_aktiv_ComingHome 1 "ComingHome_aktiv" ;
VAL_ 2600468494 NM_BCM1_NM_aktiv_LeavingHome 1 "LeavingHome_aktiv" ;
VAL_ 2600468494 NM_BCM1_NM_aktiv_Lichthupe 1 "Lichthupe_aktiv" ;
VAL_ 2600468494 NM_BCM1_CAB 1 "CAB_01__Tueren" 2 "CAB_02__Anhaenger" 4 "CAB_03__Nightvision" 8 "CAB_04__Sitzverstellung" 16 "CAB_05__Klappen" 32 "CAB_06__Infotainment" 64 "CAB_07__Sub_Infotainment" 128 "CAB_08__Anzeige" 256 "CAB_09__Laden" ;
VAL_ 2600468619 NM_BCM2_SNI 139 "" ;
VAL_ 2600468619 NM_BCM2_CBV_AWB 0 "Passiver_WakeUp" 1 "Aktiver_WakeUp" ;
VAL_ 2600468619 NM_BCM2_CBV_CRI 0 "Standard_Layout" 1 "TNB_Layout" ;
VAL_ 2600468619 NM_BCM2_NM_State 1 "NM_RM_aus_BSM" 2 "NM_RM_aus_PBSM" 4 "NM_NO_aus_RM" 8 "NM_NO_aus_RS" 16 "NM_RM_aus_RS" 32 "NM_RM_aus_NO" ;
VAL_ 2600468619 NM_BCM2_Car_WakeUp 0 "Inaktiv" 1 "Car_Wakeup" ;
VAL_ 2600468619 NM_BCM2_UDS_CC 1 "CC_aktiv" ;
VAL_ 2600468619 NM_BCM2_NM_aktiv_KL15 0 "Inaktiv" 1 "KL15_EIN" ;
VAL_ 2600468619 NM_BCM2_NM_aktiv_Diagnose 1 "Diagnose_aktiv" ;
VAL_ 2600468619 NM_BCM2_NM_aktiv_Tmin 0 "Inaktiv" 1 "Mindestaktivzeit" ;
VAL_ 2600468619 NM_BCM2_NM_aktiv_Warnblinken 1 "Warnblinken_aktiv" ;
VAL_ 2600468619 NM_BCM2_NM_aktiv_Crashblinken 1 "Crashblinken_aktiv" ;
VAL_ 2600468619 NM_BCM2_NM_aktiv_DWA_Alarm 1 "DWA_Alarm_aktiv" ;
VAL_ 2600468619 NM_BCM2_NM_aktiv_Remot_Door_L_Un 1 "Remote_Door_Lock_Unlock_aktiv" ;
VAL_ 2600468619 NM_BCM2_CAB 1 "CAB_01__Tueren" 2 "CAB_02__Anhaenger" 4 "CAB_03__Nightvision" 8 "CAB_04__Sitzverstellung" 16 "CAB_05__Klappen" 32 "CAB_06__Infotainment" 64 "CAB_07__Sub_Infotainment" 128 "CAB_08__Anzeige" 256 "CAB_09__Laden" ;
VAL_ 2600468529 NM_ELV_SNI 49 "" ;
VAL_ 2600468529 NM_ELV_CBV_AWB 0 "Passiver_WakeUp" 1 "Aktiver_WakeUp" ;
VAL_ 2600468529 NM_ELV_CBV_CRI 0 "Standard_Layout" 1 "TNB_Layout" ;
VAL_ 2600468529 NM_ELV_NM_State 1 "NM_RM_aus_BSM" 2 "NM_RM_aus_PBSM" 4 "NM_NO_aus_RM" 8 "NM_NO_aus_RS" ;
VAL_ 2600468529 NM_ELV_Car_Wakeup 0 "Inaktiv" 1 "Car_Wakeup" ;
VAL_ 2600468529 NM_ELV_UDS_CC 1 "CC_aktiv" ;
VAL_ 2600468529 NM_ELV_NM_aktiv_KL15 0 "Inaktiv" 1 "KL15_EIN" ;
VAL_ 2600468529 NM_ELV_NM_aktiv_Diagnose 1 "Diagnose_aktiv" ;
VAL_ 2600468529 NM_ELV_NM_aktiv_Tmin 0 "Inaktiv" 1 "Mindestaktivzeit" ;
VAL_ 2600468529 NM_ELV_NM_aktiv_Meldung 1 "Meldung_aktiv" ;
VAL_ 2600468529 NM_ELV_NM_aktiv_Verfahrtrigger 1 "Trigger_aktiv" ;
VAL_ 2600468529 NM_ELV_NM_aktiv_WFS 1 "WFS_Komm_aktiv" ;
VAL_ 2600468529 NM_ELV_CAB 1 "CAB_01__Tueren" 2 "CAB_02__Anhaenger" 4 "CAB_03__Nightvision" 8 "CAB_04__Sitzverstellung" 16 "CAB_05__Klappen" 32 "CAB_06__Infotainment" 64 "CAB_07__Sub_Infotainment" 128 "CAB_08__Anzeige" 256 "CAB_09__Laden" ;
VAL_ 2600468496 NM_Gateway_SNI 16 "" ;
VAL_ 2600468496 NM_Gateway_CBV_AWB 0 "Passiver_WakeUp" 1 "Aktiver_WakeUp" ;
VAL_ 2600468496 NM_Gateway_CBV_CRI 0 "Standard_Layout" 1 "TNB_Layout" ;
VAL_ 2600468496 NM_Gateway_NM_State 1 "NM_RM_aus_BSM" 2 "NM_RM_aus_PBSM" 4 "NM_NO_aus_RM" 8 "NM_NO_aus_RS" 16 "NM_RM_aus_RS" 32 "NM_RM_aus_NO" ;
VAL_ 2600468496 NM_Gateway_Car_Wakeup 0 "Inaktiv" 1 "Car_Wakeup" ;
VAL_ 2600468496 NM_Gateway_UDS_CC 1 "CC_aktiv" ;
VAL_ 2600468496 NM_Gateway_NM_aktiv_KL15 0 "Inaktiv" 1 "KL15_EIN" ;
VAL_ 2600468496 NM_Gateway_NM_aktiv_Diagnose 1 "Diagnose_aktiv" ;
VAL_ 2600468496 NM_Gateway_NM_aktiv_Tmin 0 "Inaktiv" 1 "Mindestaktivzeit" ;
VAL_ 2600468496 NM_Gateway_NM_aktiv_CWU 0 "kein_CWU_gesetzt" 1 "CWU_gesetzt" ;
VAL_ 2600468496 NM_Gateway_NM_aktiv_FC 0 "kein_FC_gesetzt" 1 "FC_gesetzt" ;
VAL_ 2600468496 NM_Gateway_CAB 1 "CAB_01__Tueren" 2 "CAB_02__Anhaenger" 4 "CAB_03__Nightvision" 8 "CAB_04__Sitzverstellung" 16 "CAB_05__Klappen" 32 "CAB_06__Infotainment" 64 "CAB_07__Sub_Infotainment" 128 "CAB_08__Anzeige" 256 "CAB_09__Laden" ;
VAL_ 2600468515 NM_HDSG_SNI 35 "" ;
VAL_ 2600468515 NM_HDSG_CBV_AWB 0 "Passiver_WakeUp" 1 "Aktiver_WakeUp" ;
VAL_ 2600468515 NM_HDSG_CBV_CRI 0 "Standard_Layout" 1 "TNB_Layout" ;
VAL_ 2600468515 NM_HDSG_NM_State 1 "NM_RM_aus_BSM" 2 "NM_RM_aus_PBSM" 4 "NM_NO_aus_RM" 8 "NM_NO_aus_RS" ;
VAL_ 2600468515 NM_HDSG_Car_Wakeup 0 "Inaktiv" 1 "Car_Wakeup" ;
VAL_ 2600468515 NM_HDSG_UDS_CC 1 "CC_aktiv" ;
VAL_ 2600468515 NM_HDSG_NM_aktiv_KL15 0 "Inaktiv" 1 "KL15_EIN" ;
VAL_ 2600468515 NM_HDSG_NM_aktiv_Diagnose 1 "Diagnose_aktiv" ;
VAL_ 2600468515 NM_HDSG_NM_aktiv_Tmin 0 "Inaktiv" 1 "Mindestaktivzeit" ;
VAL_ 2600468515 NM_HDSG_Beweg_Heckklappe 0 "keine_Bewegung" 1 "Bewegung_Heckklappe" ;
VAL_ 2600468515 NM_HDSG_CAB 1 "CAB_01__Tueren" 2 "CAB_02__Anhaenger" 4 "CAB_03__Nightvision" 8 "CAB_04__Sitzverstellung" 16 "CAB_05__Klappen" 32 "CAB_06__Infotainment" 64 "CAB_07__Sub_Infotainment" 128 "CAB_08__Anzeige" 256 "CAB_09__Laden" ;
VAL_ 2600468530 NM_Kessy_SNI 50 "" ;
VAL_ 2600468530 NM_Kessy_CBV_AWB 0 "Passiver_WakeUp" 1 "Aktiver_WakeUp" ;
VAL_ 2600468530 NM_Kessy_CBV_CRI 0 "Standard_Layout" 1 "TNB_Layout" ;
VAL_ 2600468530 NM_Kessy_NM_State 1 "NM_RM_aus_BSM" 2 "NM_RM_aus_PBSM" 4 "NM_NO_aus_RM" 8 "NM_NO_aus_RS" ;
VAL_ 2600468530 NM_Kessy_Car_Wakeup 0 "Inaktiv" 1 "Car_Wakeup" ;
VAL_ 2600468530 NM_Kessy_UDS_CC 1 "CC_aktiv" ;
VAL_ 2600468530 NM_Kessy_NM_aktiv_KL15 0 "Inaktiv" 1 "KL15_EIN" ;
VAL_ 2600468530 NM_Kessy_NM_aktiv_Diagnose 1 "Diagnose_aktiv" ;
VAL_ 2600468530 NM_Kessy_NM_aktiv_Tmin 0 "Inaktiv" 1 "Mindestaktivzeit" ;
VAL_ 2600468530 NM_Kessy_NM_aktiv_Meldung 0 "Init" 1 "Meldung_aktiv" ;
VAL_ 2600468530 NM_Kessy_NM_aktiv_Anf_Klemmen 0 "Init" 1 "Anf_Klemmen_aktiv" ;
VAL_ 2600468530 NM_Kessy_NM_aktiv_aut_Abschalt 0 "Init" 1 "aut_Abschalt_aktiv" ;
VAL_ 2600468530 NM_Kessy_CAB 1 "CAB_01__Tueren" 2 "CAB_02__Anhaenger" 4 "CAB_03__Nightvision" 8 "CAB_04__Sitzverstellung" 16 "CAB_05__Klappen" 32 "CAB_06__Infotainment" 64 "CAB_07__Sub_Infotainment" 128 "CAB_08__Anzeige" 256 "CAB_09__Laden" ;
VAL_ 2600468524 NM_MFG_SNI 44 "" ;
VAL_ 2600468524 NM_MFG_CBV_AWB 0 "Passiver_WakeUp" 1 "Aktiver_WakeUp" ;
VAL_ 2600468524 NM_MFG_CBV_CRI 0 "Standard_Layout" 1 "TNB_Layout" ;
VAL_ 2600468524 NM_MFG_NM_State 1 "NM_RM_aus_BSM" 2 "NM_RM_aus_PBSM" 4 "NM_NO_aus_RM" 8 "NM_NO_aus_RS" ;
VAL_ 2600468524 NM_MFG_Car_Wakeup 0 "Inaktiv" 1 "Car_Wakeup" ;
VAL_ 2600468524 NM_MFG_UDS_CC 1 "CC_aktiv" ;
VAL_ 2600468524 NM_MFG_NM_aktiv_KL15 0 "Inaktiv" 1 "KL15_EIN" ;
VAL_ 2600468524 NM_MFG_NM_aktiv_Diagnose 1 "Diagnose_aktiv" ;
VAL_ 2600468524 NM_MFG_NM_aktiv_Tmin 0 "Inaktiv" 1 "Mindestaktivzeit" ;
VAL_ 2600468524 NM_MFG_CAB 1 "CAB_01__Tueren" 2 "CAB_02__Anhaenger" 4 "CAB_03__Nightvision" 8 "CAB_04__Sitzverstellung" 16 "CAB_05__Klappen" 32 "CAB_06__Infotainment" 64 "CAB_07__Sub_Infotainment" 128 "CAB_08__Anzeige" 256 "CAB_09__Laden" ;
VAL_ 2600468612 NM_SAD_SNI 132 "" ;
VAL_ 2600468612 NM_SAD_CBV_AWB 0 "Passiver_WakeUp" 1 "Aktiver_WakeUp" ;
VAL_ 2600468612 NM_SAD_CBV_CRI 0 "Standard_Layout" 1 "TNB_Layout" ;
VAL_ 2600468612 NM_SAD_NM_State 1 "NM_RM_aus_BSM" 2 "NM_RM_aus_PBSM" 4 "NM_NO_aus_RM" 8 "NM_NO_aus_RS" 16 "NM_RM_aus_RS" 32 "NM_RM_aus_NO" ;
VAL_ 2600468612 NM_SAD_Car_Wakeup 0 "Inaktiv" 1 "Car_Wakeup" ;
VAL_ 2600468612 NM_SAD_UDS_CC 1 "CC_aktiv" ;
VAL_ 2600468612 NM_SAD_NM_aktiv_KL15 0 "Inaktiv" 1 "KL15_EIN" ;
VAL_ 2600468612 NM_SAD_NM_aktiv_Diagnose 1 "Diagnose_aktiv" ;
VAL_ 2600468612 NM_SAD_NM_aktiv_Tmin 0 "Inaktiv" 1 "Mindestaktivzeit" ;
VAL_ 2600468612 NM_SAD_NM_aktiv_Dach_geoeffnet 0 "Schiebedach_geschlossen" 1 "Schiebedach_offen" ;
VAL_ 2600468612 NM_SAD_NM_aktiv_Dach_Rollo_fahrt 0 "keine_Aktive_Fahrt" 1 "Aktive_Fahrt" ;
VAL_ 2600468612 NM_SAD_CAB 1 "CAB_01__Tueren" 2 "CAB_02__Anhaenger" 4 "CAB_03__Nightvision" 8 "CAB_04__Sitzverstellung" 16 "CAB_05__Klappen" 32 "CAB_06__Infotainment" 64 "CAB_07__Sub_Infotainment" 128 "CAB_08__Anzeige" 256 "CAB_09__Laden" ;
VAL_ 2600468640 NM_SAD2_SNI 160 "" ;
VAL_ 2600468640 NM_SAD2_CBV_AWB 0 "Passiver_WakeUp" 1 "Aktiver_WakeUp" ;
VAL_ 2600468640 NM_SAD2_CBV_CRI 0 "Standard_Layout" 1 "TNB_Layout" ;
VAL_ 2600468640 NM_SAD2_NM_State 1 "NM_RM_aus_BSM" 2 "NM_RM_aus_PBSM" 4 "NM_NO_aus_RM" 8 "NM_NO_aus_RS" ;
VAL_ 2600468640 NM_SAD2_Car_Wakeup 0 "Inaktiv" 1 "Car_Wakeup" ;
VAL_ 2600468640 NM_SAD2_UDS_CC 1 "CC_aktiv" ;
VAL_ 2600468640 NM_SAD2_NM_aktiv_KL15 0 "Inaktiv" 1 "KL15_EIN" ;
VAL_ 2600468640 NM_SAD2_NM_aktiv_Diagnose 1 "Diagnose_aktiv" ;
VAL_ 2600468640 NM_SAD2_NM_aktiv_Tmin 0 "Inaktiv" 1 "Mindestaktivzeit" ;
VAL_ 2600468640 NM_SAD2_CAB 1 "CAB_01__Tueren" 2 "CAB_02__Anhaenger" 4 "CAB_03__Nightvision" 8 "CAB_04__Sitzverstellung" 16 "CAB_05__Klappen" 32 "CAB_06__Infotainment" 64 "CAB_07__Sub_Infotainment" 128 "CAB_08__Anzeige" 256 "CAB_09__Laden" ;
VAL_ 2600468635 NM_MSBBR_SNI 155 "" ;
VAL_ 2600468635 NM_MSBBR_CBV_AWB 0 "Passiver_WakeUp" 1 "Aktiver_WakeUp" ;
VAL_ 2600468635 NM_MSBBR_CBV_CRI 0 "Standard_Layout" 1 "TNB_Layout" ;
VAL_ 2600468635 NM_MSBBR_NM_State 1 "NM_RM_aus_BSM" 2 "NM_RM_aus_PBSM" 4 "NM_NO_aus_RM" 8 "NM_NO_aus_RS" ;
VAL_ 2600468635 NM_MSBBR_Car_Wakeup 0 "Inaktiv" 1 "Car_Wakeup" ;
VAL_ 2600468635 NM_MSBBR_UDS_CC 1 "CC_aktiv" ;
VAL_ 2600468635 NM_MSBBR_NM_aktiv_KL15 0 "Inaktiv" 1 "KL15_EIN" ;
VAL_ 2600468635 NM_MSBBR_NM_aktiv_Diagnose 1 "Diagnose_aktiv" ;
VAL_ 2600468635 NM_MSBBR_NM_aktiv_Tmin 0 "Inaktiv" 1 "Mindestaktivzeit" ;
VAL_ 2600468635 NM_MSBBR_CAB 1 "CAB_01__Tueren" 2 "CAB_02__Anhaenger" 4 "CAB_03__Nightvision" 8 "CAB_04__Sitzverstellung" 16 "CAB_05__Klappen" 32 "CAB_06__Infotainment" 64 "CAB_07__Sub_Infotainment" 128 "CAB_08__Anzeige" 256 "CAB_09__Laden" ;
VAL_ 2600468557 NM_Sitzmemo_BFS_SNI 77 "" ;
VAL_ 2600468557 NM_Sitzmemo_BFS_CBV_AWB 0 "Passiver_WakeUp" 1 "Aktiver_WakeUp" ;
VAL_ 2600468557 NM_Sitzmemo_BFS_CBV_CRI 0 "Standard_Layout" 1 "TNB_Layout" ;
VAL_ 2600468557 NM_Sitzmemo_BFS_NM_State 1 "NM_RM_aus_BSM" 2 "NM_RM_aus_PBSM" 4 "NM_NO_aus_RM" 8 "NM_NO_aus_RS" ;
VAL_ 2600468557 NM_Sitzmemo_BFS_Car_Wakeup 0 "Inaktiv" 1 "Car_Wakeup" ;
VAL_ 2600468557 NM_Sitzmemo_BFS_UDS_CC 1 "CC_aktiv" ;
VAL_ 2600468557 NM_Sitzmemo_BFS_NM_aktiv_KL15 0 "Inaktiv" 1 "KL15_EIN" ;
VAL_ 2600468557 NM_Sitzmemo_BFS_NM_aktiv_Diag 1 "Diagnose_aktiv" ;
VAL_ 2600468557 NM_Sitzmemo_BFS_NM_aktiv_Tmin 0 "Inaktiv" 1 "Mindestaktivzeit" ;
VAL_ 2600468557 NM_Sitz_BFS_NM_aktiv_Automlauf 0 "Automatiklauf_nicht_aktiv" 1 "Automatiklauf_aktiv" ;
VAL_ 2600468557 NM_Sitz_BFS_NM_aktiv_Handverst 0 "keine Handverstellung_aktiv" 1 "Handverstellung_aktiv" ;
VAL_ 2600468557 NM_Sitz_BFS_NM_aktiv_Visualis 0 "keine_Visualisierung_aktiv" 1 "Visualisierung_aktiv" ;
VAL_ 2600468557 NM_Sitzmemo_BFS_CAB 1 "CAB_01__Tueren" 2 "CAB_02__Anhaenger" 4 "CAB_03__Nightvision" 8 "CAB_04__Sitzverstellung" 16 "CAB_05__Klappen" 32 "CAB_06__Infotainment" 64 "CAB_07__Sub_Infotainment" 128 "CAB_08__Anzeige" 256 "CAB_09__Laden" ;
VAL_ 2600468616 NM_Sitz_BFSFo_SNI 136 "" ;
VAL_ 2600468616 NM_Sitz_BFSFo_CBV_AWB 0 "Passiver_WakeUp" 1 "Aktiver_WakeUp" ;
VAL_ 2600468616 NM_Sitz_BFSFo_CBV_CRI 0 "Standard_Layout" 1 "TNB_Layout" ;
VAL_ 2600468616 NM_Sitz_BFSFo_NM_State 1 "NM_RM_aus_BSM" 2 "NM_RM_aus_PBSM" 4 "NM_NO_aus_RM" 8 "NM_NO_aus_RS" 16 "NM_RM_aus_RS" 32 "NM_RM_aus_NO" ;
VAL_ 2600468616 NM_Sitz_BFSFo_Car_Wakeup 0 "Inaktiv" 1 "Car_Wakeup" ;
VAL_ 2600468616 NM_Sitz_BFSFo_UDS_CC 1 "CC_aktiv" ;
VAL_ 2600468616 NM_Sitz_BFSFo_NM_aktiv_KL15 0 "Inaktiv" 1 "KL15_EIN" ;
VAL_ 2600468616 NM_Sitz_BFSFo_NM_aktiv_Diagnose 1 "Diagnose_aktiv" ;
VAL_ 2600468616 NM_Sitz_BFSFo_NM_aktiv_Tmin 0 "Inaktiv" 1 "Mindestaktivzeit" ;
VAL_ 2600468616 NM_Sitz_BFSFo_NM_aktiv_Automlauf 0 "Automatiklauf_nicht_aktiv" 1 "Automatiklauf_aktiv" ;
VAL_ 2600468616 NM_Sitz_BFSFo_NM_aktiv_Handverst 0 "keine Handverstellung_aktiv" 1 "Handverstellung_aktiv" ;
VAL_ 2600468616 NM_Sitz_BFSFo_NM_aktiv_BR_anfahr 0 "kein_BR_anfahren" 1 "BR_anfahren" ;
VAL_ 2600468616 NM_Sitz_BFSFo_NM_aktiv_Visualis 0 "keine_Visualisierung_aktiv" 1 "Visualisierung_aktiv" ;
VAL_ 2600468616 NM_Sitz_BFSFo_CAB 1 "CAB_01__Tueren" 2 "CAB_02__Anhaenger" 4 "CAB_03__Nightvision" 8 "CAB_04__Sitzverstellung" 16 "CAB_05__Klappen" 32 "CAB_06__Infotainment" 64 "CAB_07__Sub_Infotainment" 128 "CAB_08__Anzeige" 256 "CAB_09__Laden" ;
VAL_ 2600468556 NM_Sitzmemo_FS_SNI 76 "" ;
VAL_ 2600468556 NM_Sitzmemo_FS_CBV_AWB 0 "Passiver_WakeUp" 1 "Aktiver_WakeUp" ;
VAL_ 2600468556 NM_Sitzmemo_FS_CBV_CRI 0 "Standard_Layout" 1 "TNB_Layout" ;
VAL_ 2600468556 NM_Sitzmemo_FS_NM_State 1 "NM_RM_aus_BSM" 2 "NM_RM_aus_PBSM" 4 "NM_NO_aus_RM" 8 "NM_NO_aus_RS" ;
VAL_ 2600468556 NM_Sitzmemo_FS_Car_Wakeup 0 "Inaktiv" 1 "Car_Wakeup" ;
VAL_ 2600468556 NM_Sitzmemo_FS_UDS_CC 1 "CC_aktiv" ;
VAL_ 2600468556 NM_Sitzmemo_FS_NM_aktiv_KL15 0 "Inaktiv" 1 "KL15_EIN" ;
VAL_ 2600468556 NM_Sitzmemo_FS_NM_aktiv_Diag 1 "Diagnose_aktiv" ;
VAL_ 2600468556 NM_Sitzmemo_FS_NM_aktiv_Tmin 0 "Inaktiv" 1 "Mindestaktivzeit" ;
VAL_ 2600468556 NM_Sitzmemo_FS_NM_aktiv_Autolauf 0 "Automatiklauf_nicht_aktiv" 1 "Automatiklauf_aktiv" ;
VAL_ 2600468556 NM_Sitz_FS_NM_aktiv_Handverst 0 "keine Handverstellung_aktiv" 1 "Handverstellung_aktiv" ;
VAL_ 2600468556 NM_Sitz_FS_NM_aktiv_Visualis 0 "keine_Visualisierung_aktiv" 1 "Visualisierung_aktiv" ;
VAL_ 2600468556 NM_Sitz_FS_NM_aktiv_Speichern 0 "kein_Speichern_aktiv" 1 "Speichern_aktiv" ;
VAL_ 2600468556 NM_Sitzmemo_FS_CAB 1 "CAB_01__Tueren" 2 "CAB_02__Anhaenger" 4 "CAB_03__Nightvision" 8 "CAB_04__Sitzverstellung" 16 "CAB_05__Klappen" 32 "CAB_06__Infotainment" 64 "CAB_07__Sub_Infotainment" 128 "CAB_08__Anzeige" 256 "CAB_09__Laden" ;
VAL_ 2600468615 NM_Sitz_FSFo_SNI 135 "" ;
VAL_ 2600468615 NM_Sitz_FSFo_CBV_AWB 0 "Passiver_WakeUp" 1 "Aktiver_WakeUp" ;
VAL_ 2600468615 NM_Sitz_FSFo_CBV_CRI 0 "Standard_Layout" 1 "TNB_Layout" ;
VAL_ 2600468615 NM_Sitz_FSFo_NM_State 1 "NM_RM_aus_BSM" 2 "NM_RM_aus_PBSM" 4 "NM_NO_aus_RM" 8 "NM_NO_aus_RS" 16 "NM_RM_aus_RS" 32 "NM_RM_aus_NO" ;
VAL_ 2600468615 NM_Sitz_FSFo_Car_Wakeup 0 "Inaktiv" 1 "Car_Wakeup" ;
VAL_ 2600468615 NM_Sitz_FSFo_UDS_CC 1 "CC_aktiv" ;
VAL_ 2600468615 NM_Sitz_FSFo_NM_aktiv_KL15 0 "Inaktiv" 1 "KL15_EIN" ;
VAL_ 2600468615 NM_Sitz_FSFo_NM_aktiv_Diagnose 1 "Diagnose_aktiv" ;
VAL_ 2600468615 NM_Sitz_FSFo_NM_aktiv_Tmin 0 "Inaktiv" 1 "Mindestaktivzeit" ;
VAL_ 2600468615 NM_Sitz_FSFo_NM_aktiv_Automlauf 0 "Automatiklauf_nicht_aktiv" 1 "Automatiklauf_aktiv" ;
VAL_ 2600468615 NM_Sitz_FSFo_NM_aktiv_Handverst 0 "keine Handverstellung_aktiv" 1 "Handverstellung_aktiv" ;
VAL_ 2600468615 NM_Sitz_FSFo_NM_aktiv_BR_anfahr 0 "kein_BR_anfahren" 1 "BR_anfahren" ;
VAL_ 2600468615 NM_Sitz_FSFo_NM_aktiv_Visualis 0 "keine_Visualisierung_aktiv" 1 "Visualisierung_aktiv" ;
VAL_ 2600468615 NM_Sitz_FSFo_CAB 1 "CAB_01__Tueren" 2 "CAB_02__Anhaenger" 4 "CAB_03__Nightvision" 8 "CAB_04__Sitzverstellung" 16 "CAB_05__Klappen" 32 "CAB_06__Infotainment" 64 "CAB_07__Sub_Infotainment" 128 "CAB_08__Anzeige" 256 "CAB_09__Laden" ;
